[part 1 of 3: package /ComponentTypes]
AUTOSAR XML (schema 00050)
package /ComponentTypes
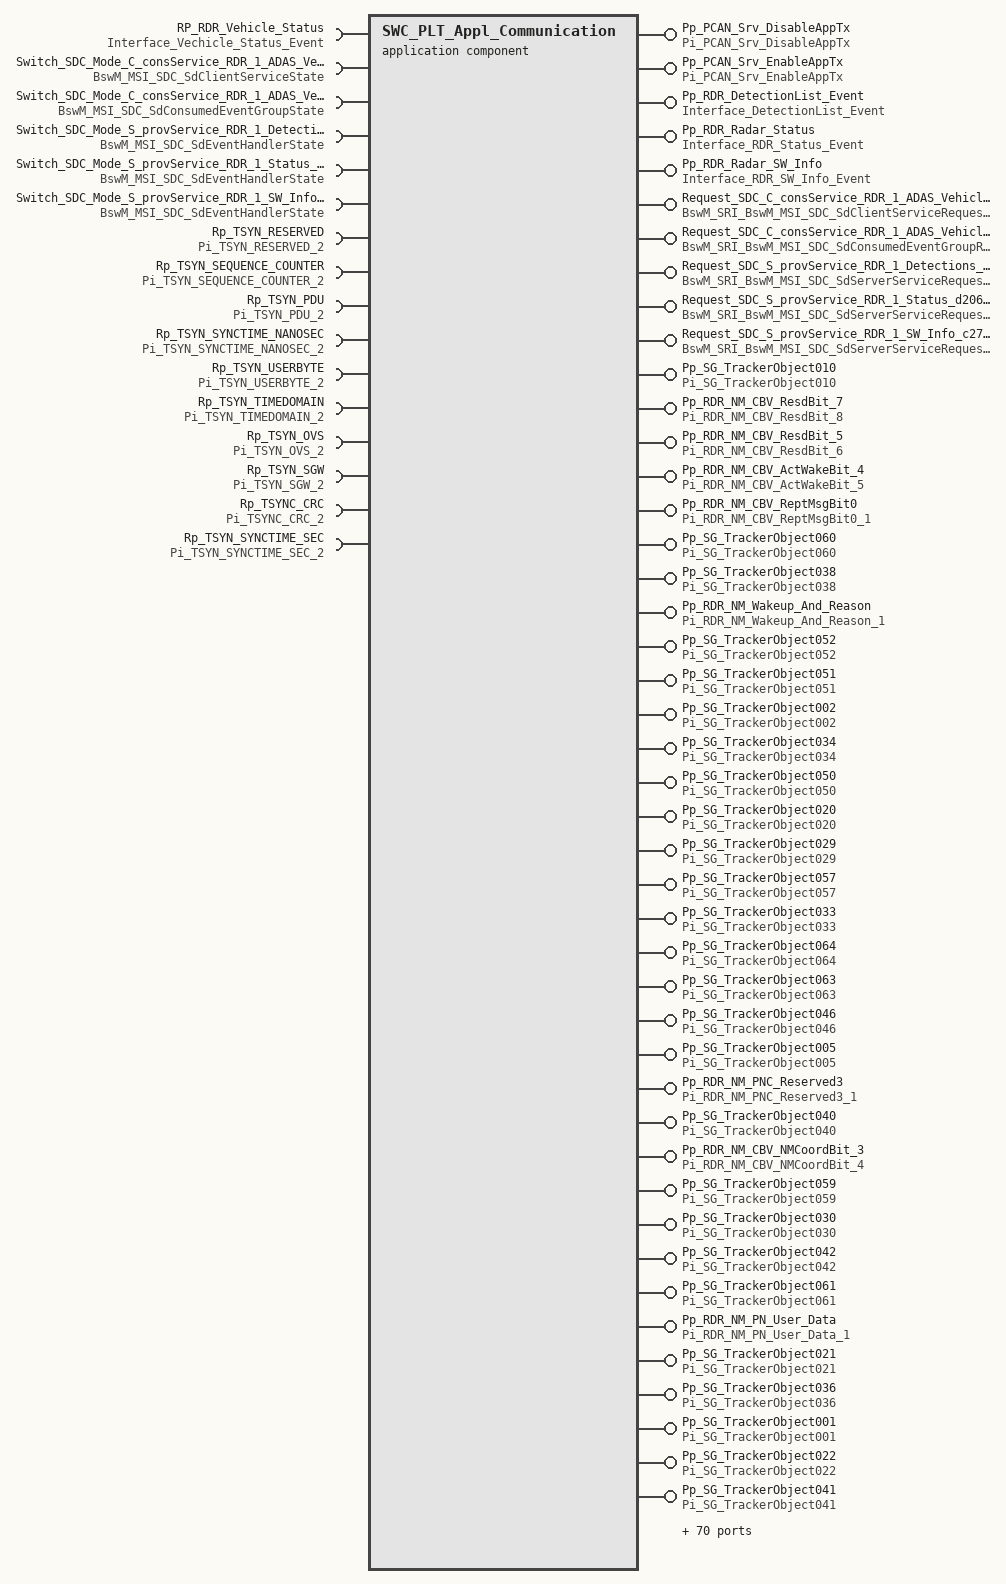
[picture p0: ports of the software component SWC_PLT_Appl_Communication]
  application sw component type SWC_PLT_Appl_Communication
    5 x provide port:
      Pp_PCAN_Srv_DisableAppTx: server-com-spec{operation=Operation, queue-length=1}, provided-interface=Pi_PCAN_Srv_DisableAppTx
      Pp_PCAN_Srv_EnableAppTx: server-com-spec{operation=Operation, queue-length=1}, provided-interface=Pi_PCAN_Srv_EnableAppTx
      Pp_RDR_DetectionList_Event: nonqueued-sender-com-spec{data-element=DetectionList_Event, init-value=fields=[{short-label=DET_HEADER_STRUCT, fields=[{short-label=HED_SENSOR_COVERAGE, fields=[HED_DET_RANGE_MAX:0, HED_DET_RANGE_MIN:0, HED_DET_SPEED_RANGE_MAX:0, HED_DET_SPEED_RANGE_MIN:0, HED_FOV_HOR_MAX:0, HED_FOV_HOR_MIN:0, HED_FOV_VER_MAX:0, HED_FOV_VER_MIN:0]}, {short-label=HED_RADAR_STATE, fields=[HED_DATA_QUALIFIER:0, HED_LOOK_ID:0, HED_LOOK_INDEX:0, HED_NUM_OF_VALID_DETECTIONS:0, HED_SCAN_INDEX:0]}, {short-label=HED_ALIGNMENT, fields=[HED_ALIGN_HOR_QF:0, HED_ALIGN_HOR_REF:0, HED_ALIGN_VER_QF:0, HED_ALIGN_VER_REF:0]}, {short-label=HED_TIMING_PROFILES, fields=[HED_AF_TIME_INST:0, HED_AF_TIME_PEAK:0, HED_MAIN_CORE_TIME_INST:0, HED_MAIN_CORE_TIME_PEAK:0, HED_RDD_CORE_TIME_INST:0, HED_RDD_CORE_TIME_PEAK:0, HED_SP_CORE_TIME_INST:0, HED_SP_CORE_TIME_PEAK:0]}, {short-label=HED_TIMESTAMP, fields=[HED_SENSOR_TIME_STAMP_NS:0, HED_SENSOR_TIME_STAMP_SEC:0, HED_TIME_SYNC_SRC_MASTER:0, HED_TIME_SYNC_VALIDITY_FLAG:0, HED_TRIGGER_TIME:0]}, {short-label=HED_DETECTION_INFO, fields=[HED_DET_BI_STATIC_COUNT:0, HED_DET_NUM_OF_1PASS:0, HED_DET_NUM_OF_2PASS:0, HED_MAX_NUM_OF_DETECTIONS:0, HED_NUM_OF_RESTBINS_USED:0, HED_OPERATION_MODE:0, HED_PROCESSED_RANGE:0, HED_SLOPE_CORR_EXECUTIONFLAG:0]}, {short-label=HED_INTERFACE_VERSION, fields=[HED_INTRFC_VERSION_ID_MAJOR:0, HED_INTRFC_VERSION_ID_MINOR:0, HED_INTRFC_VERSION_ID_PATCH:0]}]}, {short-label=DET_E2E_HDR, fields=[CRC:0, COUNTER:0, DATA_ID:0, LENGTH:0]}, DETECTIONS_ARRAY:400 x fields=[DET_AZIMUTH:0, DET_AZIMUTH_ERR:0, DET_BI_STATIC_FLAG:0, DET_CONFD_AZIMUTH:0, DET_CONFD_ELEVATION:0, DET_ELEVATION:0, DET_ELEVATION_ERR:0, DET_EXISTENCE_PROB:0, DET_HVC_FLAG:0, DET_OUTSIDE_SECTOR:0, DET_POINT_TARGET_PROB:0, DET_RANGE:0, DET_RANGE_ERR:0, DET_RANGE_VELOCITY:0, DET_RANGE_VELOCITY_ERR:0, DET_RCS:0, DET_SNR:0, DET_SUPER_RES_TARGET:0, DET_VALID_FLAG:0]]}, provided-interface=Interface_DetectionList_Event
      Pp_RDR_Radar_Status: nonqueued-sender-com-spec{data-element=RDR_Status, init-value=fields=[{short-label=STS_ALIGNMENT_HANDLER, fields=[STS_AlignmentAzimuth:0, STS_AlignmentElevation:0, STS_AlignmentError:0, STS_AlignmentModeIn:0, STS_AlignmentModeOut:0, STS_AzimuthStd:0, STS_CalDisplay:0, STS_CalTime:0, STS_CoordinateSystemInput:0, STS_ElevationStd:0, 0, 0, 0, 0, 0, 0, STS_ProgressPercent:0, STS_RadarTypeInput:0]}, {short-label=STS_ALIGNMENT_AUTO, fields=[STS_AAAzimuthStd:0, STS_AACurrentAzimuth:0, STS_AACurrentElevation:0, STS_AAElevationStd:0, STS_AlignmentAutoStatus:0, STS_AutoAlignmentFailRootCause:0, STS_AzimuthErrorNegative:0, STS_AzimuthErrorPositive:0, STS_AzimuthUpdates:0, STS_ElevationErrorNegative:0, STS_ElevationErrorPositive:0, STS_ElevationUpdates:0, STS_HostSpdCompensationFactorQF:0, STS_HostSpeedCompensationFactor:0, STS_RollErrorPositive:0, STS_StartAzimuth:0, STS_StartElevation:0]}, {short-label=STS_ALIGNMENT_STATIC, fields=[STS_AlignmentStaticStatus:0, STS_ImpactByInterference:0, STS_Measured_Range:0, STS_MeasuredRangeRate:0, STS_MeasuredRangeRateStd:0, STS_MeasuredRangeStd:0, STS_MeasuredRCS:0, STS_MeasuredRCSStd:0]}, {short-label=STS_ALIGNMENT_SERVICE, fields=[STS_AlignmentServiceStatus:0, STS_AverageNumberOfDetections:0, STS_AverageSpeed:0, STS_DistanceAbsolute:0, STS_DistanceEffective:0, STS_DurationAbsolute:0, STS_DurationEffective:0, STS_VehicleCondition:0]}, {short-label=STS_ALIGN_SHORT_TRACK, fields=STS_AlignmentShortTrackStatus:0}, {short-label=STS_CAPAB_RDR_PERF, fields=[CAP_BlockageActive:0, CAP_BlockageProbability:0, CAP_BlockageSensitivity:0, CAP_BlockageStatus:0, CAP_BlockageValue:0, CAP_FreeSightCheckActive:0, CAP_FreeSightCheckStatus:0, CAP_SLBlockageFilterValue:0, CAP_SLBlockageFlag:0]}, {short-label=STS_CAPAB_DAMPING, fields=[CAP_DampingActive:0, CAP_DampingCurrent:0, CAP_DampingStandardDeviation:0, CAP_DampingStatus:0]}, {short-label=STS_CAPAB_RANGE_DET, fields=[CAP_AngleAzimuthRangeEnd:0, CAP_AngleAzimuthRangeStart:0, CAP_MaxDetectionRangeCar:[0, 0, 0], CAP_MaxDetRangeMotorbike:[0, 0, 0], CAP_MaxDetRangePedestrian:[0, 0, 0], CAP_RangeEstimationActive:0, CAP_RangeEstimationStatus:0]}, {short-label=STS_CAPAB_SLL_MONITOR, fields=[CAP_SideLobeLevelBeamformer:0, CAP_SLLMonitoringActive:0, CAP_SLLMonitoringStatus:0]}, {short-label=STS_TIMESYNC_STATUS, fields=[STS_NO_TSYN_ERROR:0, STS_POINT_OF_TRIGGER:0, STS_TIME_SYNC_OFFSET:0]}, {short-label=STS_SENSOR_PERF, fields=STS_BRR_STATUS:0}, {short-label=STS_TEMPERATURE, fields=[STS_MCU_TEMP:0, STS_MMIC_TEMP_RX:0, STS_MMIC_TEMP_TX0:0, STS_MMIC_TEMP_TX1_2:0, STS_MMIC_TEMP_TX3_4:0]}, {short-label=STS_FAULTS, fields=STS_CORE_ACTIVE_FAULTS:0}, {short-label=STS_RADAR_PROFILE, fields=[STS_AF_CORE_THROUGHPUT:0, 0, STS_RDD_CORE_THROUGHPUT:0, STS_SCAN_TYPE:0, STS_XCVR_OPERATIONAL:0]}, {short-label=STS_VEHICLE, fields=[STS_STEERING_ANGLE:0, STS_STEERING_ANGLE_SIGN:0, STS_VEH_SPEED_DIRECTION:0, STS_VEHICLE_SPEED_CALC:0, STS_VEHICLE_SUPPLY_VOLTAGE:0, STS_YAW_RATE_BIAS:0]}, {short-label=STS_E2E_HDR, fields=[CRC:0, COUNTER:0, DATA_ID:0, LENGTH:0]}]}, provided-interface=Interface_RDR_Status_Event
      Pp_RDR_Radar_SW_Info: nonqueued-sender-com-spec{data-element=RDR_SW_Info, init-value=fields=[{short-label=INFO_CALIBRATION_VERSION, fields=[STS_SMC_CAL_VER_MAJOR:0, STS_SMC_CAL_VER_MINOR:0, STS_SMC_PLATFROM_VERSION:0, STS_SMC_SECTION_COMPTBLITY:0, STS_USC_CAL_VER_MAJOR:0, STS_USC_CAL_VER_MINOR:0, STS_USC_SECTION_COMPTBLITY:0]}, {short-label=INFO_MOUNTING_POS, fields=[STS_SENSOR_HEIGHT:0, STS_SENSOR_MOUNT_LOCATION:0, STS_SENSOR_MOUNT_ORNT_PITCH:0, STS_SENSOR_MOUNT_ORNT_ROLL:0, STS_SENSOR_MOUNT_ORNT_YAW:0, STS_SENSOR_MOUNT_POS_X:0, STS_SENSOR_MOUNT_POS_Y:0, STS_SENSOR_MOUNT_POS_Z:0, STS_SENSOR_POSITION:0]}, {short-label=INFO_SW_VERSION, fields=[STS_PBL_VERSION_FIELD1:0, STS_PBL_VERSION_FIELD2:0, STS_PBL_VERSION_FIELD3:0, STS_PBL_VERSION_FIELD4:0, STS_SW_VERSION_FIELD1:0, STS_SW_VERSION_FIELD2:0, STS_SW_VERSION_FIELD3:0, STS_SW_VERSION_FIELD4:0]}, {short-label=INFO_HW_CAN_VERSION, fields=[STS_DET_DBC_BASE_VER_MAJOR:0, STS_DET_DBC_BASE_VER_MINOR:0, STS_HARDWARE_VERSION:0, STS_PCAN_PROTOCOL_VER_MAJOR:0, STS_PCAN_PROTOCOL_VER_MINOR:0, STS_PLATFORM_VARIANT:0, STS_SERIAL_NUM_JULIAN_DAY:0, STS_SERIAL_NUM_JULIAN_YEAR:0, STS_SERIAL_NUMBER_SEQUENCE:0]}, {short-label=INFO_E2E_HDR, fields=[CRC:0, COUNTER:0, DATA_ID:0, LENGTH:0]}]}, provided-interface=Interface_RDR_SW_Info_Event
    require port RP_RDR_Vehicle_Status: nonqueued-receiver-com-spec{data-element=Vehicle_Status, filter=data-filter-type=ALWAYS, init-value=fields=[{short-label=System_Status_Vehicle, fields=[SSTS_STEERING_ANGLE:0, SSTS_STEERING_ANGLE_SIGN:0, SSTS_VEH_ODOMETER:0, SSTS_VEH_POWER_MODE_STATUS:0, SSTS_VEH_SPD_COMP_FACTOR:0, SSTS_VEH_SYSTEM_VOLTAGE:0, SSTS_VEHICLE_SPEED_CALC:0, SSTS_VEHICLE_SPEED_CALC_QF:0, SSTS_VEHICLE_STATE:0, SSTS_YAW_RATE_BIAS:0, SSTS_YAW_RATE_CALC:0, SSTS_YAW_RATE_CALC_QF:0]}, {short-label=System_Status_Vehicle_State, fields=[SSTS_DRIVE_DIR:0, SSTS_DRIVE_REVERSE:0, SSTS_GEAR_POSITION:0, SSTS_IGN_STATUS:0, SSTS_LROS_DRIVE_DIR:0, SSTS_LROS_DRIVE_REVERSE:0]}, {short-label=System_Status_ADAS_Version, fields=[SSTS_CAN_PCAN_MINOR_ADAS:0, SSTS_CAN_PCAN_MAJOR_ADAS:0, SSTS_SW_VERSION_ADAS:0]}, {short-label=System_Status_Absolute_Time, fields=[SSTS_VEH_AbsoluteTime_Day:0, SSTS_VEH_AbsoluteTime_Hour:0, SSTS_VEH_AbsoluteTime_Minute:0, SSTS_VEH_AbsoluteTime_Month:0, SSTS_VEH_AbsoluteTime_Second:0, SSTS_VEH_AbsoluteTime_Year:0]}, {short-label=SSTS_E2E_HDR, fields=[CRC:0, COUNTER:0, DATA_ID:0, LENGTH:0]}]}, required-interface=Interface_Vechicle_Status_Event
    5 x provide port, all with nonqueued-sender-com-spec=data-element=requestedMode:
      Request_SDC_C_consService_RDR_1_ADAS_Vehicle_Status_2b1e055b: provided-interface=BswM_SRI_BswM_MSI_SDC_SdClientServiceRequest_BswM_MDGP_SDC_SdClientServiceRequest
      Request_SDC_C_consService_RDR_1_ADAS_Vehicle_Status_2b1e055b_CEG_consServiceGrp_RDR_1_ADAS_Vehicle_Status_4b79da85: provided-interface=BswM_SRI_BswM_MSI_SDC_SdConsumedEventGroupRequest_BswM_MDGP_SDC_SdConsumedEventGroupRequest
      Request_SDC_S_provService_RDR_1_Detections_89f78c9f: provided-interface=BswM_SRI_BswM_MSI_SDC_SdServerServiceRequest_BswM_MDGP_SDC_SdServerServiceRequest
      Request_SDC_S_provService_RDR_1_Status_d2069d01: provided-interface=BswM_SRI_BswM_MSI_SDC_SdServerServiceRequest_BswM_MDGP_SDC_SdServerServiceRequest
      Request_SDC_S_provService_RDR_1_SW_Info_c2745ec9: provided-interface=BswM_SRI_BswM_MSI_SDC_SdServerServiceRequest_BswM_MDGP_SDC_SdServerServiceRequest
    15 x require port:
      Switch_SDC_Mode_C_consService_RDR_1_ADAS_Vehicle_Status_2b1e055b: mode-switch-receiver-com-spec=BswM_MDGP_SDC_SdClientServiceState, required-interface=BswM_MSI_SDC_SdClientServiceState
      Switch_SDC_Mode_C_consService_RDR_1_ADAS_Vehicle_Status_2b1e055b_CEG_consServiceGrp_RDR_1_ADAS_Vehicle_Status_4b79da85: mode-switch-receiver-com-spec=BswM_MDGP_SDC_SdConsumedEventGroupState, required-interface=BswM_MSI_SDC_SdConsumedEventGroupState
      Switch_SDC_Mode_S_provService_RDR_1_Detections_89f78c9f_EH_EventGroup_RDR_1_ca62382d: mode-switch-receiver-com-spec=BswM_MDGP_SDC_SdEventHandlerState, required-interface=BswM_MSI_SDC_SdEventHandlerState
      Switch_SDC_Mode_S_provService_RDR_1_Status_d2069d01_EH_EventGroup_RDR_1_f7c73cae: mode-switch-receiver-com-spec=BswM_MDGP_SDC_SdEventHandlerState, required-interface=BswM_MSI_SDC_SdEventHandlerState
      Switch_SDC_Mode_S_provService_RDR_1_SW_Info_c2745ec9_EH_EventGroup_RDR_1_653e2581: mode-switch-receiver-com-spec=BswM_MDGP_SDC_SdEventHandlerState, required-interface=BswM_MSI_SDC_SdEventHandlerState
      Rp_TSYN_RESERVED: nonqueued-receiver-com-spec{data-element=Vdp_TSYN_RESERVED, init-value=0}, required-interface=Pi_TSYN_RESERVED_2
      Rp_TSYN_SEQUENCE_COUNTER: nonqueued-receiver-com-spec{data-element=Vdp_TSYN_SEQUENCE_COUNTER, init-value=0}, required-interface=Pi_TSYN_SEQUENCE_COUNTER_2
      Rp_TSYN_PDU: nonqueued-receiver-com-spec{data-element=Vdp_TSYN_PDU, init-value=40}, required-interface=Pi_TSYN_PDU_2
      Rp_TSYN_SYNCTIME_NANOSEC: nonqueued-receiver-com-spec{data-element=Vdp_TSYN_SYNCTIME_NANOSEC, init-value=0}, required-interface=Pi_TSYN_SYNCTIME_NANOSEC_2
      Rp_TSYN_USERBYTE: nonqueued-receiver-com-spec{data-element=Vdp_TSYN_USERBYTE, init-value=0}, required-interface=Pi_TSYN_USERBYTE_2
      Rp_TSYN_TIMEDOMAIN: nonqueued-receiver-com-spec{data-element=Vdp_TSYN_TIMEDOMAIN, init-value=0}, required-interface=Pi_TSYN_TIMEDOMAIN_2
      Rp_TSYN_OVS: nonqueued-receiver-com-spec{data-element=Vdp_TSYN_OVS, init-value=0}, required-interface=Pi_TSYN_OVS_2
      Rp_TSYN_SGW: nonqueued-receiver-com-spec{data-element=Vdp_TSYN_SGW, init-value=0}, required-interface=Pi_TSYN_SGW_2
      Rp_TSYNC_CRC: nonqueued-receiver-com-spec{data-element=Vdp_TSYNC_CRC, init-value=0}, required-interface=Pi_TSYNC_CRC_2
      Rp_TSYN_SYNCTIME_SEC: nonqueued-receiver-com-spec{data-element=Vdp_TSYN_SYNCTIME_SEC, init-value=0}, required-interface=Pi_TSYN_SYNCTIME_SEC_2
    182 x provide port:
      Pp_SG_TrackerObject010: nonqueued-sender-com-spec{data-element=Vdp_SG_TrackerObject010, init-value=fields=[OBJ_ACCEL_ERR_CRR_COEF_010:120, OBJ_ACCELERATION_LAT_010:400, OBJ_ACCELERATION_LAT_ERR_010:0, OBJ_ACCELERATION_LONG_010:400, OBJ_ACCELERATION_LONG_ERR_010:0, OBJ_ALIVE_TIME_010:0, OBJ_CLS_TYPE1_010:0, OBJ_CLS_TYPE1_PROB_010:0, OBJ_CLS_TYPE2_010:0, OBJ_CLS_TYPE2_PROB_010:0, OBJ_CLS_TYPE3_010:0, OBJ_CLS_TYPE3_PROB_010:0, OBJ_CLS_TYPE4_010:0, OBJ_CLS_TYPE4_PROB_010:0, OBJ_CLS_TYPE5_010:0, OBJ_CLS_TYPE5_PROB_010:0, OBJ_CLS_TYPE6_010:0, OBJ_CLS_TYPE6_PROB_010:0, OBJ_DIMENSION_LENGTH_010:0, OBJ_DIMENSION_LENGTH_ERR_010:0, OBJ_DIMENSION_WIDTH_010:0, OBJ_DIMENSION_WIDTH_ERR_010:0, OBJ_EXISTENCE_PROB_010:0, OBJ_GROUP_ID_010:0, OBJ_ID_010:0, OBJ_MEASUREMENT_STATUS_010:0, OBJ_MH_CRC16_010:0, OBJ_MH_CYCLE_COUNTER_010:0, OBJ_MOVEMENT_STATUS_010:0, OBJ_POS_ERR_CRR_COEF_010:120, OBJ_POS_LAT_010:32700, OBJ_POS_LAT_ERR_010:0, OBJ_POS_LONG_010:32700, OBJ_POS_LONG_ERR_010:0, OBJ_RCS_010:64, OBJ_REF_PT_LAT_OFFSET_010:0, OBJ_REF_PT_LONG_OFFSET_010:0, OBJ_TIMESTAMP_OFFSET_010:127, OBJ_TRACK_MOTION_MODEL_010:0, OBJ_VEH_TRACK_FLAG_010:0, OBJ_VELOCITY_ERR_CRR_COEF_010:120, OBJ_VELOCITY_LAT_010:16300, OBJ_VELOCITY_LAT_ERR_010:0, OBJ_VELOCITY_LONG_010:16300, OBJ_VELOCITY_LONG_ERR_010:0, OBJ_YAW_ANGLE_010:2000, OBJ_YAW_ANGLE_ERR_010:0, OBJ_YAW_RATE_010:448, OBJ_YAW_RATE_ERR_010:0]}, provided-interface=Pi_SG_TrackerObject010
      Pp_RDR_NM_CBV_ResdBit_7: nonqueued-sender-com-spec{data-element=Vdp_RDR_NM_CBV_ResdBit_7, init-value=0}, provided-interface=Pi_RDR_NM_CBV_ResdBit_8
      Pp_RDR_NM_CBV_ResdBit_5: nonqueued-sender-com-spec{data-element=Vdp_RDR_NM_CBV_ResdBit_5, init-value=0}, provided-interface=Pi_RDR_NM_CBV_ResdBit_6
      Pp_RDR_NM_CBV_ActWakeBit_4: nonqueued-sender-com-spec{data-element=Vdp_RDR_NM_CBV_ActWakeBit_4, init-value=0}, provided-interface=Pi_RDR_NM_CBV_ActWakeBit_5
      Pp_RDR_NM_CBV_ReptMsgBit0: nonqueued-sender-com-spec{data-element=Vdp_RDR_NM_CBV_ReptMsgBit0, init-value=0}, provided-interface=Pi_RDR_NM_CBV_ReptMsgBit0_1
      Pp_SG_TrackerObject060: nonqueued-sender-com-spec{data-element=Vdp_SG_TrackerObject060, init-value=fields=[OBJ_ACCEL_ERR_CRR_COEF_060:120, OBJ_ACCELERATION_LAT_060:400, OBJ_ACCELERATION_LAT_ERR_060:0, OBJ_ACCELERATION_LONG_060:400, OBJ_ACCELERATION_LONG_ERR_060:0, OBJ_ALIVE_TIME_060:0, OBJ_CLS_TYPE1_060:0, OBJ_CLS_TYPE1_PROB_060:0, OBJ_CLS_TYPE2_060:0, OBJ_CLS_TYPE2_PROB_060:0, OBJ_CLS_TYPE3_060:0, OBJ_CLS_TYPE3_PROB_060:0, OBJ_CLS_TYPE4_060:0, OBJ_CLS_TYPE4_PROB_060:0, OBJ_CLS_TYPE5_060:0, OBJ_CLS_TYPE5_PROB_060:0, OBJ_CLS_TYPE6_060:0, OBJ_CLS_TYPE6_PROB_060:0, OBJ_DIMENSION_LENGTH_060:0, OBJ_DIMENSION_LENGTH_ERR_060:0, OBJ_DIMENSION_WIDTH_060:0, OBJ_DIMENSION_WIDTH_ERR_060:0, OBJ_EXISTENCE_PROB_060:0, OBJ_GROUP_ID_060:0, OBJ_ID_060:0, OBJ_MEASUREMENT_STATUS_060:0, OBJ_MH_CRC16_060:0, OBJ_MH_CYCLE_COUNTER_060:0, OBJ_MOVEMENT_STATUS_060:0, OBJ_POS_ERR_CRR_COEF_060:120, OBJ_POS_LAT_060:32700, OBJ_POS_LAT_ERR_060:0, OBJ_POS_LONG_060:32700, OBJ_POS_LONG_ERR_060:0, OBJ_RCS_060:64, OBJ_REF_PT_LAT_OFFSET_060:0, OBJ_REF_PT_LONG_OFFSET_060:0, OBJ_TIMESTAMP_OFFSET_060:127, OBJ_TRACK_MOTION_MODEL_060:0, OBJ_VEH_TRACK_FLAG_060:0, OBJ_VELOCITY_ERR_CRR_COEF_060:120, OBJ_VELOCITY_LAT_060:16300, OBJ_VELOCITY_LAT_ERR_060:0, OBJ_VELOCITY_LONG_060:16300, OBJ_VELOCITY_LONG_ERR_060:0, OBJ_YAW_ANGLE_060:2000, OBJ_YAW_ANGLE_ERR_060:0, OBJ_YAW_RATE_060:448, OBJ_YAW_RATE_ERR_060:0]}, provided-interface=Pi_SG_TrackerObject060
      Pp_SG_TrackerObject038: nonqueued-sender-com-spec{data-element=Vdp_SG_TrackerObject038, init-value=fields=[OBJ_ACCEL_ERR_CRR_COEF_038:120, OBJ_ACCELERATION_LAT_038:400, OBJ_ACCELERATION_LAT_ERR_038:0, OBJ_ACCELERATION_LONG_038:400, OBJ_ACCELERATION_LONG_ERR_038:0, OBJ_ALIVE_TIME_038:0, OBJ_CLS_TYPE1_038:0, OBJ_CLS_TYPE1_PROB_038:0, OBJ_CLS_TYPE2_038:0, OBJ_CLS_TYPE2_PROB_038:0, OBJ_CLS_TYPE3_038:0, OBJ_CLS_TYPE3_PROB_038:0, OBJ_CLS_TYPE4_038:0, OBJ_CLS_TYPE4_PROB_038:0, OBJ_CLS_TYPE5_038:0, OBJ_CLS_TYPE5_PROB_038:0, OBJ_CLS_TYPE6_038:0, OBJ_CLS_TYPE6_PROB_038:0, OBJ_DIMENSION_LENGTH_038:0, OBJ_DIMENSION_LENGTH_ERR_038:0, OBJ_DIMENSION_WIDTH_038:0, OBJ_DIMENSION_WIDTH_ERR_038:0, OBJ_EXISTENCE_PROB_038:0, OBJ_GROUP_ID_038:0, OBJ_ID_038:0, OBJ_MEASUREMENT_STATUS_038:0, OBJ_MH_CRC16_038:0, OBJ_MH_CYCLE_COUNTER_038:0, OBJ_MOVEMENT_STATUS_038:0, OBJ_POS_ERR_CRR_COEF_038:120, OBJ_POS_LAT_038:32700, OBJ_POS_LAT_ERR_038:0, OBJ_POS_LONG_038:32700, OBJ_POS_LONG_ERR_038:0, OBJ_RCS_038:64, OBJ_REF_PT_LAT_OFFSET_038:0, OBJ_REF_PT_LONG_OFFSET_038:0, OBJ_TIMESTAMP_OFFSET_038:127, OBJ_TRACK_MOTION_MODEL_038:0, OBJ_VEH_TRACK_FLAG_038:0, OBJ_VELOCITY_ERR_CRR_COEF_038:120, OBJ_VELOCITY_LAT_038:16300, OBJ_VELOCITY_LAT_ERR_038:0, OBJ_VELOCITY_LONG_038:16300, OBJ_VELOCITY_LONG_ERR_038:0, OBJ_YAW_ANGLE_038:2000, OBJ_YAW_ANGLE_ERR_038:0, OBJ_YAW_RATE_038:448, OBJ_YAW_RATE_ERR_038:0]}, provided-interface=Pi_SG_TrackerObject038
      Pp_RDR_NM_Wakeup_And_Reason: nonqueued-sender-com-spec{data-element=Vdp_RDR_NM_Wakeup_And_Reason, init-value=0}, provided-interface=Pi_RDR_NM_Wakeup_And_Reason_1
      Pp_SG_TrackerObject052: nonqueued-sender-com-spec{data-element=Vdp_SG_TrackerObject052, init-value=fields=[OBJ_ACCEL_ERR_CRR_COEF_052:120, OBJ_ACCELERATION_LAT_052:400, OBJ_ACCELERATION_LAT_ERR_052:0, OBJ_ACCELERATION_LONG_052:400, OBJ_ACCELERATION_LONG_ERR_052:0, OBJ_ALIVE_TIME_052:0, OBJ_CLS_TYPE1_052:0, OBJ_CLS_TYPE1_PROB_052:0, OBJ_CLS_TYPE2_052:0, OBJ_CLS_TYPE2_PROB_052:0, OBJ_CLS_TYPE3_052:0, OBJ_CLS_TYPE3_PROB_052:0, OBJ_CLS_TYPE4_052:0, OBJ_CLS_TYPE4_PROB_052:0, OBJ_CLS_TYPE5_052:0, OBJ_CLS_TYPE5_PROB_052:0, OBJ_CLS_TYPE6_052:0, OBJ_CLS_TYPE6_PROB_052:0, OBJ_DIMENSION_LENGTH_052:0, OBJ_DIMENSION_LENGTH_ERR_052:0, OBJ_DIMENSION_WIDTH_052:0, OBJ_DIMENSION_WIDTH_ERR_052:0, OBJ_EXISTENCE_PROB_052:0, OBJ_GROUP_ID_052:0, OBJ_ID_052:0, OBJ_MEASUREMENT_STATUS_052:0, OBJ_MH_CRC16_052:0, OBJ_MH_CYCLE_COUNTER_052:0, OBJ_MOVEMENT_STATUS_052:0, OBJ_POS_ERR_CRR_COEF_052:120, OBJ_POS_LAT_052:32700, OBJ_POS_LAT_ERR_052:0, OBJ_POS_LONG_052:32700, OBJ_POS_LONG_ERR_052:0, OBJ_RCS_052:64, OBJ_REF_PT_LAT_OFFSET_052:0, OBJ_REF_PT_LONG_OFFSET_052:0, OBJ_TIMESTAMP_OFFSET_052:127, OBJ_TRACK_MOTION_MODEL_052:0, OBJ_VEH_TRACK_FLAG_052:0, OBJ_VELOCITY_ERR_CRR_COEF_052:120, OBJ_VELOCITY_LAT_052:16300, OBJ_VELOCITY_LAT_ERR_052:0, OBJ_VELOCITY_LONG_052:16300, OBJ_VELOCITY_LONG_ERR_052:0, OBJ_YAW_ANGLE_052:2000, OBJ_YAW_ANGLE_ERR_052:0, OBJ_YAW_RATE_052:448, OBJ_YAW_RATE_ERR_052:0]}, provided-interface=Pi_SG_TrackerObject052
      Pp_SG_TrackerObject051: nonqueued-sender-com-spec{data-element=Vdp_SG_TrackerObject051, init-value=fields=[OBJ_ACCEL_ERR_CRR_COEF_051:120, OBJ_ACCELERATION_LAT_051:400, OBJ_ACCELERATION_LAT_ERR_051:0, OBJ_ACCELERATION_LONG_051:400, OBJ_ACCELERATION_LONG_ERR_051:0, OBJ_ALIVE_TIME_051:0, OBJ_CLS_TYPE1_051:0, OBJ_CLS_TYPE1_PROB_051:0, OBJ_CLS_TYPE2_051:0, OBJ_CLS_TYPE2_PROB_051:0, OBJ_CLS_TYPE3_051:0, OBJ_CLS_TYPE3_PROB_051:0, OBJ_CLS_TYPE4_051:0, OBJ_CLS_TYPE4_PROB_051:0, OBJ_CLS_TYPE5_051:0, OBJ_CLS_TYPE5_PROB_051:0, OBJ_CLS_TYPE6_051:0, OBJ_CLS_TYPE6_PROB_051:0, OBJ_DIMENSION_LENGTH_051:0, OBJ_DIMENSION_LENGTH_ERR_051:0, OBJ_DIMENSION_WIDTH_051:0, OBJ_DIMENSION_WIDTH_ERR_051:0, OBJ_EXISTENCE_PROB_051:0, OBJ_GROUP_ID_051:0, OBJ_ID_051:0, OBJ_MEASUREMENT_STATUS_051:0, OBJ_MH_CRC16_051:0, OBJ_MH_CYCLE_COUNTER_051:0, OBJ_MOVEMENT_STATUS_051:0, OBJ_POS_ERR_CRR_COEF_051:120, OBJ_POS_LAT_051:32700, OBJ_POS_LAT_ERR_051:0, OBJ_POS_LONG_051:32700, OBJ_POS_LONG_ERR_051:0, OBJ_RCS_051:64, OBJ_REF_PT_LAT_OFFSET_051:0, OBJ_REF_PT_LONG_OFFSET_051:0, OBJ_TIMESTAMP_OFFSET_051:127, OBJ_TRACK_MOTION_MODEL_051:0, OBJ_VEH_TRACK_FLAG_051:0, OBJ_VELOCITY_ERR_CRR_COEF_051:120, OBJ_VELOCITY_LAT_051:16300, OBJ_VELOCITY_LAT_ERR_051:0, OBJ_VELOCITY_LONG_051:16300, OBJ_VELOCITY_LONG_ERR_051:0, OBJ_YAW_ANGLE_051:2000, OBJ_YAW_ANGLE_ERR_051:0, OBJ_YAW_RATE_051:448, OBJ_YAW_RATE_ERR_051:0]}, provided-interface=Pi_SG_TrackerObject051
      Pp_SG_TrackerObject002: nonqueued-sender-com-spec{data-element=Vdp_SG_TrackerObject002, init-value=fields=[OBJ_ACCEL_ERR_CRR_COEF_002:120, OBJ_ACCELERATION_LAT_002:400, OBJ_ACCELERATION_LAT_ERR_002:0, OBJ_ACCELERATION_LONG_002:400, OBJ_ACCELERATION_LONG_ERR_002:0, OBJ_ALIVE_TIME_002:0, OBJ_CLS_TYPE1_002:0, OBJ_CLS_TYPE1_PROB_002:0, OBJ_CLS_TYPE2_002:0, OBJ_CLS_TYPE2_PROB_002:0, OBJ_CLS_TYPE3_002:0, OBJ_CLS_TYPE3_PROB_002:0, OBJ_CLS_TYPE4_002:0, OBJ_CLS_TYPE4_PROB_002:0, OBJ_CLS_TYPE5_002:0, OBJ_CLS_TYPE5_PROB_002:0, OBJ_CLS_TYPE6_002:0, OBJ_CLS_TYPE6_PROB_002:0, OBJ_DIMENSION_LENGTH_002:0, OBJ_DIMENSION_LENGTH_ERR_002:0, OBJ_DIMENSION_WIDTH_002:0, OBJ_DIMENSION_WIDTH_ERR_002:0, OBJ_EXISTENCE_PROB_002:0, OBJ_GROUP_ID_002:0, OBJ_ID_002:0, OBJ_MEASUREMENT_STATUS_002:0, OBJ_MH_CRC16_002:0, OBJ_MH_CYCLE_COUNTER_002:0, OBJ_MOVEMENT_STATUS_002:0, OBJ_POS_ERR_CRR_COEF_002:120, OBJ_POS_LAT_002:32700, OBJ_POS_LAT_ERR_002:0, OBJ_POS_LONG_002:32700, OBJ_POS_LONG_ERR_002:0, OBJ_RCS_002:64, OBJ_REF_PT_LAT_OFFSET_002:0, OBJ_REF_PT_LONG_OFFSET_002:0, OBJ_TIMESTAMP_OFFSET_002:127, OBJ_TRACK_MOTION_MODEL_002:0, OBJ_VEH_TRACK_FLAG_002:0, OBJ_VELOCITY_ERR_CRR_COEF_002:120, OBJ_VELOCITY_LAT_002:16300, OBJ_VELOCITY_LAT_ERR_002:0, OBJ_VELOCITY_LONG_002:16300, OBJ_VELOCITY_LONG_ERR_002:0, OBJ_YAW_ANGLE_002:2000, OBJ_YAW_ANGLE_ERR_002:0, OBJ_YAW_RATE_002:448, OBJ_YAW_RATE_ERR_002:0]}, provided-interface=Pi_SG_TrackerObject002
      Pp_SG_TrackerObject034: nonqueued-sender-com-spec{data-element=Vdp_SG_TrackerObject034, init-value=fields=[OBJ_ACCEL_ERR_CRR_COEF_034:120, OBJ_ACCELERATION_LAT_034:400, OBJ_ACCELERATION_LAT_ERR_034:0, OBJ_ACCELERATION_LONG_034:400, OBJ_ACCELERATION_LONG_ERR_034:0, OBJ_ALIVE_TIME_034:0, OBJ_CLS_TYPE1_034:0, OBJ_CLS_TYPE1_PROB_034:0, OBJ_CLS_TYPE2_034:0, OBJ_CLS_TYPE2_PROB_034:0, OBJ_CLS_TYPE3_034:0, OBJ_CLS_TYPE3_PROB_034:0, OBJ_CLS_TYPE4_034:0, OBJ_CLS_TYPE4_PROB_034:0, OBJ_CLS_TYPE5_034:0, OBJ_CLS_TYPE5_PROB_034:0, OBJ_CLS_TYPE6_034:0, OBJ_CLS_TYPE6_PROB_034:0, OBJ_DIMENSION_LENGTH_034:0, OBJ_DIMENSION_LENGTH_ERR_034:0, OBJ_DIMENSION_WIDTH_034:0, OBJ_DIMENSION_WIDTH_ERR_034:0, OBJ_EXISTENCE_PROB_034:0, OBJ_GROUP_ID_034:0, OBJ_ID_034:0, OBJ_MEASUREMENT_STATUS_034:0, OBJ_MH_CRC16_034:0, OBJ_MH_CYCLE_COUNTER_034:0, OBJ_MOVEMENT_STATUS_034:0, OBJ_POS_ERR_CRR_COEF_034:120, OBJ_POS_LAT_034:32700, OBJ_POS_LAT_ERR_034:0, OBJ_POS_LONG_034:32700, OBJ_POS_LONG_ERR_034:0, OBJ_RCS_034:64, OBJ_REF_PT_LAT_OFFSET_034:0, OBJ_REF_PT_LONG_OFFSET_034:0, OBJ_TIMESTAMP_OFFSET_034:127, OBJ_TRACK_MOTION_MODEL_034:0, OBJ_VEH_TRACK_FLAG_034:0, OBJ_VELOCITY_ERR_CRR_COEF_034:120, OBJ_VELOCITY_LAT_034:16300, OBJ_VELOCITY_LAT_ERR_034:0, OBJ_VELOCITY_LONG_034:16300, OBJ_VELOCITY_LONG_ERR_034:0, OBJ_YAW_ANGLE_034:2000, OBJ_YAW_ANGLE_ERR_034:0, OBJ_YAW_RATE_034:448, OBJ_YAW_RATE_ERR_034:0]}, provided-interface=Pi_SG_TrackerObject034
      Pp_SG_TrackerObject050: nonqueued-sender-com-spec{data-element=Vdp_SG_TrackerObject050, init-value=fields=[OBJ_ACCEL_ERR_CRR_COEF_050:120, OBJ_ACCELERATION_LAT_050:400, OBJ_ACCELERATION_LAT_ERR_050:0, OBJ_ACCELERATION_LONG_050:400, OBJ_ACCELERATION_LONG_ERR_050:0, OBJ_ALIVE_TIME_050:0, OBJ_CLS_TYPE1_050:0, OBJ_CLS_TYPE1_PROB_050:0, OBJ_CLS_TYPE2_050:0, OBJ_CLS_TYPE2_PROB_050:0, OBJ_CLS_TYPE3_050:0, OBJ_CLS_TYPE3_PROB_050:0, OBJ_CLS_TYPE4_050:0, OBJ_CLS_TYPE4_PROB_050:0, OBJ_CLS_TYPE5_050:0, OBJ_CLS_TYPE5_PROB_050:0, OBJ_CLS_TYPE6_050:0, OBJ_CLS_TYPE6_PROB_050:0, OBJ_DIMENSION_LENGTH_050:0, OBJ_DIMENSION_LENGTH_ERR_050:0, OBJ_DIMENSION_WIDTH_050:0, OBJ_DIMENSION_WIDTH_ERR_050:0, OBJ_EXISTENCE_PROB_050:0, OBJ_GROUP_ID_050:0, OBJ_ID_050:0, OBJ_MEASUREMENT_STATUS_050:0, OBJ_MH_CRC16_050:0, OBJ_MH_CYCLE_COUNTER_050:0, OBJ_MOVEMENT_STATUS_050:0, OBJ_POS_ERR_CRR_COEF_050:120, OBJ_POS_LAT_050:32700, OBJ_POS_LAT_ERR_050:0, OBJ_POS_LONG_050:32700, OBJ_POS_LONG_ERR_050:0, OBJ_RCS_050:64, OBJ_REF_PT_LAT_OFFSET_050:0, OBJ_REF_PT_LONG_OFFSET_050:0, OBJ_TIMESTAMP_OFFSET_050:127, OBJ_TRACK_MOTION_MODEL_050:0, OBJ_VEH_TRACK_FLAG_050:0, OBJ_VELOCITY_ERR_CRR_COEF_050:120, OBJ_VELOCITY_LAT_050:16300, OBJ_VELOCITY_LAT_ERR_050:0, OBJ_VELOCITY_LONG_050:16300, OBJ_VELOCITY_LONG_ERR_050:0, OBJ_YAW_ANGLE_050:2000, OBJ_YAW_ANGLE_ERR_050:0, OBJ_YAW_RATE_050:448, OBJ_YAW_RATE_ERR_050:0]}, provided-interface=Pi_SG_TrackerObject050
      Pp_SG_TrackerObject020: nonqueued-sender-com-spec{data-element=Vdp_SG_TrackerObject020, init-value=fields=[OBJ_ACCEL_ERR_CRR_COEF_020:120, OBJ_ACCELERATION_LAT_020:400, OBJ_ACCELERATION_LAT_ERR_020:0, OBJ_ACCELERATION_LONG_020:400, OBJ_ACCELERATION_LONG_ERR_020:0, OBJ_ALIVE_TIME_020:0, OBJ_CLS_TYPE1_020:0, OBJ_CLS_TYPE1_PROB_020:0, OBJ_CLS_TYPE2_020:0, OBJ_CLS_TYPE2_PROB_020:0, OBJ_CLS_TYPE3_020:0, OBJ_CLS_TYPE3_PROB_020:0, OBJ_CLS_TYPE4_020:0, OBJ_CLS_TYPE4_PROB_020:0, OBJ_CLS_TYPE5_020:0, OBJ_CLS_TYPE5_PROB_020:0, OBJ_CLS_TYPE6_020:0, OBJ_CLS_TYPE6_PROB_020:0, OBJ_DIMENSION_LENGTH_020:0, OBJ_DIMENSION_LENGTH_ERR_020:0, OBJ_DIMENSION_WIDTH_020:0, OBJ_DIMENSION_WIDTH_ERR_020:0, OBJ_EXISTENCE_PROB_020:0, OBJ_GROUP_ID_020:0, OBJ_ID_020:0, OBJ_MEASUREMENT_STATUS_020:0, OBJ_MH_CRC16_020:0, OBJ_MH_CYCLE_COUNTER_020:0, OBJ_MOVEMENT_STATUS_020:0, OBJ_POS_ERR_CRR_COEF_020:120, OBJ_POS_LAT_020:32700, OBJ_POS_LAT_ERR_020:0, OBJ_POS_LONG_020:32700, OBJ_POS_LONG_ERR_020:0, OBJ_RCS_020:64, OBJ_REF_PT_LAT_OFFSET_020:0, OBJ_REF_PT_LONG_OFFSET_020:0, OBJ_TIMESTAMP_OFFSET_020:127, OBJ_TRACK_MOTION_MODEL_020:0, OBJ_VEH_TRACK_FLAG_020:0, OBJ_VELOCITY_ERR_CRR_COEF_020:120, OBJ_VELOCITY_LAT_020:16300, OBJ_VELOCITY_LAT_ERR_020:0, OBJ_VELOCITY_LONG_020:16300, OBJ_VELOCITY_LONG_ERR_020:0, OBJ_YAW_ANGLE_020:2000, OBJ_YAW_ANGLE_ERR_020:0, OBJ_YAW_RATE_020:448, OBJ_YAW_RATE_ERR_020:0]}, provided-interface=Pi_SG_TrackerObject020
      Pp_SG_TrackerObject029: nonqueued-sender-com-spec{data-element=Vdp_SG_TrackerObject029, init-value=fields=[OBJ_ACCEL_ERR_CRR_COEF_029:120, OBJ_ACCELERATION_LAT_029:400, OBJ_ACCELERATION_LAT_ERR_029:0, OBJ_ACCELERATION_LONG_029:400, OBJ_ACCELERATION_LONG_ERR_029:0, OBJ_ALIVE_TIME_029:0, OBJ_CLS_TYPE1_029:0, OBJ_CLS_TYPE1_PROB_029:0, OBJ_CLS_TYPE2_029:0, OBJ_CLS_TYPE2_PROB_029:0, OBJ_CLS_TYPE3_029:0, OBJ_CLS_TYPE3_PROB_029:0, OBJ_CLS_TYPE4_029:0, OBJ_CLS_TYPE4_PROB_029:0, OBJ_CLS_TYPE5_029:0, OBJ_CLS_TYPE5_PROB_029:0, OBJ_CLS_TYPE6_029:0, OBJ_CLS_TYPE6_PROB_029:0, OBJ_DIMENSION_LENGTH_029:0, OBJ_DIMENSION_LENGTH_ERR_029:0, OBJ_DIMENSION_WIDTH_029:0, OBJ_DIMENSION_WIDTH_ERR_029:0, OBJ_EXISTENCE_PROB_029:0, OBJ_GROUP_ID_029:0, OBJ_ID_029:0, OBJ_MEASUREMENT_STATUS_029:0, OBJ_MH_CRC16_029:0, OBJ_MH_CYCLE_COUNTER_029:0, OBJ_MOVEMENT_STATUS_029:0, OBJ_POS_ERR_CRR_COEF_029:120, OBJ_POS_LAT_029:32700, OBJ_POS_LAT_ERR_029:0, OBJ_POS_LONG_029:32700, OBJ_POS_LONG_ERR_029:0, OBJ_RCS_029:64, OBJ_REF_PT_LAT_OFFSET_029:0, OBJ_REF_PT_LONG_OFFSET_029:0, OBJ_TIMESTAMP_OFFSET_029:127, OBJ_TRACK_MOTION_MODEL_029:0, OBJ_VEH_TRACK_FLAG_029:0, OBJ_VELOCITY_ERR_CRR_COEF_029:120, OBJ_VELOCITY_LAT_029:16300, OBJ_VELOCITY_LAT_ERR_029:0, OBJ_VELOCITY_LONG_029:16300, OBJ_VELOCITY_LONG_ERR_029:0, OBJ_YAW_ANGLE_029:2000, OBJ_YAW_ANGLE_ERR_029:0, OBJ_YAW_RATE_029:448, OBJ_YAW_RATE_ERR_029:0]}, provided-interface=Pi_SG_TrackerObject029
      Pp_SG_TrackerObject057: nonqueued-sender-com-spec{data-element=Vdp_SG_TrackerObject057, init-value=fields=[OBJ_ACCEL_ERR_CRR_COEF_057:120, OBJ_ACCELERATION_LAT_057:400, OBJ_ACCELERATION_LAT_ERR_057:0, OBJ_ACCELERATION_LONG_057:400, OBJ_ACCELERATION_LONG_ERR_057:0, OBJ_ALIVE_TIME_057:0, OBJ_CLS_TYPE1_057:0, OBJ_CLS_TYPE1_PROB_057:0, OBJ_CLS_TYPE2_057:0, OBJ_CLS_TYPE2_PROB_057:0, OBJ_CLS_TYPE3_057:0, OBJ_CLS_TYPE3_PROB_057:0, OBJ_CLS_TYPE4_057:0, OBJ_CLS_TYPE4_PROB_057:0, OBJ_CLS_TYPE5_057:0, OBJ_CLS_TYPE5_PROB_057:0, OBJ_CLS_TYPE6_057:0, OBJ_CLS_TYPE6_PROB_057:0, OBJ_DIMENSION_LENGTH_057:0, OBJ_DIMENSION_LENGTH_ERR_057:0, OBJ_DIMENSION_WIDTH_057:0, OBJ_DIMENSION_WIDTH_ERR_057:0, OBJ_EXISTENCE_PROB_057:0, OBJ_GROUP_ID_057:0, OBJ_ID_057:0, OBJ_MEASUREMENT_STATUS_057:0, OBJ_MH_CRC16_057:0, OBJ_MH_CYCLE_COUNTER_057:0, OBJ_MOVEMENT_STATUS_057:0, OBJ_POS_ERR_CRR_COEF_057:120, OBJ_POS_LAT_057:32700, OBJ_POS_LAT_ERR_057:0, OBJ_POS_LONG_057:32700, OBJ_POS_LONG_ERR_057:0, OBJ_RCS_057:64, OBJ_REF_PT_LAT_OFFSET_057:0, OBJ_REF_PT_LONG_OFFSET_057:0, OBJ_TIMESTAMP_OFFSET_057:127, OBJ_TRACK_MOTION_MODEL_057:0, OBJ_VEH_TRACK_FLAG_057:0, OBJ_VELOCITY_ERR_CRR_COEF_057:120, OBJ_VELOCITY_LAT_057:16300, OBJ_VELOCITY_LAT_ERR_057:0, OBJ_VELOCITY_LONG_057:16300, OBJ_VELOCITY_LONG_ERR_057:0, OBJ_YAW_ANGLE_057:2000, OBJ_YAW_ANGLE_ERR_057:0, OBJ_YAW_RATE_057:448, OBJ_YAW_RATE_ERR_057:0]}, provided-interface=Pi_SG_TrackerObject057
      Pp_SG_TrackerObject033: nonqueued-sender-com-spec{data-element=Vdp_SG_TrackerObject033, init-value=fields=[OBJ_ACCEL_ERR_CRR_COEF_033:120, OBJ_ACCELERATION_LAT_033:400, OBJ_ACCELERATION_LAT_ERR_033:0, OBJ_ACCELERATION_LONG_033:400, OBJ_ACCELERATION_LONG_ERR_033:0, OBJ_ALIVE_TIME_033:0, OBJ_CLS_TYPE1_033:0, OBJ_CLS_TYPE1_PROB_033:0, OBJ_CLS_TYPE2_033:0, OBJ_CLS_TYPE2_PROB_033:0, OBJ_CLS_TYPE3_033:0, OBJ_CLS_TYPE3_PROB_033:0, OBJ_CLS_TYPE4_033:0, OBJ_CLS_TYPE4_PROB_033:0, OBJ_CLS_TYPE5_033:0, OBJ_CLS_TYPE5_PROB_033:0, OBJ_CLS_TYPE6_033:0, OBJ_CLS_TYPE6_PROB_033:0, OBJ_DIMENSION_LENGTH_033:0, OBJ_DIMENSION_LENGTH_ERR_033:0, OBJ_DIMENSION_WIDTH_033:0, OBJ_DIMENSION_WIDTH_ERR_033:0, OBJ_EXISTENCE_PROB_033:0, OBJ_GROUP_ID_033:0, OBJ_ID_033:0, OBJ_MEASUREMENT_STATUS_033:0, OBJ_MH_CRC16_033:0, OBJ_MH_CYCLE_COUNTER_033:0, OBJ_MOVEMENT_STATUS_033:0, OBJ_POS_ERR_CRR_COEF_033:120, OBJ_POS_LAT_033:32700, OBJ_POS_LAT_ERR_033:0, OBJ_POS_LONG_033:32700, OBJ_POS_LONG_ERR_033:0, OBJ_RCS_033:64, OBJ_REF_PT_LAT_OFFSET_033:0, OBJ_REF_PT_LONG_OFFSET_033:0, OBJ_TIMESTAMP_OFFSET_033:127, OBJ_TRACK_MOTION_MODEL_033:0, OBJ_VEH_TRACK_FLAG_033:0, OBJ_VELOCITY_ERR_CRR_COEF_033:120, OBJ_VELOCITY_LAT_033:16300, OBJ_VELOCITY_LAT_ERR_033:0, OBJ_VELOCITY_LONG_033:16300, OBJ_VELOCITY_LONG_ERR_033:0, OBJ_YAW_ANGLE_033:2000, OBJ_YAW_ANGLE_ERR_033:0, OBJ_YAW_RATE_033:448, OBJ_YAW_RATE_ERR_033:0]}, provided-interface=Pi_SG_TrackerObject033
      Pp_SG_TrackerObject064: nonqueued-sender-com-spec{data-element=Vdp_SG_TrackerObject064, init-value=fields=[OBJ_ACCEL_ERR_CRR_COEF_064:120, OBJ_ACCELERATION_LAT_064:400, OBJ_ACCELERATION_LAT_ERR_064:0, OBJ_ACCELERATION_LONG_064:400, OBJ_ACCELERATION_LONG_ERR_064:0, OBJ_ALIVE_TIME_064:0, OBJ_CLS_TYPE1_064:0, OBJ_CLS_TYPE1_PROB_064:0, OBJ_CLS_TYPE2_064:0, OBJ_CLS_TYPE2_PROB_064:0, OBJ_CLS_TYPE3_064:0, OBJ_CLS_TYPE3_PROB_064:0, OBJ_CLS_TYPE4_064:0, OBJ_CLS_TYPE4_PROB_064:0, OBJ_CLS_TYPE5_064:0, OBJ_CLS_TYPE5_PROB_064:0, OBJ_CLS_TYPE6_064:0, OBJ_CLS_TYPE6_PROB_064:0, OBJ_DIMENSION_LENGTH_064:0, OBJ_DIMENSION_LENGTH_ERR_064:0, OBJ_DIMENSION_WIDTH_064:0, OBJ_DIMENSION_WIDTH_ERR_064:0, OBJ_EXISTENCE_PROB_064:0, OBJ_GROUP_ID_064:0, OBJ_ID_064:0, OBJ_MEASUREMENT_STATUS_064:0, OBJ_MH_CRC16_064:0, OBJ_MH_CYCLE_COUNTER_064:0, OBJ_MOVEMENT_STATUS_064:0, OBJ_POS_ERR_CRR_COEF_064:120, OBJ_POS_LAT_064:32700, OBJ_POS_LAT_ERR_064:0, OBJ_POS_LONG_064:32700, OBJ_POS_LONG_ERR_064:0, OBJ_RCS_064:64, OBJ_REF_PT_LAT_OFFSET_064:0, OBJ_REF_PT_LONG_OFFSET_064:0, OBJ_TIMESTAMP_OFFSET_064:127, OBJ_TRACK_MOTION_MODEL_064:0, OBJ_VEH_TRACK_FLAG_064:0, OBJ_VELOCITY_ERR_CRR_COEF_064:120, OBJ_VELOCITY_LAT_064:16300, OBJ_VELOCITY_LAT_ERR_064:0, OBJ_VELOCITY_LONG_064:16300, OBJ_VELOCITY_LONG_ERR_064:0, OBJ_YAW_ANGLE_064:2000, OBJ_YAW_ANGLE_ERR_064:0, OBJ_YAW_RATE_064:448, OBJ_YAW_RATE_ERR_064:0]}, provided-interface=Pi_SG_TrackerObject064
      Pp_SG_TrackerObject063: nonqueued-sender-com-spec{data-element=Vdp_SG_TrackerObject063, init-value=fields=[OBJ_ACCEL_ERR_CRR_COEF_063:120, OBJ_ACCELERATION_LAT_063:400, OBJ_ACCELERATION_LAT_ERR_063:0, OBJ_ACCELERATION_LONG_063:400, OBJ_ACCELERATION_LONG_ERR_063:0, OBJ_ALIVE_TIME_063:0, OBJ_CLS_TYPE1_063:0, OBJ_CLS_TYPE1_PROB_063:0, OBJ_CLS_TYPE2_063:0, OBJ_CLS_TYPE2_PROB_063:0, OBJ_CLS_TYPE3_063:0, OBJ_CLS_TYPE3_PROB_063:0, OBJ_CLS_TYPE4_063:0, OBJ_CLS_TYPE4_PROB_063:0, OBJ_CLS_TYPE5_063:0, OBJ_CLS_TYPE5_PROB_063:0, OBJ_CLS_TYPE6_063:0, OBJ_CLS_TYPE6_PROB_063:0, OBJ_DIMENSION_LENGTH_063:0, OBJ_DIMENSION_LENGTH_ERR_063:0, OBJ_DIMENSION_WIDTH_063:0, OBJ_DIMENSION_WIDTH_ERR_063:0, OBJ_EXISTENCE_PROB_063:0, OBJ_GROUP_ID_063:0, OBJ_ID_063:0, OBJ_MEASUREMENT_STATUS_063:0, OBJ_MH_CRC16_063:0, OBJ_MH_CYCLE_COUNTER_063:0, OBJ_MOVEMENT_STATUS_063:0, OBJ_POS_ERR_CRR_COEF_063:120, OBJ_POS_LAT_063:32700, OBJ_POS_LAT_ERR_063:0, OBJ_POS_LONG_063:32700, OBJ_POS_LONG_ERR_063:0, OBJ_RCS_063:64, OBJ_REF_PT_LAT_OFFSET_063:0, OBJ_REF_PT_LONG_OFFSET_063:0, OBJ_TIMESTAMP_OFFSET_063:127, OBJ_TRACK_MOTION_MODEL_063:0, OBJ_VEH_TRACK_FLAG_063:0, OBJ_VELOCITY_ERR_CRR_COEF_063:120, OBJ_VELOCITY_LAT_063:16300, OBJ_VELOCITY_LAT_ERR_063:0, OBJ_VELOCITY_LONG_063:16300, OBJ_VELOCITY_LONG_ERR_063:0, OBJ_YAW_ANGLE_063:2000, OBJ_YAW_ANGLE_ERR_063:0, OBJ_YAW_RATE_063:448, OBJ_YAW_RATE_ERR_063:0]}, provided-interface=Pi_SG_TrackerObject063
      Pp_SG_TrackerObject046: nonqueued-sender-com-spec{data-element=Vdp_SG_TrackerObject046, init-value=fields=[OBJ_ACCEL_ERR_CRR_COEF_046:120, OBJ_ACCELERATION_LAT_046:400, OBJ_ACCELERATION_LAT_ERR_046:0, OBJ_ACCELERATION_LONG_046:400, OBJ_ACCELERATION_LONG_ERR_046:0, OBJ_ALIVE_TIME_046:0, OBJ_CLS_TYPE1_046:0, OBJ_CLS_TYPE1_PROB_046:0, OBJ_CLS_TYPE2_046:0, OBJ_CLS_TYPE2_PROB_046:0, OBJ_CLS_TYPE3_046:0, OBJ_CLS_TYPE3_PROB_046:0, OBJ_CLS_TYPE4_046:0, OBJ_CLS_TYPE4_PROB_046:0, OBJ_CLS_TYPE5_046:0, OBJ_CLS_TYPE5_PROB_046:0, OBJ_CLS_TYPE6_046:0, OBJ_CLS_TYPE6_PROB_046:0, OBJ_DIMENSION_LENGTH_046:0, OBJ_DIMENSION_LENGTH_ERR_046:0, OBJ_DIMENSION_WIDTH_046:0, OBJ_DIMENSION_WIDTH_ERR_046:0, OBJ_EXISTENCE_PROB_046:0, OBJ_GROUP_ID_046:0, OBJ_ID_046:0, OBJ_MEASUREMENT_STATUS_046:0, OBJ_MH_CRC16_046:0, OBJ_MH_CYCLE_COUNTER_046:0, OBJ_MOVEMENT_STATUS_046:0, OBJ_POS_ERR_CRR_COEF_046:120, OBJ_POS_LAT_046:32700, OBJ_POS_LAT_ERR_046:0, OBJ_POS_LONG_046:32700, OBJ_POS_LONG_ERR_046:0, OBJ_RCS_046:64, OBJ_REF_PT_LAT_OFFSET_046:0, OBJ_REF_PT_LONG_OFFSET_046:0, OBJ_TIMESTAMP_OFFSET_046:127, OBJ_TRACK_MOTION_MODEL_046:0, OBJ_VEH_TRACK_FLAG_046:0, OBJ_VELOCITY_ERR_CRR_COEF_046:120, OBJ_VELOCITY_LAT_046:16300, OBJ_VELOCITY_LAT_ERR_046:0, OBJ_VELOCITY_LONG_046:16300, OBJ_VELOCITY_LONG_ERR_046:0, OBJ_YAW_ANGLE_046:2000, OBJ_YAW_ANGLE_ERR_046:0, OBJ_YAW_RATE_046:448, OBJ_YAW_RATE_ERR_046:0]}, provided-interface=Pi_SG_TrackerObject046
      Pp_SG_TrackerObject005: nonqueued-sender-com-spec{data-element=Vdp_SG_TrackerObject005, init-value=fields=[OBJ_ACCEL_ERR_CRR_COEF_005:120, OBJ_ACCELERATION_LAT_005:400, OBJ_ACCELERATION_LAT_ERR_005:0, OBJ_ACCELERATION_LONG_005:400, OBJ_ACCELERATION_LONG_ERR_005:0, OBJ_ALIVE_TIME_005:0, OBJ_CLS_TYPE1_005:0, OBJ_CLS_TYPE1_PROB_005:0, OBJ_CLS_TYPE2_005:0, OBJ_CLS_TYPE2_PROB_005:0, OBJ_CLS_TYPE3_005:0, OBJ_CLS_TYPE3_PROB_005:0, OBJ_CLS_TYPE4_005:0, OBJ_CLS_TYPE4_PROB_005:0, OBJ_CLS_TYPE5_005:0, OBJ_CLS_TYPE5_PROB_005:0, OBJ_CLS_TYPE6_005:0, OBJ_CLS_TYPE6_PROB_005:0, OBJ_DIMENSION_LENGTH_005:0, OBJ_DIMENSION_LENGTH_ERR_005:0, OBJ_DIMENSION_WIDTH_005:0, OBJ_DIMENSION_WIDTH_ERR_005:0, OBJ_EXISTENCE_PROB_005:0, OBJ_GROUP_ID_005:0, OBJ_ID_005:0, OBJ_MEASUREMENT_STATUS_005:0, OBJ_MH_CRC16_005:0, OBJ_MH_CYCLE_COUNTER_005:0, OBJ_MOVEMENT_STATUS_005:0, OBJ_POS_ERR_CRR_COEF_005:120, OBJ_POS_LAT_005:32700, OBJ_POS_LAT_ERR_005:0, OBJ_POS_LONG_005:32700, OBJ_POS_LONG_ERR_005:0, OBJ_RCS_005:64, OBJ_REF_PT_LAT_OFFSET_005:0, OBJ_REF_PT_LONG_OFFSET_005:0, OBJ_TIMESTAMP_OFFSET_005:127, OBJ_TRACK_MOTION_MODEL_005:0, OBJ_VEH_TRACK_FLAG_005:0, OBJ_VELOCITY_ERR_CRR_COEF_005:120, OBJ_VELOCITY_LAT_005:16300, OBJ_VELOCITY_LAT_ERR_005:0, OBJ_VELOCITY_LONG_005:16300, OBJ_VELOCITY_LONG_ERR_005:0, OBJ_YAW_ANGLE_005:2000, OBJ_YAW_ANGLE_ERR_005:0, OBJ_YAW_RATE_005:448, OBJ_YAW_RATE_ERR_005:0]}, provided-interface=Pi_SG_TrackerObject005
      Pp_RDR_NM_PNC_Reserved3: nonqueued-sender-com-spec{data-element=Vdp_RDR_NM_PNC_Reserved3, init-value=0}, provided-interface=Pi_RDR_NM_PNC_Reserved3_1
      Pp_SG_TrackerObject040: nonqueued-sender-com-spec{data-element=Vdp_SG_TrackerObject040, init-value=fields=[OBJ_ACCEL_ERR_CRR_COEF_040:120, OBJ_ACCELERATION_LAT_040:400, OBJ_ACCELERATION_LAT_ERR_040:0, OBJ_ACCELERATION_LONG_040:400, OBJ_ACCELERATION_LONG_ERR_040:0, OBJ_ALIVE_TIME_040:0, OBJ_CLS_TYPE1_040:0, OBJ_CLS_TYPE1_PROB_040:0, OBJ_CLS_TYPE2_040:0, OBJ_CLS_TYPE2_PROB_040:0, OBJ_CLS_TYPE3_040:0, OBJ_CLS_TYPE3_PROB_040:0, OBJ_CLS_TYPE4_040:0, OBJ_CLS_TYPE4_PROB_040:0, OBJ_CLS_TYPE5_040:0, OBJ_CLS_TYPE5_PROB_040:0, OBJ_CLS_TYPE6_040:0, OBJ_CLS_TYPE6_PROB_040:0, OBJ_DIMENSION_LENGTH_040:0, OBJ_DIMENSION_LENGTH_ERR_040:0, OBJ_DIMENSION_WIDTH_040:0, OBJ_DIMENSION_WIDTH_ERR_040:0, OBJ_EXISTENCE_PROB_040:0, OBJ_GROUP_ID_040:0, OBJ_ID_040:0, OBJ_MEASUREMENT_STATUS_040:0, OBJ_MH_CRC16_040:0, OBJ_MH_CYCLE_COUNTER_040:0, OBJ_MOVEMENT_STATUS_040:0, OBJ_POS_ERR_CRR_COEF_040:120, OBJ_POS_LAT_040:32700, OBJ_POS_LAT_ERR_040:0, OBJ_POS_LONG_040:32700, OBJ_POS_LONG_ERR_040:0, OBJ_RCS_040:64, OBJ_REF_PT_LAT_OFFSET_040:0, OBJ_REF_PT_LONG_OFFSET_040:0, OBJ_TIMESTAMP_OFFSET_040:127, OBJ_TRACK_MOTION_MODEL_040:0, OBJ_VEH_TRACK_FLAG_040:0, OBJ_VELOCITY_ERR_CRR_COEF_040:120, OBJ_VELOCITY_LAT_040:16300, OBJ_VELOCITY_LAT_ERR_040:0, OBJ_VELOCITY_LONG_040:16300, OBJ_VELOCITY_LONG_ERR_040:0, OBJ_YAW_ANGLE_040:2000, OBJ_YAW_ANGLE_ERR_040:0, OBJ_YAW_RATE_040:448, OBJ_YAW_RATE_ERR_040:0]}, provided-interface=Pi_SG_TrackerObject040
      Pp_RDR_NM_CBV_NMCoordBit_3: nonqueued-sender-com-spec{data-element=Vdp_RDR_NM_CBV_NMCoordBit_3, init-value=0}, provided-interface=Pi_RDR_NM_CBV_NMCoordBit_4
      Pp_SG_TrackerObject059: nonqueued-sender-com-spec{data-element=Vdp_SG_TrackerObject059, init-value=fields=[OBJ_ACCEL_ERR_CRR_COEF_059:120, OBJ_ACCELERATION_LAT_059:400, OBJ_ACCELERATION_LAT_ERR_059:0, OBJ_ACCELERATION_LONG_059:400, OBJ_ACCELERATION_LONG_ERR_059:0, OBJ_ALIVE_TIME_059:0, OBJ_CLS_TYPE1_059:0, OBJ_CLS_TYPE1_PROB_059:0, OBJ_CLS_TYPE2_059:0, OBJ_CLS_TYPE2_PROB_059:0, OBJ_CLS_TYPE3_059:0, OBJ_CLS_TYPE3_PROB_059:0, OBJ_CLS_TYPE4_059:0, OBJ_CLS_TYPE4_PROB_059:0, OBJ_CLS_TYPE5_059:0, OBJ_CLS_TYPE5_PROB_059:0, OBJ_CLS_TYPE6_059:0, OBJ_CLS_TYPE6_PROB_059:0, OBJ_DIMENSION_LENGTH_059:0, OBJ_DIMENSION_LENGTH_ERR_059:0, OBJ_DIMENSION_WIDTH_059:0, OBJ_DIMENSION_WIDTH_ERR_059:0, OBJ_EXISTENCE_PROB_059:0, OBJ_GROUP_ID_059:0, OBJ_ID_059:0, OBJ_MEASUREMENT_STATUS_059:0, OBJ_MH_CRC16_059:0, OBJ_MH_CYCLE_COUNTER_059:0, OBJ_MOVEMENT_STATUS_059:0, OBJ_POS_ERR_CRR_COEF_059:120, OBJ_POS_LAT_059:32700, OBJ_POS_LAT_ERR_059:0, OBJ_POS_LONG_059:32700, OBJ_POS_LONG_ERR_059:0, OBJ_RCS_059:64, OBJ_REF_PT_LAT_OFFSET_059:0, OBJ_REF_PT_LONG_OFFSET_059:0, OBJ_TIMESTAMP_OFFSET_059:127, OBJ_TRACK_MOTION_MODEL_059:0, OBJ_VEH_TRACK_FLAG_059:0, OBJ_VELOCITY_ERR_CRR_COEF_059:120, OBJ_VELOCITY_LAT_059:16300, OBJ_VELOCITY_LAT_ERR_059:0, OBJ_VELOCITY_LONG_059:16300, OBJ_VELOCITY_LONG_ERR_059:0, OBJ_YAW_ANGLE_059:2000, OBJ_YAW_ANGLE_ERR_059:0, OBJ_YAW_RATE_059:448, OBJ_YAW_RATE_ERR_059:0]}, provided-interface=Pi_SG_TrackerObject059
      Pp_SG_TrackerObject030: nonqueued-sender-com-spec{data-element=Vdp_SG_TrackerObject030, init-value=fields=[OBJ_ACCEL_ERR_CRR_COEF_030:120, OBJ_ACCELERATION_LAT_030:400, OBJ_ACCELERATION_LAT_ERR_030:0, OBJ_ACCELERATION_LONG_030:400, OBJ_ACCELERATION_LONG_ERR_030:0, OBJ_ALIVE_TIME_030:0, OBJ_CLS_TYPE1_030:0, OBJ_CLS_TYPE1_PROB_030:0, OBJ_CLS_TYPE2_030:0, OBJ_CLS_TYPE2_PROB_030:0, OBJ_CLS_TYPE3_030:0, OBJ_CLS_TYPE3_PROB_030:0, OBJ_CLS_TYPE4_030:0, OBJ_CLS_TYPE4_PROB_030:0, OBJ_CLS_TYPE5_030:0, OBJ_CLS_TYPE5_PROB_030:0, OBJ_CLS_TYPE6_030:0, OBJ_CLS_TYPE6_PROB_030:0, OBJ_DIMENSION_LENGTH_030:0, OBJ_DIMENSION_LENGTH_ERR_030:0, OBJ_DIMENSION_WIDTH_030:0, OBJ_DIMENSION_WIDTH_ERR_030:0, OBJ_EXISTENCE_PROB_030:0, OBJ_GROUP_ID_030:0, OBJ_ID_030:0, OBJ_MEASUREMENT_STATUS_030:0, OBJ_MH_CRC16_030:0, OBJ_MH_CYCLE_COUNTER_030:0, OBJ_MOVEMENT_STATUS_030:0, OBJ_POS_ERR_CRR_COEF_030:120, OBJ_POS_LAT_030:32700, OBJ_POS_LAT_ERR_030:0, OBJ_POS_LONG_030:32700, OBJ_POS_LONG_ERR_030:0, OBJ_RCS_030:64, OBJ_REF_PT_LAT_OFFSET_030:0, OBJ_REF_PT_LONG_OFFSET_030:0, OBJ_TIMESTAMP_OFFSET_030:127, OBJ_TRACK_MOTION_MODEL_030:0, OBJ_VEH_TRACK_FLAG_030:0, OBJ_VELOCITY_ERR_CRR_COEF_030:120, OBJ_VELOCITY_LAT_030:16300, OBJ_VELOCITY_LAT_ERR_030:0, OBJ_VELOCITY_LONG_030:16300, OBJ_VELOCITY_LONG_ERR_030:0, OBJ_YAW_ANGLE_030:2000, OBJ_YAW_ANGLE_ERR_030:0, OBJ_YAW_RATE_030:448, OBJ_YAW_RATE_ERR_030:0]}, provided-interface=Pi_SG_TrackerObject030
      Pp_SG_TrackerObject042: nonqueued-sender-com-spec{data-element=Vdp_SG_TrackerObject042, init-value=fields=[OBJ_ACCEL_ERR_CRR_COEF_042:120, OBJ_ACCELERATION_LAT_042:400, OBJ_ACCELERATION_LAT_ERR_042:0, OBJ_ACCELERATION_LONG_042:400, OBJ_ACCELERATION_LONG_ERR_042:0, OBJ_ALIVE_TIME_042:0, OBJ_CLS_TYPE1_042:0, OBJ_CLS_TYPE1_PROB_042:0, OBJ_CLS_TYPE2_042:0, OBJ_CLS_TYPE2_PROB_042:0, OBJ_CLS_TYPE3_042:0, OBJ_CLS_TYPE3_PROB_042:0, OBJ_CLS_TYPE4_042:0, OBJ_CLS_TYPE4_PROB_042:0, OBJ_CLS_TYPE5_042:0, OBJ_CLS_TYPE5_PROB_042:0, OBJ_CLS_TYPE6_042:0, OBJ_CLS_TYPE6_PROB_042:0, OBJ_DIMENSION_LENGTH_042:0, OBJ_DIMENSION_LENGTH_ERR_042:0, OBJ_DIMENSION_WIDTH_042:0, OBJ_DIMENSION_WIDTH_ERR_042:0, OBJ_EXISTENCE_PROB_042:0, OBJ_GROUP_ID_042:0, OBJ_ID_042:0, OBJ_MEASUREMENT_STATUS_042:0, OBJ_MH_CRC16_042:0, OBJ_MH_CYCLE_COUNTER_042:0, OBJ_MOVEMENT_STATUS_042:0, OBJ_POS_ERR_CRR_COEF_042:120, OBJ_POS_LAT_042:32700, OBJ_POS_LAT_ERR_042:0, OBJ_POS_LONG_042:32700, OBJ_POS_LONG_ERR_042:0, OBJ_RCS_042:64, OBJ_REF_PT_LAT_OFFSET_042:0, OBJ_REF_PT_LONG_OFFSET_042:0, OBJ_TIMESTAMP_OFFSET_042:127, OBJ_TRACK_MOTION_MODEL_042:0, OBJ_VEH_TRACK_FLAG_042:0, OBJ_VELOCITY_ERR_CRR_COEF_042:120, OBJ_VELOCITY_LAT_042:16300, OBJ_VELOCITY_LAT_ERR_042:0, OBJ_VELOCITY_LONG_042:16300, OBJ_VELOCITY_LONG_ERR_042:0, OBJ_YAW_ANGLE_042:2000, OBJ_YAW_ANGLE_ERR_042:0, OBJ_YAW_RATE_042:448, OBJ_YAW_RATE_ERR_042:0]}, provided-interface=Pi_SG_TrackerObject042
      Pp_SG_TrackerObject061: nonqueued-sender-com-spec{data-element=Vdp_SG_TrackerObject061, init-value=fields=[OBJ_ACCEL_ERR_CRR_COEF_061:120, OBJ_ACCELERATION_LAT_061:400, OBJ_ACCELERATION_LAT_ERR_061:0, OBJ_ACCELERATION_LONG_061:400, OBJ_ACCELERATION_LONG_ERR_061:0, OBJ_ALIVE_TIME_061:0, OBJ_CLS_TYPE1_061:0, OBJ_CLS_TYPE1_PROB_061:0, OBJ_CLS_TYPE2_061:0, OBJ_CLS_TYPE2_PROB_061:0, OBJ_CLS_TYPE3_061:0, OBJ_CLS_TYPE3_PROB_061:0, OBJ_CLS_TYPE4_061:0, OBJ_CLS_TYPE4_PROB_061:0, OBJ_CLS_TYPE5_061:0, OBJ_CLS_TYPE5_PROB_061:0, OBJ_CLS_TYPE6_061:0, OBJ_CLS_TYPE6_PROB_061:0, OBJ_DIMENSION_LENGTH_061:0, OBJ_DIMENSION_LENGTH_ERR_061:0, OBJ_DIMENSION_WIDTH_061:0, OBJ_DIMENSION_WIDTH_ERR_061:0, OBJ_EXISTENCE_PROB_061:0, OBJ_GROUP_ID_061:0, OBJ_ID_061:0, OBJ_MEASUREMENT_STATUS_061:0, OBJ_MH_CRC16_061:0, OBJ_MH_CYCLE_COUNTER_061:0, OBJ_MOVEMENT_STATUS_061:0, OBJ_POS_ERR_CRR_COEF_061:120, OBJ_POS_LAT_061:32700, OBJ_POS_LAT_ERR_061:0, OBJ_POS_LONG_061:32700, OBJ_POS_LONG_ERR_061:0, OBJ_RCS_061:64, OBJ_REF_PT_LAT_OFFSET_061:0, OBJ_REF_PT_LONG_OFFSET_061:0, OBJ_TIMESTAMP_OFFSET_061:127, OBJ_TRACK_MOTION_MODEL_061:0, OBJ_VEH_TRACK_FLAG_061:0, OBJ_VELOCITY_ERR_CRR_COEF_061:120, OBJ_VELOCITY_LAT_061:16300, OBJ_VELOCITY_LAT_ERR_061:0, OBJ_VELOCITY_LONG_061:16300, OBJ_VELOCITY_LONG_ERR_061:0, OBJ_YAW_ANGLE_061:2000, OBJ_YAW_ANGLE_ERR_061:0, OBJ_YAW_RATE_061:448, OBJ_YAW_RATE_ERR_061:0]}, provided-interface=Pi_SG_TrackerObject061
      Pp_RDR_NM_PN_User_Data: nonqueued-sender-com-spec{data-element=Vdp_RDR_NM_PN_User_Data, init-value=0}, provided-interface=Pi_RDR_NM_PN_User_Data_1
      Pp_SG_TrackerObject021: nonqueued-sender-com-spec{data-element=Vdp_SG_TrackerObject021, init-value=fields=[OBJ_ACCEL_ERR_CRR_COEF_021:120, OBJ_ACCELERATION_LAT_021:400, OBJ_ACCELERATION_LAT_ERR_021:0, OBJ_ACCELERATION_LONG_021:400, OBJ_ACCELERATION_LONG_ERR_021:0, OBJ_ALIVE_TIME_021:0, OBJ_CLS_TYPE1_021:0, OBJ_CLS_TYPE1_PROB_021:0, OBJ_CLS_TYPE2_021:0, OBJ_CLS_TYPE2_PROB_021:0, OBJ_CLS_TYPE3_021:0, OBJ_CLS_TYPE3_PROB_021:0, OBJ_CLS_TYPE4_021:0, OBJ_CLS_TYPE4_PROB_021:0, OBJ_CLS_TYPE5_021:0, OBJ_CLS_TYPE5_PROB_021:0, OBJ_CLS_TYPE6_021:0, OBJ_CLS_TYPE6_PROB_021:0, OBJ_DIMENSION_LENGTH_021:0, OBJ_DIMENSION_LENGTH_ERR_021:0, OBJ_DIMENSION_WIDTH_021:0, OBJ_DIMENSION_WIDTH_ERR_021:0, OBJ_EXISTENCE_PROB_021:0, OBJ_GROUP_ID_021:0, OBJ_ID_021:0, OBJ_MEASUREMENT_STATUS_021:0, OBJ_MH_CRC16_021:0, OBJ_MH_CYCLE_COUNTER_021:0, OBJ_MOVEMENT_STATUS_021:0, OBJ_POS_ERR_CRR_COEF_021:120, OBJ_POS_LAT_021:32700, OBJ_POS_LAT_ERR_021:0, OBJ_POS_LONG_021:32700, OBJ_POS_LONG_ERR_021:0, OBJ_RCS_021:64, OBJ_REF_PT_LAT_OFFSET_021:0, OBJ_REF_PT_LONG_OFFSET_021:0, OBJ_TIMESTAMP_OFFSET_021:127, OBJ_TRACK_MOTION_MODEL_021:0, OBJ_VEH_TRACK_FLAG_021:0, OBJ_VELOCITY_ERR_CRR_COEF_021:120, OBJ_VELOCITY_LAT_021:16300, OBJ_VELOCITY_LAT_ERR_021:0, OBJ_VELOCITY_LONG_021:16300, OBJ_VELOCITY_LONG_ERR_021:0, OBJ_YAW_ANGLE_021:2000, OBJ_YAW_ANGLE_ERR_021:0, OBJ_YAW_RATE_021:448, OBJ_YAW_RATE_ERR_021:0]}, provided-interface=Pi_SG_TrackerObject021
      Pp_SG_TrackerObject036: nonqueued-sender-com-spec{data-element=Vdp_SG_TrackerObject036, init-value=fields=[OBJ_ACCEL_ERR_CRR_COEF_036:120, OBJ_ACCELERATION_LAT_036:400, OBJ_ACCELERATION_LAT_ERR_036:0, OBJ_ACCELERATION_LONG_036:400, OBJ_ACCELERATION_LONG_ERR_036:0, OBJ_ALIVE_TIME_036:0, OBJ_CLS_TYPE1_036:0, OBJ_CLS_TYPE1_PROB_036:0, OBJ_CLS_TYPE2_036:0, OBJ_CLS_TYPE2_PROB_036:0, OBJ_CLS_TYPE3_036:0, OBJ_CLS_TYPE3_PROB_036:0, OBJ_CLS_TYPE4_036:0, OBJ_CLS_TYPE4_PROB_036:0, OBJ_CLS_TYPE5_036:0, OBJ_CLS_TYPE5_PROB_036:0, OBJ_CLS_TYPE6_036:0, OBJ_CLS_TYPE6_PROB_036:0, OBJ_DIMENSION_LENGTH_036:0, OBJ_DIMENSION_LENGTH_ERR_036:0, OBJ_DIMENSION_WIDTH_036:0, OBJ_DIMENSION_WIDTH_ERR_036:0, OBJ_EXISTENCE_PROB_036:0, OBJ_GROUP_ID_036:0, OBJ_ID_036:0, OBJ_MEASUREMENT_STATUS_036:0, OBJ_MH_CRC16_036:0, OBJ_MH_CYCLE_COUNTER_036:0, OBJ_MOVEMENT_STATUS_036:0, OBJ_POS_ERR_CRR_COEF_036:120, OBJ_POS_LAT_036:32700, OBJ_POS_LAT_ERR_036:0, OBJ_POS_LONG_036:32700, OBJ_POS_LONG_ERR_036:0, OBJ_RCS_036:64, OBJ_REF_PT_LAT_OFFSET_036:0, OBJ_REF_PT_LONG_OFFSET_036:0, OBJ_TIMESTAMP_OFFSET_036:127, OBJ_TRACK_MOTION_MODEL_036:0, OBJ_VEH_TRACK_FLAG_036:0, OBJ_VELOCITY_ERR_CRR_COEF_036:120, OBJ_VELOCITY_LAT_036:16300, OBJ_VELOCITY_LAT_ERR_036:0, OBJ_VELOCITY_LONG_036:16300, OBJ_VELOCITY_LONG_ERR_036:0, OBJ_YAW_ANGLE_036:2000, OBJ_YAW_ANGLE_ERR_036:0, OBJ_YAW_RATE_036:448, OBJ_YAW_RATE_ERR_036:0]}, provided-interface=Pi_SG_TrackerObject036
      Pp_SG_TrackerObject001: nonqueued-sender-com-spec{data-element=Vdp_SG_TrackerObject001, init-value=fields=[OBJ_ACCEL_ERR_CRR_COEF_001:120, OBJ_ACCELERATION_LAT_001:400, OBJ_ACCELERATION_LAT_ERR_001:0, OBJ_ACCELERATION_LONG_001:400, OBJ_ACCELERATION_LONG_ERR_001:0, OBJ_ALIVE_TIME_001:0, OBJ_CLS_TYPE1_001:0, OBJ_CLS_TYPE1_PROB_001:0, OBJ_CLS_TYPE2_001:0, OBJ_CLS_TYPE2_PROB_001:0, OBJ_CLS_TYPE3_001:0, OBJ_CLS_TYPE3_PROB_001:0, OBJ_CLS_TYPE4_001:0, OBJ_CLS_TYPE4_PROB_001:0, OBJ_CLS_TYPE5_001:0, OBJ_CLS_TYPE5_PROB_001:0, OBJ_CLS_TYPE6_001:0, OBJ_CLS_TYPE6_PROB_001:0, OBJ_DIMENSION_LENGTH_001:0, OBJ_DIMENSION_LENGTH_ERR_001:0, OBJ_DIMENSION_WIDTH_001:0, OBJ_DIMENSION_WIDTH_ERR_001:0, OBJ_EXISTENCE_PROB_001:0, OBJ_GROUP_ID_001:0, OBJ_ID_001:0, OBJ_MEASUREMENT_STATUS_001:0, OBJ_MH_CRC16_001:0, OBJ_MH_CYCLE_COUNTER_001:0, OBJ_MOVEMENT_STATUS_001:0, OBJ_POS_ERR_CRR_COEF_001:120, OBJ_POS_LAT_001:32700, OBJ_POS_LAT_ERR_001:0, OBJ_POS_LONG_001:32700, OBJ_POS_LONG_ERR_001:0, OBJ_RCS_001:64, OBJ_REF_PT_LAT_OFFSET_001:0, OBJ_REF_PT_LONG_OFFSET_001:0, OBJ_TIMESTAMP_OFFSET_001:127, OBJ_TRACK_MOTION_MODEL_001:0, OBJ_VEH_TRACK_FLAG_001:0, OBJ_VELOCITY_ERR_CRR_COEF_001:120, OBJ_VELOCITY_LAT_001:16300, OBJ_VELOCITY_LAT_ERR_001:0, OBJ_VELOCITY_LONG_001:16300, OBJ_VELOCITY_LONG_ERR_001:0, OBJ_YAW_ANGLE_001:2000, OBJ_YAW_ANGLE_ERR_001:0, OBJ_YAW_RATE_001:448, OBJ_YAW_RATE_ERR_001:0]}, provided-interface=Pi_SG_TrackerObject001
      Pp_SG_TrackerObject022: nonqueued-sender-com-spec{data-element=Vdp_SG_TrackerObject022, init-value=fields=[OBJ_ACCEL_ERR_CRR_COEF_022:120, OBJ_ACCELERATION_LAT_022:400, OBJ_ACCELERATION_LAT_ERR_022:0, OBJ_ACCELERATION_LONG_022:400, OBJ_ACCELERATION_LONG_ERR_022:0, OBJ_ALIVE_TIME_022:0, OBJ_CLS_TYPE1_022:0, OBJ_CLS_TYPE1_PROB_022:0, OBJ_CLS_TYPE2_022:0, OBJ_CLS_TYPE2_PROB_022:0, OBJ_CLS_TYPE3_022:0, OBJ_CLS_TYPE3_PROB_022:0, OBJ_CLS_TYPE4_022:0, OBJ_CLS_TYPE4_PROB_022:0, OBJ_CLS_TYPE5_022:0, OBJ_CLS_TYPE5_PROB_022:0, OBJ_CLS_TYPE6_022:0, OBJ_CLS_TYPE6_PROB_022:0, OBJ_DIMENSION_LENGTH_022:0, OBJ_DIMENSION_LENGTH_ERR_022:0, OBJ_DIMENSION_WIDTH_022:0, OBJ_DIMENSION_WIDTH_ERR_022:0, OBJ_EXISTENCE_PROB_022:0, OBJ_GROUP_ID_022:0, OBJ_ID_022:0, OBJ_MEASUREMENT_STATUS_022:0, OBJ_MH_CRC16_022:0, OBJ_MH_CYCLE_COUNTER_022:0, OBJ_MOVEMENT_STATUS_022:0, OBJ_POS_ERR_CRR_COEF_022:120, OBJ_POS_LAT_022:32700, OBJ_POS_LAT_ERR_022:0, OBJ_POS_LONG_022:32700, OBJ_POS_LONG_ERR_022:0, OBJ_RCS_022:64, OBJ_REF_PT_LAT_OFFSET_022:0, OBJ_REF_PT_LONG_OFFSET_022:0, OBJ_TIMESTAMP_OFFSET_022:127, OBJ_TRACK_MOTION_MODEL_022:0, OBJ_VEH_TRACK_FLAG_022:0, OBJ_VELOCITY_ERR_CRR_COEF_022:120, OBJ_VELOCITY_LAT_022:16300, OBJ_VELOCITY_LAT_ERR_022:0, OBJ_VELOCITY_LONG_022:16300, OBJ_VELOCITY_LONG_ERR_022:0, OBJ_YAW_ANGLE_022:2000, OBJ_YAW_ANGLE_ERR_022:0, OBJ_YAW_RATE_022:448, OBJ_YAW_RATE_ERR_022:0]}, provided-interface=Pi_SG_TrackerObject022
      Pp_SG_TrackerObject041: nonqueued-sender-com-spec{data-element=Vdp_SG_TrackerObject041, init-value=fields=[OBJ_ACCEL_ERR_CRR_COEF_041:120, OBJ_ACCELERATION_LAT_041:400, OBJ_ACCELERATION_LAT_ERR_041:0, OBJ_ACCELERATION_LONG_041:400, OBJ_ACCELERATION_LONG_ERR_041:0, OBJ_ALIVE_TIME_041:0, OBJ_CLS_TYPE1_041:0, OBJ_CLS_TYPE1_PROB_041:0, OBJ_CLS_TYPE2_041:0, OBJ_CLS_TYPE2_PROB_041:0, OBJ_CLS_TYPE3_041:0, OBJ_CLS_TYPE3_PROB_041:0, OBJ_CLS_TYPE4_041:0, OBJ_CLS_TYPE4_PROB_041:0, OBJ_CLS_TYPE5_041:0, OBJ_CLS_TYPE5_PROB_041:0, OBJ_CLS_TYPE6_041:0, OBJ_CLS_TYPE6_PROB_041:0, OBJ_DIMENSION_LENGTH_041:0, OBJ_DIMENSION_LENGTH_ERR_041:0, OBJ_DIMENSION_WIDTH_041:0, OBJ_DIMENSION_WIDTH_ERR_041:0, OBJ_EXISTENCE_PROB_041:0, OBJ_GROUP_ID_041:0, OBJ_ID_041:0, OBJ_MEASUREMENT_STATUS_041:0, OBJ_MH_CRC16_041:0, OBJ_MH_CYCLE_COUNTER_041:0, OBJ_MOVEMENT_STATUS_041:0, OBJ_POS_ERR_CRR_COEF_041:120, OBJ_POS_LAT_041:32700, OBJ_POS_LAT_ERR_041:0, OBJ_POS_LONG_041:32700, OBJ_POS_LONG_ERR_041:0, OBJ_RCS_041:64, OBJ_REF_PT_LAT_OFFSET_041:0, OBJ_REF_PT_LONG_OFFSET_041:0, OBJ_TIMESTAMP_OFFSET_041:127, OBJ_TRACK_MOTION_MODEL_041:0, OBJ_VEH_TRACK_FLAG_041:0, OBJ_VELOCITY_ERR_CRR_COEF_041:120, OBJ_VELOCITY_LAT_041:16300, OBJ_VELOCITY_LAT_ERR_041:0, OBJ_VELOCITY_LONG_041:16300, OBJ_VELOCITY_LONG_ERR_041:0, OBJ_YAW_ANGLE_041:2000, OBJ_YAW_ANGLE_ERR_041:0, OBJ_YAW_RATE_041:448, OBJ_YAW_RATE_ERR_041:0]}, provided-interface=Pi_SG_TrackerObject041
      Pp_RDR_NM_CBV_ResdBit_2: nonqueued-sender-com-spec{data-element=Vdp_RDR_NM_CBV_ResdBit_2, init-value=0}, provided-interface=Pi_RDR_NM_CBV_ResdBit_4
      Pp_SG_TrackerObject025: nonqueued-sender-com-spec{data-element=Vdp_SG_TrackerObject025, init-value=fields=[OBJ_ACCEL_ERR_CRR_COEF_025:120, OBJ_ACCELERATION_LAT_025:400, OBJ_ACCELERATION_LAT_ERR_025:0, OBJ_ACCELERATION_LONG_025:400, OBJ_ACCELERATION_LONG_ERR_025:0, OBJ_ALIVE_TIME_025:0, OBJ_CLS_TYPE1_025:0, OBJ_CLS_TYPE1_PROB_025:0, OBJ_CLS_TYPE2_025:0, OBJ_CLS_TYPE2_PROB_025:0, OBJ_CLS_TYPE3_025:0, OBJ_CLS_TYPE3_PROB_025:0, OBJ_CLS_TYPE4_025:0, OBJ_CLS_TYPE4_PROB_025:0, OBJ_CLS_TYPE5_025:0, OBJ_CLS_TYPE5_PROB_025:0, OBJ_CLS_TYPE6_025:0, OBJ_CLS_TYPE6_PROB_025:0, OBJ_DIMENSION_LENGTH_025:0, OBJ_DIMENSION_LENGTH_ERR_025:0, OBJ_DIMENSION_WIDTH_025:0, OBJ_DIMENSION_WIDTH_ERR_025:0, OBJ_EXISTENCE_PROB_025:0, OBJ_GROUP_ID_025:0, OBJ_ID_025:0, OBJ_MEASUREMENT_STATUS_025:0, OBJ_MH_CRC16_025:0, OBJ_MH_CYCLE_COUNTER_025:0, OBJ_MOVEMENT_STATUS_025:0, OBJ_POS_ERR_CRR_COEF_025:120, OBJ_POS_LAT_025:32700, OBJ_POS_LAT_ERR_025:0, OBJ_POS_LONG_025:32700, OBJ_POS_LONG_ERR_025:0, OBJ_RCS_025:64, OBJ_REF_PT_LAT_OFFSET_025:0, OBJ_REF_PT_LONG_OFFSET_025:0, OBJ_TIMESTAMP_OFFSET_025:127, OBJ_TRACK_MOTION_MODEL_025:0, OBJ_VEH_TRACK_FLAG_025:0, OBJ_VELOCITY_ERR_CRR_COEF_025:120, OBJ_VELOCITY_LAT_025:16300, OBJ_VELOCITY_LAT_ERR_025:0, OBJ_VELOCITY_LONG_025:16300, OBJ_VELOCITY_LONG_ERR_025:0, OBJ_YAW_ANGLE_025:2000, OBJ_YAW_ANGLE_ERR_025:0, OBJ_YAW_RATE_025:448, OBJ_YAW_RATE_ERR_025:0]}, provided-interface=Pi_SG_TrackerObject025
      Pp_SG_TrackerObject045: nonqueued-sender-com-spec{data-element=Vdp_SG_TrackerObject045, init-value=fields=[OBJ_ACCEL_ERR_CRR_COEF_045:120, OBJ_ACCELERATION_LAT_045:400, OBJ_ACCELERATION_LAT_ERR_045:0, OBJ_ACCELERATION_LONG_045:400, OBJ_ACCELERATION_LONG_ERR_045:0, OBJ_ALIVE_TIME_045:0, OBJ_CLS_TYPE1_045:0, OBJ_CLS_TYPE1_PROB_045:0, OBJ_CLS_TYPE2_045:0, OBJ_CLS_TYPE2_PROB_045:0, OBJ_CLS_TYPE3_045:0, OBJ_CLS_TYPE3_PROB_045:0, OBJ_CLS_TYPE4_045:0, OBJ_CLS_TYPE4_PROB_045:0, OBJ_CLS_TYPE5_045:0, OBJ_CLS_TYPE5_PROB_045:0, OBJ_CLS_TYPE6_045:0, OBJ_CLS_TYPE6_PROB_045:0, OBJ_DIMENSION_LENGTH_045:0, OBJ_DIMENSION_LENGTH_ERR_045:0, OBJ_DIMENSION_WIDTH_045:0, OBJ_DIMENSION_WIDTH_ERR_045:0, OBJ_EXISTENCE_PROB_045:0, OBJ_GROUP_ID_045:0, OBJ_ID_045:0, OBJ_MEASUREMENT_STATUS_045:0, OBJ_MH_CRC16_045:0, OBJ_MH_CYCLE_COUNTER_045:0, OBJ_MOVEMENT_STATUS_045:0, OBJ_POS_ERR_CRR_COEF_045:120, OBJ_POS_LAT_045:32700, OBJ_POS_LAT_ERR_045:0, OBJ_POS_LONG_045:32700, OBJ_POS_LONG_ERR_045:0, OBJ_RCS_045:64, OBJ_REF_PT_LAT_OFFSET_045:0, OBJ_REF_PT_LONG_OFFSET_045:0, OBJ_TIMESTAMP_OFFSET_045:127, OBJ_TRACK_MOTION_MODEL_045:0, OBJ_VEH_TRACK_FLAG_045:0, OBJ_VELOCITY_ERR_CRR_COEF_045:120, OBJ_VELOCITY_LAT_045:16300, OBJ_VELOCITY_LAT_ERR_045:0, OBJ_VELOCITY_LONG_045:16300, OBJ_VELOCITY_LONG_ERR_045:0, OBJ_YAW_ANGLE_045:2000, OBJ_YAW_ANGLE_ERR_045:0, OBJ_YAW_RATE_045:448, OBJ_YAW_RATE_ERR_045:0]}, provided-interface=Pi_SG_TrackerObject045
      Pp_SG_TrackerObject013: nonqueued-sender-com-spec{data-element=Vdp_SG_TrackerObject013, init-value=fields=[OBJ_ACCEL_ERR_CRR_COEF_013:120, OBJ_ACCELERATION_LAT_013:400, OBJ_ACCELERATION_LAT_ERR_013:0, OBJ_ACCELERATION_LONG_013:400, OBJ_ACCELERATION_LONG_ERR_013:0, OBJ_ALIVE_TIME_013:0, OBJ_CLS_TYPE1_013:0, OBJ_CLS_TYPE1_PROB_013:0, OBJ_CLS_TYPE2_013:0, OBJ_CLS_TYPE2_PROB_013:0, OBJ_CLS_TYPE3_013:0, OBJ_CLS_TYPE3_PROB_013:0, OBJ_CLS_TYPE4_013:0, OBJ_CLS_TYPE4_PROB_013:0, OBJ_CLS_TYPE5_013:0, OBJ_CLS_TYPE5_PROB_013:0, OBJ_CLS_TYPE6_013:0, OBJ_CLS_TYPE6_PROB_013:0, OBJ_DIMENSION_LENGTH_013:0, OBJ_DIMENSION_LENGTH_ERR_013:0, OBJ_DIMENSION_WIDTH_013:0, OBJ_DIMENSION_WIDTH_ERR_013:0, OBJ_EXISTENCE_PROB_013:0, OBJ_GROUP_ID_013:0, OBJ_ID_013:0, OBJ_MEASUREMENT_STATUS_013:0, OBJ_MH_CRC16_013:0, OBJ_MH_CYCLE_COUNTER_013:0, OBJ_MOVEMENT_STATUS_013:0, OBJ_POS_ERR_CRR_COEF_013:120, OBJ_POS_LAT_013:32700, OBJ_POS_LAT_ERR_013:0, OBJ_POS_LONG_013:32700, OBJ_POS_LONG_ERR_013:0, OBJ_RCS_013:64, OBJ_REF_PT_LAT_OFFSET_013:0, OBJ_REF_PT_LONG_OFFSET_013:0, OBJ_TIMESTAMP_OFFSET_013:127, OBJ_TRACK_MOTION_MODEL_013:0, OBJ_VEH_TRACK_FLAG_013:0, OBJ_VELOCITY_ERR_CRR_COEF_013:120, OBJ_VELOCITY_LAT_013:16300, OBJ_VELOCITY_LAT_ERR_013:0, OBJ_VELOCITY_LONG_013:16300, OBJ_VELOCITY_LONG_ERR_013:0, OBJ_YAW_ANGLE_013:2000, OBJ_YAW_ANGLE_ERR_013:0, OBJ_YAW_RATE_013:448, OBJ_YAW_RATE_ERR_013:0]}, provided-interface=Pi_SG_TrackerObject013
      Pp_RDR_NM_CBV_PNIBit_6: nonqueued-sender-com-spec{data-element=Vdp_RDR_NM_CBV_PNIBit_6, init-value=0}, provided-interface=Pi_RDR_NM_CBV_PNIBit_7
      Pp_SG_TrackerObject008: nonqueued-sender-com-spec{data-element=Vdp_SG_TrackerObject008, init-value=fields=[OBJ_ACCEL_ERR_CRR_COEF_008:120, OBJ_ACCELERATION_LAT_008:400, OBJ_ACCELERATION_LAT_ERR_008:0, OBJ_ACCELERATION_LONG_008:400, OBJ_ACCELERATION_LONG_ERR_008:0, OBJ_ALIVE_TIME_008:0, OBJ_CLS_TYPE1_008:0, OBJ_CLS_TYPE1_PROB_008:0, OBJ_CLS_TYPE2_008:0, OBJ_CLS_TYPE2_PROB_008:0, OBJ_CLS_TYPE3_008:0, OBJ_CLS_TYPE3_PROB_008:0, OBJ_CLS_TYPE4_008:0, OBJ_CLS_TYPE4_PROB_008:0, OBJ_CLS_TYPE5_008:0, OBJ_CLS_TYPE5_PROB_008:0, OBJ_CLS_TYPE6_008:0, OBJ_CLS_TYPE6_PROB_008:0, OBJ_DIMENSION_LENGTH_008:0, OBJ_DIMENSION_LENGTH_ERR_008:0, OBJ_DIMENSION_WIDTH_008:0, OBJ_DIMENSION_WIDTH_ERR_008:0, OBJ_EXISTENCE_PROB_008:0, OBJ_GROUP_ID_008:0, OBJ_ID_008:0, OBJ_MEASUREMENT_STATUS_008:0, OBJ_MH_CRC16_008:0, OBJ_MH_CYCLE_COUNTER_008:0, OBJ_MOVEMENT_STATUS_008:0, OBJ_POS_ERR_CRR_COEF_008:120, OBJ_POS_LAT_008:32700, OBJ_POS_LAT_ERR_008:0, OBJ_POS_LONG_008:32700, OBJ_POS_LONG_ERR_008:0, OBJ_RCS_008:64, OBJ_REF_PT_LAT_OFFSET_008:0, OBJ_REF_PT_LONG_OFFSET_008:0, OBJ_TIMESTAMP_OFFSET_008:127, OBJ_TRACK_MOTION_MODEL_008:0, OBJ_VEH_TRACK_FLAG_008:0, OBJ_VELOCITY_ERR_CRR_COEF_008:120, OBJ_VELOCITY_LAT_008:16300, OBJ_VELOCITY_LAT_ERR_008:0, OBJ_VELOCITY_LONG_008:16300, OBJ_VELOCITY_LONG_ERR_008:0, OBJ_YAW_ANGLE_008:2000, OBJ_YAW_ANGLE_ERR_008:0, OBJ_YAW_RATE_008:448, OBJ_YAW_RATE_ERR_008:0]}, provided-interface=Pi_SG_TrackerObject008
      Pp_SG_TrackerObject031: nonqueued-sender-com-spec{data-element=Vdp_SG_TrackerObject031, init-value=fields=[OBJ_ACCEL_ERR_CRR_COEF_031:120, OBJ_ACCELERATION_LAT_031:400, OBJ_ACCELERATION_LAT_ERR_031:0, OBJ_ACCELERATION_LONG_031:400, OBJ_ACCELERATION_LONG_ERR_031:0, OBJ_ALIVE_TIME_031:0, OBJ_CLS_TYPE1_031:0, OBJ_CLS_TYPE1_PROB_031:0, OBJ_CLS_TYPE2_031:0, OBJ_CLS_TYPE2_PROB_031:0, OBJ_CLS_TYPE3_031:0, OBJ_CLS_TYPE3_PROB_031:0, OBJ_CLS_TYPE4_031:0, OBJ_CLS_TYPE4_PROB_031:0, OBJ_CLS_TYPE5_031:0, OBJ_CLS_TYPE5_PROB_031:0, OBJ_CLS_TYPE6_031:0, OBJ_CLS_TYPE6_PROB_031:0, OBJ_DIMENSION_LENGTH_031:0, OBJ_DIMENSION_LENGTH_ERR_031:0, OBJ_DIMENSION_WIDTH_031:0, OBJ_DIMENSION_WIDTH_ERR_031:0, OBJ_EXISTENCE_PROB_031:0, OBJ_GROUP_ID_031:0, OBJ_ID_031:0, OBJ_MEASUREMENT_STATUS_031:0, OBJ_MH_CRC16_031:0, OBJ_MH_CYCLE_COUNTER_031:0, OBJ_MOVEMENT_STATUS_031:0, OBJ_POS_ERR_CRR_COEF_031:120, OBJ_POS_LAT_031:32700, OBJ_POS_LAT_ERR_031:0, OBJ_POS_LONG_031:32700, OBJ_POS_LONG_ERR_031:0, OBJ_RCS_031:64, OBJ_REF_PT_LAT_OFFSET_031:0, OBJ_REF_PT_LONG_OFFSET_031:0, OBJ_TIMESTAMP_OFFSET_031:127, OBJ_TRACK_MOTION_MODEL_031:0, OBJ_VEH_TRACK_FLAG_031:0, OBJ_VELOCITY_ERR_CRR_COEF_031:120, OBJ_VELOCITY_LAT_031:16300, OBJ_VELOCITY_LAT_ERR_031:0, OBJ_VELOCITY_LONG_031:16300, OBJ_VELOCITY_LONG_ERR_031:0, OBJ_YAW_ANGLE_031:2000, OBJ_YAW_ANGLE_ERR_031:0, OBJ_YAW_RATE_031:448, OBJ_YAW_RATE_ERR_031:0]}, provided-interface=Pi_SG_TrackerObject031
      Pp_SG_TrackerObject062: nonqueued-sender-com-spec{data-element=Vdp_SG_TrackerObject062, init-value=fields=[OBJ_ACCEL_ERR_CRR_COEF_062:120, OBJ_ACCELERATION_LAT_062:400, OBJ_ACCELERATION_LAT_ERR_062:0, OBJ_ACCELERATION_LONG_062:400, OBJ_ACCELERATION_LONG_ERR_062:0, OBJ_ALIVE_TIME_062:0, OBJ_CLS_TYPE1_062:0, OBJ_CLS_TYPE1_PROB_062:0, OBJ_CLS_TYPE2_062:0, OBJ_CLS_TYPE2_PROB_062:0, OBJ_CLS_TYPE3_062:0, OBJ_CLS_TYPE3_PROB_062:0, OBJ_CLS_TYPE4_062:0, OBJ_CLS_TYPE4_PROB_062:0, OBJ_CLS_TYPE5_062:0, OBJ_CLS_TYPE5_PROB_062:0, OBJ_CLS_TYPE6_062:0, OBJ_CLS_TYPE6_PROB_062:0, OBJ_DIMENSION_LENGTH_062:0, OBJ_DIMENSION_LENGTH_ERR_062:0, OBJ_DIMENSION_WIDTH_062:0, OBJ_DIMENSION_WIDTH_ERR_062:0, OBJ_EXISTENCE_PROB_062:0, OBJ_GROUP_ID_062:0, OBJ_ID_062:0, OBJ_MEASUREMENT_STATUS_062:0, OBJ_MH_CRC16_062:0, OBJ_MH_CYCLE_COUNTER_062:0, OBJ_MOVEMENT_STATUS_062:0, OBJ_POS_ERR_CRR_COEF_062:120, OBJ_POS_LAT_062:32700, OBJ_POS_LAT_ERR_062:0, OBJ_POS_LONG_062:32700, OBJ_POS_LONG_ERR_062:0, OBJ_RCS_062:64, OBJ_REF_PT_LAT_OFFSET_062:0, OBJ_REF_PT_LONG_OFFSET_062:0, OBJ_TIMESTAMP_OFFSET_062:127, OBJ_TRACK_MOTION_MODEL_062:0, OBJ_VEH_TRACK_FLAG_062:0, OBJ_VELOCITY_ERR_CRR_COEF_062:120, OBJ_VELOCITY_LAT_062:16300, OBJ_VELOCITY_LAT_ERR_062:0, OBJ_VELOCITY_LONG_062:16300, OBJ_VELOCITY_LONG_ERR_062:0, OBJ_YAW_ANGLE_062:2000, OBJ_YAW_ANGLE_ERR_062:0, OBJ_YAW_RATE_062:448, OBJ_YAW_RATE_ERR_062:0]}, provided-interface=Pi_SG_TrackerObject062
      Pp_SG_TrackerObject028: nonqueued-sender-com-spec{data-element=Vdp_SG_TrackerObject028, init-value=fields=[OBJ_ACCEL_ERR_CRR_COEF_028:120, OBJ_ACCELERATION_LAT_028:400, OBJ_ACCELERATION_LAT_ERR_028:0, OBJ_ACCELERATION_LONG_028:400, OBJ_ACCELERATION_LONG_ERR_028:0, OBJ_ALIVE_TIME_028:0, OBJ_CLS_TYPE1_028:0, OBJ_CLS_TYPE1_PROB_028:0, OBJ_CLS_TYPE2_028:0, OBJ_CLS_TYPE2_PROB_028:0, OBJ_CLS_TYPE3_028:0, OBJ_CLS_TYPE3_PROB_028:0, OBJ_CLS_TYPE4_028:0, OBJ_CLS_TYPE4_PROB_028:0, OBJ_CLS_TYPE5_028:0, OBJ_CLS_TYPE5_PROB_028:0, OBJ_CLS_TYPE6_028:0, OBJ_CLS_TYPE6_PROB_028:0, OBJ_DIMENSION_LENGTH_028:0, OBJ_DIMENSION_LENGTH_ERR_028:0, OBJ_DIMENSION_WIDTH_028:0, OBJ_DIMENSION_WIDTH_ERR_028:0, OBJ_EXISTENCE_PROB_028:0, OBJ_GROUP_ID_028:0, OBJ_ID_028:0, OBJ_MEASUREMENT_STATUS_028:0, OBJ_MH_CRC16_028:0, OBJ_MH_CYCLE_COUNTER_028:0, OBJ_MOVEMENT_STATUS_028:0, OBJ_POS_ERR_CRR_COEF_028:120, OBJ_POS_LAT_028:32700, OBJ_POS_LAT_ERR_028:0, OBJ_POS_LONG_028:32700, OBJ_POS_LONG_ERR_028:0, OBJ_RCS_028:64, OBJ_REF_PT_LAT_OFFSET_028:0, OBJ_REF_PT_LONG_OFFSET_028:0, OBJ_TIMESTAMP_OFFSET_028:127, OBJ_TRACK_MOTION_MODEL_028:0, OBJ_VEH_TRACK_FLAG_028:0, OBJ_VELOCITY_ERR_CRR_COEF_028:120, OBJ_VELOCITY_LAT_028:16300, OBJ_VELOCITY_LAT_ERR_028:0, OBJ_VELOCITY_LONG_028:16300, OBJ_VELOCITY_LONG_ERR_028:0, OBJ_YAW_ANGLE_028:2000, OBJ_YAW_ANGLE_ERR_028:0, OBJ_YAW_RATE_028:448, OBJ_YAW_RATE_ERR_028:0]}, provided-interface=Pi_SG_TrackerObject028
      Pp_SG_TrackerObject049: nonqueued-sender-com-spec{data-element=Vdp_SG_TrackerObject049, init-value=fields=[OBJ_ACCEL_ERR_CRR_COEF_049:120, OBJ_ACCELERATION_LAT_049:400, OBJ_ACCELERATION_LAT_ERR_049:0, OBJ_ACCELERATION_LONG_049:400, OBJ_ACCELERATION_LONG_ERR_049:0, OBJ_ALIVE_TIME_049:0, OBJ_CLS_TYPE1_049:0, OBJ_CLS_TYPE1_PROB_049:0, OBJ_CLS_TYPE2_049:0, OBJ_CLS_TYPE2_PROB_049:0, OBJ_CLS_TYPE3_049:0, OBJ_CLS_TYPE3_PROB_049:0, OBJ_CLS_TYPE4_049:0, OBJ_CLS_TYPE4_PROB_049:0, OBJ_CLS_TYPE5_049:0, OBJ_CLS_TYPE5_PROB_049:0, OBJ_CLS_TYPE6_049:0, OBJ_CLS_TYPE6_PROB_049:0, OBJ_DIMENSION_LENGTH_049:0, OBJ_DIMENSION_LENGTH_ERR_049:0, OBJ_DIMENSION_WIDTH_049:0, OBJ_DIMENSION_WIDTH_ERR_049:0, OBJ_EXISTENCE_PROB_049:0, OBJ_GROUP_ID_049:0, OBJ_ID_049:0, OBJ_MEASUREMENT_STATUS_049:0, OBJ_MH_CRC16_049:0, OBJ_MH_CYCLE_COUNTER_049:0, OBJ_MOVEMENT_STATUS_049:0, OBJ_POS_ERR_CRR_COEF_049:120, OBJ_POS_LAT_049:32700, OBJ_POS_LAT_ERR_049:0, OBJ_POS_LONG_049:32700, OBJ_POS_LONG_ERR_049:0, OBJ_RCS_049:64, OBJ_REF_PT_LAT_OFFSET_049:0, OBJ_REF_PT_LONG_OFFSET_049:0, OBJ_TIMESTAMP_OFFSET_049:127, OBJ_TRACK_MOTION_MODEL_049:0, OBJ_VEH_TRACK_FLAG_049:0, OBJ_VELOCITY_ERR_CRR_COEF_049:120, OBJ_VELOCITY_LAT_049:16300, OBJ_VELOCITY_LAT_ERR_049:0, OBJ_VELOCITY_LONG_049:16300, OBJ_VELOCITY_LONG_ERR_049:0, OBJ_YAW_ANGLE_049:2000, OBJ_YAW_ANGLE_ERR_049:0, OBJ_YAW_RATE_049:448, OBJ_YAW_RATE_ERR_049:0]}, provided-interface=Pi_SG_TrackerObject049
      Pp_SG_TrackerObject019: nonqueued-sender-com-spec{data-element=Vdp_SG_TrackerObject019, init-value=fields=[OBJ_ACCEL_ERR_CRR_COEF_019:120, OBJ_ACCELERATION_LAT_019:400, OBJ_ACCELERATION_LAT_ERR_019:0, OBJ_ACCELERATION_LONG_019:400, OBJ_ACCELERATION_LONG_ERR_019:0, OBJ_ALIVE_TIME_019:0, OBJ_CLS_TYPE1_019:0, OBJ_CLS_TYPE1_PROB_019:0, OBJ_CLS_TYPE2_019:0, OBJ_CLS_TYPE2_PROB_019:0, OBJ_CLS_TYPE3_019:0, OBJ_CLS_TYPE3_PROB_019:0, OBJ_CLS_TYPE4_019:0, OBJ_CLS_TYPE4_PROB_019:0, OBJ_CLS_TYPE5_019:0, OBJ_CLS_TYPE5_PROB_019:0, OBJ_CLS_TYPE6_019:0, OBJ_CLS_TYPE6_PROB_019:0, OBJ_DIMENSION_LENGTH_019:0, OBJ_DIMENSION_LENGTH_ERR_019:0, OBJ_DIMENSION_WIDTH_019:0, OBJ_DIMENSION_WIDTH_ERR_019:0, OBJ_EXISTENCE_PROB_019:0, OBJ_GROUP_ID_019:0, OBJ_ID_019:0, OBJ_MEASUREMENT_STATUS_019:0, OBJ_MH_CRC16_019:0, OBJ_MH_CYCLE_COUNTER_019:0, OBJ_MOVEMENT_STATUS_019:0, OBJ_POS_ERR_CRR_COEF_019:120, OBJ_POS_LAT_019:32700, OBJ_POS_LAT_ERR_019:0, OBJ_POS_LONG_019:32700, OBJ_POS_LONG_ERR_019:0, OBJ_RCS_019:64, OBJ_REF_PT_LAT_OFFSET_019:0, OBJ_REF_PT_LONG_OFFSET_019:0, OBJ_TIMESTAMP_OFFSET_019:127, OBJ_TRACK_MOTION_MODEL_019:0, OBJ_VEH_TRACK_FLAG_019:0, OBJ_VELOCITY_ERR_CRR_COEF_019:120, OBJ_VELOCITY_LAT_019:16300, OBJ_VELOCITY_LAT_ERR_019:0, OBJ_VELOCITY_LONG_019:16300, OBJ_VELOCITY_LONG_ERR_019:0, OBJ_YAW_ANGLE_019:2000, OBJ_YAW_ANGLE_ERR_019:0, OBJ_YAW_RATE_019:448, OBJ_YAW_RATE_ERR_019:0]}, provided-interface=Pi_SG_TrackerObject019
      Pp_SG_TrackerObject056: nonqueued-sender-com-spec{data-element=Vdp_SG_TrackerObject056, init-value=fields=[OBJ_ACCEL_ERR_CRR_COEF_056:120, OBJ_ACCELERATION_LAT_056:400, OBJ_ACCELERATION_LAT_ERR_056:0, OBJ_ACCELERATION_LONG_056:400, OBJ_ACCELERATION_LONG_ERR_056:0, OBJ_ALIVE_TIME_056:0, OBJ_CLS_TYPE1_056:0, OBJ_CLS_TYPE1_PROB_056:0, OBJ_CLS_TYPE2_056:0, OBJ_CLS_TYPE2_PROB_056:0, OBJ_CLS_TYPE3_056:0, OBJ_CLS_TYPE3_PROB_056:0, OBJ_CLS_TYPE4_056:0, OBJ_CLS_TYPE4_PROB_056:0, OBJ_CLS_TYPE5_056:0, OBJ_CLS_TYPE5_PROB_056:0, OBJ_CLS_TYPE6_056:0, OBJ_CLS_TYPE6_PROB_056:0, OBJ_DIMENSION_LENGTH_056:0, OBJ_DIMENSION_LENGTH_ERR_056:0, OBJ_DIMENSION_WIDTH_056:0, OBJ_DIMENSION_WIDTH_ERR_056:0, OBJ_EXISTENCE_PROB_056:0, OBJ_GROUP_ID_056:0, OBJ_ID_056:0, OBJ_MEASUREMENT_STATUS_056:0, OBJ_MH_CRC16_056:0, OBJ_MH_CYCLE_COUNTER_056:0, OBJ_MOVEMENT_STATUS_056:0, OBJ_POS_ERR_CRR_COEF_056:120, OBJ_POS_LAT_056:32700, OBJ_POS_LAT_ERR_056:0, OBJ_POS_LONG_056:32700, OBJ_POS_LONG_ERR_056:0, OBJ_RCS_056:64, OBJ_REF_PT_LAT_OFFSET_056:0, OBJ_REF_PT_LONG_OFFSET_056:0, OBJ_TIMESTAMP_OFFSET_056:127, OBJ_TRACK_MOTION_MODEL_056:0, OBJ_VEH_TRACK_FLAG_056:0, OBJ_VELOCITY_ERR_CRR_COEF_056:120, OBJ_VELOCITY_LAT_056:16300, OBJ_VELOCITY_LAT_ERR_056:0, OBJ_VELOCITY_LONG_056:16300, OBJ_VELOCITY_LONG_ERR_056:0, OBJ_YAW_ANGLE_056:2000, OBJ_YAW_ANGLE_ERR_056:0, OBJ_YAW_RATE_056:448, OBJ_YAW_RATE_ERR_056:0]}, provided-interface=Pi_SG_TrackerObject056
      Pp_RDR_NM_CAN_NM_State: nonqueued-sender-com-spec{data-element=Vdp_RDR_NM_CAN_NM_State, init-value=0}, provided-interface=Pi_RDR_NM_CAN_NM_State_1
      Pp_SG_TrackerObject035: nonqueued-sender-com-spec{data-element=Vdp_SG_TrackerObject035, init-value=fields=[OBJ_ACCEL_ERR_CRR_COEF_035:120, OBJ_ACCELERATION_LAT_035:400, OBJ_ACCELERATION_LAT_ERR_035:0, OBJ_ACCELERATION_LONG_035:400, OBJ_ACCELERATION_LONG_ERR_035:0, OBJ_ALIVE_TIME_035:0, OBJ_CLS_TYPE1_035:0, OBJ_CLS_TYPE1_PROB_035:0, OBJ_CLS_TYPE2_035:0, OBJ_CLS_TYPE2_PROB_035:0, OBJ_CLS_TYPE3_035:0, OBJ_CLS_TYPE3_PROB_035:0, OBJ_CLS_TYPE4_035:0, OBJ_CLS_TYPE4_PROB_035:0, OBJ_CLS_TYPE5_035:0, OBJ_CLS_TYPE5_PROB_035:0, OBJ_CLS_TYPE6_035:0, OBJ_CLS_TYPE6_PROB_035:0, OBJ_DIMENSION_LENGTH_035:0, OBJ_DIMENSION_LENGTH_ERR_035:0, OBJ_DIMENSION_WIDTH_035:0, OBJ_DIMENSION_WIDTH_ERR_035:0, OBJ_EXISTENCE_PROB_035:0, OBJ_GROUP_ID_035:0, OBJ_ID_035:0, OBJ_MEASUREMENT_STATUS_035:0, OBJ_MH_CRC16_035:0, OBJ_MH_CYCLE_COUNTER_035:0, OBJ_MOVEMENT_STATUS_035:0, OBJ_POS_ERR_CRR_COEF_035:120, OBJ_POS_LAT_035:32700, OBJ_POS_LAT_ERR_035:0, OBJ_POS_LONG_035:32700, OBJ_POS_LONG_ERR_035:0, OBJ_RCS_035:64, OBJ_REF_PT_LAT_OFFSET_035:0, OBJ_REF_PT_LONG_OFFSET_035:0, OBJ_TIMESTAMP_OFFSET_035:127, OBJ_TRACK_MOTION_MODEL_035:0, OBJ_VEH_TRACK_FLAG_035:0, OBJ_VELOCITY_ERR_CRR_COEF_035:120, OBJ_VELOCITY_LAT_035:16300, OBJ_VELOCITY_LAT_ERR_035:0, OBJ_VELOCITY_LONG_035:16300, OBJ_VELOCITY_LONG_ERR_035:0, OBJ_YAW_ANGLE_035:2000, OBJ_YAW_ANGLE_ERR_035:0, OBJ_YAW_RATE_035:448, OBJ_YAW_RATE_ERR_035:0]}, provided-interface=Pi_SG_TrackerObject035
      Pp_SG_TrackerObject053: nonqueued-sender-com-spec{data-element=Vdp_SG_TrackerObject053, init-value=fields=[OBJ_ACCEL_ERR_CRR_COEF_053:120, OBJ_ACCELERATION_LAT_053:400, OBJ_ACCELERATION_LAT_ERR_053:0, OBJ_ACCELERATION_LONG_053:400, OBJ_ACCELERATION_LONG_ERR_053:0, OBJ_ALIVE_TIME_053:0, OBJ_CLS_TYPE1_053:0, OBJ_CLS_TYPE1_PROB_053:0, OBJ_CLS_TYPE2_053:0, OBJ_CLS_TYPE2_PROB_053:0, OBJ_CLS_TYPE3_053:0, OBJ_CLS_TYPE3_PROB_053:0, OBJ_CLS_TYPE4_053:0, OBJ_CLS_TYPE4_PROB_053:0, OBJ_CLS_TYPE5_053:0, OBJ_CLS_TYPE5_PROB_053:0, OBJ_CLS_TYPE6_053:0, OBJ_CLS_TYPE6_PROB_053:0, OBJ_DIMENSION_LENGTH_053:0, OBJ_DIMENSION_LENGTH_ERR_053:0, OBJ_DIMENSION_WIDTH_053:0, OBJ_DIMENSION_WIDTH_ERR_053:0, OBJ_EXISTENCE_PROB_053:0, OBJ_GROUP_ID_053:0, OBJ_ID_053:0, OBJ_MEASUREMENT_STATUS_053:0, OBJ_MH_CRC16_053:0, OBJ_MH_CYCLE_COUNTER_053:0, OBJ_MOVEMENT_STATUS_053:0, OBJ_POS_ERR_CRR_COEF_053:120, OBJ_POS_LAT_053:32700, OBJ_POS_LAT_ERR_053:0, OBJ_POS_LONG_053:32700, OBJ_POS_LONG_ERR_053:0, OBJ_RCS_053:64, OBJ_REF_PT_LAT_OFFSET_053:0, OBJ_REF_PT_LONG_OFFSET_053:0, OBJ_TIMESTAMP_OFFSET_053:127, OBJ_TRACK_MOTION_MODEL_053:0, OBJ_VEH_TRACK_FLAG_053:0, OBJ_VELOCITY_ERR_CRR_COEF_053:120, OBJ_VELOCITY_LAT_053:16300, OBJ_VELOCITY_LAT_ERR_053:0, OBJ_VELOCITY_LONG_053:16300, OBJ_VELOCITY_LONG_ERR_053:0, OBJ_YAW_ANGLE_053:2000, OBJ_YAW_ANGLE_ERR_053:0, OBJ_YAW_RATE_053:448, OBJ_YAW_RATE_ERR_053:0]}, provided-interface=Pi_SG_TrackerObject053
      Pp_SG_TrackerObject012: nonqueued-sender-com-spec{data-element=Vdp_SG_TrackerObject012, init-value=fields=[OBJ_ACCEL_ERR_CRR_COEF_012:120, OBJ_ACCELERATION_LAT_012:400, OBJ_ACCELERATION_LAT_ERR_012:0, OBJ_ACCELERATION_LONG_012:400, OBJ_ACCELERATION_LONG_ERR_012:0, OBJ_ALIVE_TIME_012:0, OBJ_CLS_TYPE1_012:0, OBJ_CLS_TYPE1_PROB_012:0, OBJ_CLS_TYPE2_012:0, OBJ_CLS_TYPE2_PROB_012:0, OBJ_CLS_TYPE3_012:0, OBJ_CLS_TYPE3_PROB_012:0, OBJ_CLS_TYPE4_012:0, OBJ_CLS_TYPE4_PROB_012:0, OBJ_CLS_TYPE5_012:0, OBJ_CLS_TYPE5_PROB_012:0, OBJ_CLS_TYPE6_012:0, OBJ_CLS_TYPE6_PROB_012:0, OBJ_DIMENSION_LENGTH_012:0, OBJ_DIMENSION_LENGTH_ERR_012:0, OBJ_DIMENSION_WIDTH_012:0, OBJ_DIMENSION_WIDTH_ERR_012:0, OBJ_EXISTENCE_PROB_012:0, OBJ_GROUP_ID_012:0, OBJ_ID_012:0, OBJ_MEASUREMENT_STATUS_012:0, OBJ_MH_CRC16_012:0, OBJ_MH_CYCLE_COUNTER_012:0, OBJ_MOVEMENT_STATUS_012:0, OBJ_POS_ERR_CRR_COEF_012:120, OBJ_POS_LAT_012:32700, OBJ_POS_LAT_ERR_012:0, OBJ_POS_LONG_012:32700, OBJ_POS_LONG_ERR_012:0, OBJ_RCS_012:64, OBJ_REF_PT_LAT_OFFSET_012:0, OBJ_REF_PT_LONG_OFFSET_012:0, OBJ_TIMESTAMP_OFFSET_012:127, OBJ_TRACK_MOTION_MODEL_012:0, OBJ_VEH_TRACK_FLAG_012:0, OBJ_VELOCITY_ERR_CRR_COEF_012:120, OBJ_VELOCITY_LAT_012:16300, OBJ_VELOCITY_LAT_ERR_012:0, OBJ_VELOCITY_LONG_012:16300, OBJ_VELOCITY_LONG_ERR_012:0, OBJ_YAW_ANGLE_012:2000, OBJ_YAW_ANGLE_ERR_012:0, OBJ_YAW_RATE_012:448, OBJ_YAW_RATE_ERR_012:0]}, provided-interface=Pi_SG_TrackerObject012
      Pp_RDR_NM_CBV_ResdBit_1: nonqueued-sender-com-spec{data-element=Vdp_RDR_NM_CBV_ResdBit_1, init-value=0}, provided-interface=Pi_RDR_NM_CBV_ResdBit_3
      Pp_SG_TrackerObject011: nonqueued-sender-com-spec{data-element=Vdp_SG_TrackerObject011, init-value=fields=[OBJ_ACCEL_ERR_CRR_COEF_011:120, OBJ_ACCELERATION_LAT_011:400, OBJ_ACCELERATION_LAT_ERR_011:0, OBJ_ACCELERATION_LONG_011:400, OBJ_ACCELERATION_LONG_ERR_011:0, OBJ_ALIVE_TIME_011:0, OBJ_CLS_TYPE1_011:0, OBJ_CLS_TYPE1_PROB_011:0, OBJ_CLS_TYPE2_011:0, OBJ_CLS_TYPE2_PROB_011:0, OBJ_CLS_TYPE3_011:0, OBJ_CLS_TYPE3_PROB_011:0, OBJ_CLS_TYPE4_011:0, OBJ_CLS_TYPE4_PROB_011:0, OBJ_CLS_TYPE5_011:0, OBJ_CLS_TYPE5_PROB_011:0, OBJ_CLS_TYPE6_011:0, OBJ_CLS_TYPE6_PROB_011:0, OBJ_DIMENSION_LENGTH_011:0, OBJ_DIMENSION_LENGTH_ERR_011:0, OBJ_DIMENSION_WIDTH_011:0, OBJ_DIMENSION_WIDTH_ERR_011:0, OBJ_EXISTENCE_PROB_011:0, OBJ_GROUP_ID_011:0, OBJ_ID_011:0, OBJ_MEASUREMENT_STATUS_011:0, OBJ_MH_CRC16_011:0, OBJ_MH_CYCLE_COUNTER_011:0, OBJ_MOVEMENT_STATUS_011:0, OBJ_POS_ERR_CRR_COEF_011:120, OBJ_POS_LAT_011:32700, OBJ_POS_LAT_ERR_011:0, OBJ_POS_LONG_011:32700, OBJ_POS_LONG_ERR_011:0, OBJ_RCS_011:64, OBJ_REF_PT_LAT_OFFSET_011:0, OBJ_REF_PT_LONG_OFFSET_011:0, OBJ_TIMESTAMP_OFFSET_011:127, OBJ_TRACK_MOTION_MODEL_011:0, OBJ_VEH_TRACK_FLAG_011:0, OBJ_VELOCITY_ERR_CRR_COEF_011:120, OBJ_VELOCITY_LAT_011:16300, OBJ_VELOCITY_LAT_ERR_011:0, OBJ_VELOCITY_LONG_011:16300, OBJ_VELOCITY_LONG_ERR_011:0, OBJ_YAW_ANGLE_011:2000, OBJ_YAW_ANGLE_ERR_011:0, OBJ_YAW_RATE_011:448, OBJ_YAW_RATE_ERR_011:0]}, provided-interface=Pi_SG_TrackerObject011
      Pp_SG_TrackerObject054: nonqueued-sender-com-spec{data-element=Vdp_SG_TrackerObject054, init-value=fields=[OBJ_ACCEL_ERR_CRR_COEF_054:120, OBJ_ACCELERATION_LAT_054:400, OBJ_ACCELERATION_LAT_ERR_054:0, OBJ_ACCELERATION_LONG_054:400, OBJ_ACCELERATION_LONG_ERR_054:0, OBJ_ALIVE_TIME_054:0, OBJ_CLS_TYPE1_054:0, OBJ_CLS_TYPE1_PROB_054:0, OBJ_CLS_TYPE2_054:0, OBJ_CLS_TYPE2_PROB_054:0, OBJ_CLS_TYPE3_054:0, OBJ_CLS_TYPE3_PROB_054:0, OBJ_CLS_TYPE4_054:0, OBJ_CLS_TYPE4_PROB_054:0, OBJ_CLS_TYPE5_054:0, OBJ_CLS_TYPE5_PROB_054:0, OBJ_CLS_TYPE6_054:0, OBJ_CLS_TYPE6_PROB_054:0, OBJ_DIMENSION_LENGTH_054:0, OBJ_DIMENSION_LENGTH_ERR_054:0, OBJ_DIMENSION_WIDTH_054:0, OBJ_DIMENSION_WIDTH_ERR_054:0, OBJ_EXISTENCE_PROB_054:0, OBJ_GROUP_ID_054:0, OBJ_ID_054:0, OBJ_MEASUREMENT_STATUS_054:0, OBJ_MH_CRC16_054:0, OBJ_MH_CYCLE_COUNTER_054:0, OBJ_MOVEMENT_STATUS_054:0, OBJ_POS_ERR_CRR_COEF_054:120, OBJ_POS_LAT_054:32700, OBJ_POS_LAT_ERR_054:0, OBJ_POS_LONG_054:32700, OBJ_POS_LONG_ERR_054:0, OBJ_RCS_054:64, OBJ_REF_PT_LAT_OFFSET_054:0, OBJ_REF_PT_LONG_OFFSET_054:0, OBJ_TIMESTAMP_OFFSET_054:127, OBJ_TRACK_MOTION_MODEL_054:0, OBJ_VEH_TRACK_FLAG_054:0, OBJ_VELOCITY_ERR_CRR_COEF_054:120, OBJ_VELOCITY_LAT_054:16300, OBJ_VELOCITY_LAT_ERR_054:0, OBJ_VELOCITY_LONG_054:16300, OBJ_VELOCITY_LONG_ERR_054:0, OBJ_YAW_ANGLE_054:2000, OBJ_YAW_ANGLE_ERR_054:0, OBJ_YAW_RATE_054:448, OBJ_YAW_RATE_ERR_054:0]}, provided-interface=Pi_SG_TrackerObject054
      Pp_SG_TrackerObject037: nonqueued-sender-com-spec{data-element=Vdp_SG_TrackerObject037, init-value=fields=[OBJ_ACCEL_ERR_CRR_COEF_037:120, OBJ_ACCELERATION_LAT_037:400, OBJ_ACCELERATION_LAT_ERR_037:0, OBJ_ACCELERATION_LONG_037:400, OBJ_ACCELERATION_LONG_ERR_037:0, OBJ_ALIVE_TIME_037:0, OBJ_CLS_TYPE1_037:0, OBJ_CLS_TYPE1_PROB_037:0, OBJ_CLS_TYPE2_037:0, OBJ_CLS_TYPE2_PROB_037:0, OBJ_CLS_TYPE3_037:0, OBJ_CLS_TYPE3_PROB_037:0, OBJ_CLS_TYPE4_037:0, OBJ_CLS_TYPE4_PROB_037:0, OBJ_CLS_TYPE5_037:0, OBJ_CLS_TYPE5_PROB_037:0, OBJ_CLS_TYPE6_037:0, OBJ_CLS_TYPE6_PROB_037:0, OBJ_DIMENSION_LENGTH_037:0, OBJ_DIMENSION_LENGTH_ERR_037:0, OBJ_DIMENSION_WIDTH_037:0, OBJ_DIMENSION_WIDTH_ERR_037:0, OBJ_EXISTENCE_PROB_037:0, OBJ_GROUP_ID_037:0, OBJ_ID_037:0, OBJ_MEASUREMENT_STATUS_037:0, OBJ_MH_CRC16_037:0, OBJ_MH_CYCLE_COUNTER_037:0, OBJ_MOVEMENT_STATUS_037:0, OBJ_POS_ERR_CRR_COEF_037:120, OBJ_POS_LAT_037:32700, OBJ_POS_LAT_ERR_037:0, OBJ_POS_LONG_037:32700, OBJ_POS_LONG_ERR_037:0, OBJ_RCS_037:64, OBJ_REF_PT_LAT_OFFSET_037:0, OBJ_REF_PT_LONG_OFFSET_037:0, OBJ_TIMESTAMP_OFFSET_037:127, OBJ_TRACK_MOTION_MODEL_037:0, OBJ_VEH_TRACK_FLAG_037:0, OBJ_VELOCITY_ERR_CRR_COEF_037:120, OBJ_VELOCITY_LAT_037:16300, OBJ_VELOCITY_LAT_ERR_037:0, OBJ_VELOCITY_LONG_037:16300, OBJ_VELOCITY_LONG_ERR_037:0, OBJ_YAW_ANGLE_037:2000, OBJ_YAW_ANGLE_ERR_037:0, OBJ_YAW_RATE_037:448, OBJ_YAW_RATE_ERR_037:0]}, provided-interface=Pi_SG_TrackerObject037
      Pp_SG_TrackerObject023: nonqueued-sender-com-spec{data-element=Vdp_SG_TrackerObject023, init-value=fields=[OBJ_ACCEL_ERR_CRR_COEF_023:120, OBJ_ACCELERATION_LAT_023:400, OBJ_ACCELERATION_LAT_ERR_023:0, OBJ_ACCELERATION_LONG_023:400, OBJ_ACCELERATION_LONG_ERR_023:0, OBJ_ALIVE_TIME_023:0, OBJ_CLS_TYPE1_023:0, OBJ_CLS_TYPE1_PROB_023:0, OBJ_CLS_TYPE2_023:0, OBJ_CLS_TYPE2_PROB_023:0, OBJ_CLS_TYPE3_023:0, OBJ_CLS_TYPE3_PROB_023:0, OBJ_CLS_TYPE4_023:0, OBJ_CLS_TYPE4_PROB_023:0, OBJ_CLS_TYPE5_023:0, OBJ_CLS_TYPE5_PROB_023:0, OBJ_CLS_TYPE6_023:0, OBJ_CLS_TYPE6_PROB_023:0, OBJ_DIMENSION_LENGTH_023:0, OBJ_DIMENSION_LENGTH_ERR_023:0, OBJ_DIMENSION_WIDTH_023:0, OBJ_DIMENSION_WIDTH_ERR_023:0, OBJ_EXISTENCE_PROB_023:0, OBJ_GROUP_ID_023:0, OBJ_ID_023:0, OBJ_MEASUREMENT_STATUS_023:0, OBJ_MH_CRC16_023:0, OBJ_MH_CYCLE_COUNTER_023:0, OBJ_MOVEMENT_STATUS_023:0, OBJ_POS_ERR_CRR_COEF_023:120, OBJ_POS_LAT_023:32700, OBJ_POS_LAT_ERR_023:0, OBJ_POS_LONG_023:32700, OBJ_POS_LONG_ERR_023:0, OBJ_RCS_023:64, OBJ_REF_PT_LAT_OFFSET_023:0, OBJ_REF_PT_LONG_OFFSET_023:0, OBJ_TIMESTAMP_OFFSET_023:127, OBJ_TRACK_MOTION_MODEL_023:0, OBJ_VEH_TRACK_FLAG_023:0, OBJ_VELOCITY_ERR_CRR_COEF_023:120, OBJ_VELOCITY_LAT_023:16300, OBJ_VELOCITY_LAT_ERR_023:0, OBJ_VELOCITY_LONG_023:16300, OBJ_VELOCITY_LONG_ERR_023:0, OBJ_YAW_ANGLE_023:2000, OBJ_YAW_ANGLE_ERR_023:0, OBJ_YAW_RATE_023:448, OBJ_YAW_RATE_ERR_023:0]}, provided-interface=Pi_SG_TrackerObject023
      Pp_SG_TrackerObject047: nonqueued-sender-com-spec{data-element=Vdp_SG_TrackerObject047, init-value=fields=[OBJ_ACCEL_ERR_CRR_COEF_047:120, OBJ_ACCELERATION_LAT_047:400, OBJ_ACCELERATION_LAT_ERR_047:0, OBJ_ACCELERATION_LONG_047:400, OBJ_ACCELERATION_LONG_ERR_047:0, OBJ_ALIVE_TIME_047:0, OBJ_CLS_TYPE1_047:0, OBJ_CLS_TYPE1_PROB_047:0, OBJ_CLS_TYPE2_047:0, OBJ_CLS_TYPE2_PROB_047:0, OBJ_CLS_TYPE3_047:0, OBJ_CLS_TYPE3_PROB_047:0, OBJ_CLS_TYPE4_047:0, OBJ_CLS_TYPE4_PROB_047:0, OBJ_CLS_TYPE5_047:0, OBJ_CLS_TYPE5_PROB_047:0, OBJ_CLS_TYPE6_047:0, OBJ_CLS_TYPE6_PROB_047:0, OBJ_DIMENSION_LENGTH_047:0, OBJ_DIMENSION_LENGTH_ERR_047:0, OBJ_DIMENSION_WIDTH_047:0, OBJ_DIMENSION_WIDTH_ERR_047:0, OBJ_EXISTENCE_PROB_047:0, OBJ_GROUP_ID_047:0, OBJ_ID_047:0, OBJ_MEASUREMENT_STATUS_047:0, OBJ_MH_CRC16_047:0, OBJ_MH_CYCLE_COUNTER_047:0, OBJ_MOVEMENT_STATUS_047:0, OBJ_POS_ERR_CRR_COEF_047:120, OBJ_POS_LAT_047:32700, OBJ_POS_LAT_ERR_047:0, OBJ_POS_LONG_047:32700, OBJ_POS_LONG_ERR_047:0, OBJ_RCS_047:64, OBJ_REF_PT_LAT_OFFSET_047:0, OBJ_REF_PT_LONG_OFFSET_047:0, OBJ_TIMESTAMP_OFFSET_047:127, OBJ_TRACK_MOTION_MODEL_047:0, OBJ_VEH_TRACK_FLAG_047:0, OBJ_VELOCITY_ERR_CRR_COEF_047:120, OBJ_VELOCITY_LAT_047:16300, OBJ_VELOCITY_LAT_ERR_047:0, OBJ_VELOCITY_LONG_047:16300, OBJ_VELOCITY_LONG_ERR_047:0, OBJ_YAW_ANGLE_047:2000, OBJ_YAW_ANGLE_ERR_047:0, OBJ_YAW_RATE_047:448, OBJ_YAW_RATE_ERR_047:0]}, provided-interface=Pi_SG_TrackerObject047
      Pp_SG_TrackerObject027: nonqueued-sender-com-spec{data-element=Vdp_SG_TrackerObject027, init-value=fields=[OBJ_ACCEL_ERR_CRR_COEF_027:120, OBJ_ACCELERATION_LAT_027:400, OBJ_ACCELERATION_LAT_ERR_027:0, OBJ_ACCELERATION_LONG_027:400, OBJ_ACCELERATION_LONG_ERR_027:0, OBJ_ALIVE_TIME_027:0, OBJ_CLS_TYPE1_027:0, OBJ_CLS_TYPE1_PROB_027:0, OBJ_CLS_TYPE2_027:0, OBJ_CLS_TYPE2_PROB_027:0, OBJ_CLS_TYPE3_027:0, OBJ_CLS_TYPE3_PROB_027:0, OBJ_CLS_TYPE4_027:0, OBJ_CLS_TYPE4_PROB_027:0, OBJ_CLS_TYPE5_027:0, OBJ_CLS_TYPE5_PROB_027:0, OBJ_CLS_TYPE6_027:0, OBJ_CLS_TYPE6_PROB_027:0, OBJ_DIMENSION_LENGTH_027:0, OBJ_DIMENSION_LENGTH_ERR_027:0, OBJ_DIMENSION_WIDTH_027:0, OBJ_DIMENSION_WIDTH_ERR_027:0, OBJ_EXISTENCE_PROB_027:0, OBJ_GROUP_ID_027:0, OBJ_ID_027:0, OBJ_MEASUREMENT_STATUS_027:0, OBJ_MH_CRC16_027:0, OBJ_MH_CYCLE_COUNTER_027:0, OBJ_MOVEMENT_STATUS_027:0, OBJ_POS_ERR_CRR_COEF_027:120, OBJ_POS_LAT_027:32700, OBJ_POS_LAT_ERR_027:0, OBJ_POS_LONG_027:32700, OBJ_POS_LONG_ERR_027:0, OBJ_RCS_027:64, OBJ_REF_PT_LAT_OFFSET_027:0, OBJ_REF_PT_LONG_OFFSET_027:0, OBJ_TIMESTAMP_OFFSET_027:127, OBJ_TRACK_MOTION_MODEL_027:0, OBJ_VEH_TRACK_FLAG_027:0, OBJ_VELOCITY_ERR_CRR_COEF_027:120, OBJ_VELOCITY_LAT_027:16300, OBJ_VELOCITY_LAT_ERR_027:0, OBJ_VELOCITY_LONG_027:16300, OBJ_VELOCITY_LONG_ERR_027:0, OBJ_YAW_ANGLE_027:2000, OBJ_YAW_ANGLE_ERR_027:0, OBJ_YAW_RATE_027:448, OBJ_YAW_RATE_ERR_027:0]}, provided-interface=Pi_SG_TrackerObject027
      Pp_SG_TrackerObject007: nonqueued-sender-com-spec{data-element=Vdp_SG_TrackerObject007, init-value=fields=[OBJ_ACCEL_ERR_CRR_COEF_007:120, OBJ_ACCELERATION_LAT_007:400, OBJ_ACCELERATION_LAT_ERR_007:0, OBJ_ACCELERATION_LONG_007:400, OBJ_ACCELERATION_LONG_ERR_007:0, OBJ_ALIVE_TIME_007:0, OBJ_CLS_TYPE1_007:0, OBJ_CLS_TYPE1_PROB_007:0, OBJ_CLS_TYPE2_007:0, OBJ_CLS_TYPE2_PROB_007:0, OBJ_CLS_TYPE3_007:0, OBJ_CLS_TYPE3_PROB_007:0, OBJ_CLS_TYPE4_007:0, OBJ_CLS_TYPE4_PROB_007:0, OBJ_CLS_TYPE5_007:0, OBJ_CLS_TYPE5_PROB_007:0, OBJ_CLS_TYPE6_007:0, OBJ_CLS_TYPE6_PROB_007:0, OBJ_DIMENSION_LENGTH_007:0, OBJ_DIMENSION_LENGTH_ERR_007:0, OBJ_DIMENSION_WIDTH_007:0, OBJ_DIMENSION_WIDTH_ERR_007:0, OBJ_EXISTENCE_PROB_007:0, OBJ_GROUP_ID_007:0, OBJ_ID_007:0, OBJ_MEASUREMENT_STATUS_007:0, OBJ_MH_CRC16_007:0, OBJ_MH_CYCLE_COUNTER_007:0, OBJ_MOVEMENT_STATUS_007:0, OBJ_POS_ERR_CRR_COEF_007:120, OBJ_POS_LAT_007:32700, OBJ_POS_LAT_ERR_007:0, OBJ_POS_LONG_007:32700, OBJ_POS_LONG_ERR_007:0, OBJ_RCS_007:64, OBJ_REF_PT_LAT_OFFSET_007:0, OBJ_REF_PT_LONG_OFFSET_007:0, OBJ_TIMESTAMP_OFFSET_007:127, OBJ_TRACK_MOTION_MODEL_007:0, OBJ_VEH_TRACK_FLAG_007:0, OBJ_VELOCITY_ERR_CRR_COEF_007:120, OBJ_VELOCITY_LAT_007:16300, OBJ_VELOCITY_LAT_ERR_007:0, OBJ_VELOCITY_LONG_007:16300, OBJ_VELOCITY_LONG_ERR_007:0, OBJ_YAW_ANGLE_007:2000, OBJ_YAW_ANGLE_ERR_007:0, OBJ_YAW_RATE_007:448, OBJ_YAW_RATE_ERR_007:0]}, provided-interface=Pi_SG_TrackerObject007
      Pp_SG_TrackerObject016: nonqueued-sender-com-spec{data-element=Vdp_SG_TrackerObject016, init-value=fields=[OBJ_ACCEL_ERR_CRR_COEF_016:120, OBJ_ACCELERATION_LAT_016:400, OBJ_ACCELERATION_LAT_ERR_016:0, OBJ_ACCELERATION_LONG_016:400, OBJ_ACCELERATION_LONG_ERR_016:0, OBJ_ALIVE_TIME_016:0, OBJ_CLS_TYPE1_016:0, OBJ_CLS_TYPE1_PROB_016:0, OBJ_CLS_TYPE2_016:0, OBJ_CLS_TYPE2_PROB_016:0, OBJ_CLS_TYPE3_016:0, OBJ_CLS_TYPE3_PROB_016:0, OBJ_CLS_TYPE4_016:0, OBJ_CLS_TYPE4_PROB_016:0, OBJ_CLS_TYPE5_016:0, OBJ_CLS_TYPE5_PROB_016:0, OBJ_CLS_TYPE6_016:0, OBJ_CLS_TYPE6_PROB_016:0, OBJ_DIMENSION_LENGTH_016:0, OBJ_DIMENSION_LENGTH_ERR_016:0, OBJ_DIMENSION_WIDTH_016:0, OBJ_DIMENSION_WIDTH_ERR_016:0, OBJ_EXISTENCE_PROB_016:0, OBJ_GROUP_ID_016:0, OBJ_ID_016:0, OBJ_MEASUREMENT_STATUS_016:0, OBJ_MH_CRC16_016:0, OBJ_MH_CYCLE_COUNTER_016:0, OBJ_MOVEMENT_STATUS_016:0, OBJ_POS_ERR_CRR_COEF_016:120, OBJ_POS_LAT_016:32700, OBJ_POS_LAT_ERR_016:0, OBJ_POS_LONG_016:32700, OBJ_POS_LONG_ERR_016:0, OBJ_RCS_016:64, OBJ_REF_PT_LAT_OFFSET_016:0, OBJ_REF_PT_LONG_OFFSET_016:0, OBJ_TIMESTAMP_OFFSET_016:127, OBJ_TRACK_MOTION_MODEL_016:0, OBJ_VEH_TRACK_FLAG_016:0, OBJ_VELOCITY_ERR_CRR_COEF_016:120, OBJ_VELOCITY_LAT_016:16300, OBJ_VELOCITY_LAT_ERR_016:0, OBJ_VELOCITY_LONG_016:16300, OBJ_VELOCITY_LONG_ERR_016:0, OBJ_YAW_ANGLE_016:2000, OBJ_YAW_ANGLE_ERR_016:0, OBJ_YAW_RATE_016:448, OBJ_YAW_RATE_ERR_016:0]}, provided-interface=Pi_SG_TrackerObject016
      Pp_SG_TrackerObject039: nonqueued-sender-com-spec{data-element=Vdp_SG_TrackerObject039, init-value=fields=[OBJ_ACCEL_ERR_CRR_COEF_039:120, OBJ_ACCELERATION_LAT_039:400, OBJ_ACCELERATION_LAT_ERR_039:0, OBJ_ACCELERATION_LONG_039:400, OBJ_ACCELERATION_LONG_ERR_039:0, OBJ_ALIVE_TIME_039:0, OBJ_CLS_TYPE1_039:0, OBJ_CLS_TYPE1_PROB_039:0, OBJ_CLS_TYPE2_039:0, OBJ_CLS_TYPE2_PROB_039:0, OBJ_CLS_TYPE3_039:0, OBJ_CLS_TYPE3_PROB_039:0, OBJ_CLS_TYPE4_039:0, OBJ_CLS_TYPE4_PROB_039:0, OBJ_CLS_TYPE5_039:0, OBJ_CLS_TYPE5_PROB_039:0, OBJ_CLS_TYPE6_039:0, OBJ_CLS_TYPE6_PROB_039:0, OBJ_DIMENSION_LENGTH_039:0, OBJ_DIMENSION_LENGTH_ERR_039:0, OBJ_DIMENSION_WIDTH_039:0, OBJ_DIMENSION_WIDTH_ERR_039:0, OBJ_EXISTENCE_PROB_039:0, OBJ_GROUP_ID_039:0, OBJ_ID_039:0, OBJ_MEASUREMENT_STATUS_039:0, OBJ_MH_CRC16_039:0, OBJ_MH_CYCLE_COUNTER_039:0, OBJ_MOVEMENT_STATUS_039:0, OBJ_POS_ERR_CRR_COEF_039:120, OBJ_POS_LAT_039:32700, OBJ_POS_LAT_ERR_039:0, OBJ_POS_LONG_039:32700, OBJ_POS_LONG_ERR_039:0, OBJ_RCS_039:64, OBJ_REF_PT_LAT_OFFSET_039:0, OBJ_REF_PT_LONG_OFFSET_039:0, OBJ_TIMESTAMP_OFFSET_039:127, OBJ_TRACK_MOTION_MODEL_039:0, OBJ_VEH_TRACK_FLAG_039:0, OBJ_VELOCITY_ERR_CRR_COEF_039:120, OBJ_VELOCITY_LAT_039:16300, OBJ_VELOCITY_LAT_ERR_039:0, OBJ_VELOCITY_LONG_039:16300, OBJ_VELOCITY_LONG_ERR_039:0, OBJ_YAW_ANGLE_039:2000, OBJ_YAW_ANGLE_ERR_039:0, OBJ_YAW_RATE_039:448, OBJ_YAW_RATE_ERR_039:0]}, provided-interface=Pi_SG_TrackerObject039
      Pp_SG_TrackerObject055: nonqueued-sender-com-spec{data-element=Vdp_SG_TrackerObject055, init-value=fields=[OBJ_ACCEL_ERR_CRR_COEF_055:120, OBJ_ACCELERATION_LAT_055:400, OBJ_ACCELERATION_LAT_ERR_055:0, OBJ_ACCELERATION_LONG_055:400, OBJ_ACCELERATION_LONG_ERR_055:0, OBJ_ALIVE_TIME_055:0, OBJ_CLS_TYPE1_055:0, OBJ_CLS_TYPE1_PROB_055:0, OBJ_CLS_TYPE2_055:0, OBJ_CLS_TYPE2_PROB_055:0, OBJ_CLS_TYPE3_055:0, OBJ_CLS_TYPE3_PROB_055:0, OBJ_CLS_TYPE4_055:0, OBJ_CLS_TYPE4_PROB_055:0, OBJ_CLS_TYPE5_055:0, OBJ_CLS_TYPE5_PROB_055:0, OBJ_CLS_TYPE6_055:0, OBJ_CLS_TYPE6_PROB_055:0, OBJ_DIMENSION_LENGTH_055:0, OBJ_DIMENSION_LENGTH_ERR_055:0, OBJ_DIMENSION_WIDTH_055:0, OBJ_DIMENSION_WIDTH_ERR_055:0, OBJ_EXISTENCE_PROB_055:0, OBJ_GROUP_ID_055:0, OBJ_ID_055:0, OBJ_MEASUREMENT_STATUS_055:0, OBJ_MH_CRC16_055:0, OBJ_MH_CYCLE_COUNTER_055:0, OBJ_MOVEMENT_STATUS_055:0, OBJ_POS_ERR_CRR_COEF_055:120, OBJ_POS_LAT_055:32700, OBJ_POS_LAT_ERR_055:0, OBJ_POS_LONG_055:32700, OBJ_POS_LONG_ERR_055:0, OBJ_RCS_055:64, OBJ_REF_PT_LAT_OFFSET_055:0, OBJ_REF_PT_LONG_OFFSET_055:0, OBJ_TIMESTAMP_OFFSET_055:127, OBJ_TRACK_MOTION_MODEL_055:0, OBJ_VEH_TRACK_FLAG_055:0, OBJ_VELOCITY_ERR_CRR_COEF_055:120, OBJ_VELOCITY_LAT_055:16300, OBJ_VELOCITY_LAT_ERR_055:0, OBJ_VELOCITY_LONG_055:16300, OBJ_VELOCITY_LONG_ERR_055:0, OBJ_YAW_ANGLE_055:2000, OBJ_YAW_ANGLE_ERR_055:0, OBJ_YAW_RATE_055:448, OBJ_YAW_RATE_ERR_055:0]}, provided-interface=Pi_SG_TrackerObject055
      Pp_SG_TrackerHeader: nonqueued-sender-com-spec{data-element=Vdp_SG_TrackerHeader, init-value=fields=[HED_MH_002_CRC16:0, HED_MH_002_CYCLE_COUNTER:0, HED_TRKR_DATA_QUALIFIER:0, HED_TRKR_IDX:0, HED_TRKR_NUM_OF_ACTIV_OBJS:0, HED_TRKR_OBJLST_TIME_STAMP_NS:0, HED_TRKR_OBJLST_TIME_STAMP_SC:0, HED_TRKR_TIME_INST:0, HED_TRKR_TIME_PEAK:0, HED_TRKR_VEH_COORD_TYPE:0, HED_TRKR_VEHICLE_IDX:0]}, provided-interface=Pi_SG_TrackerHeader
      Pp_SG_TrackerStatus: nonqueued-sender-com-spec{data-element=Vdp_SG_TrackerStatus, init-value=fields=[STS_MH_003_CRC16:0, STS_MH_003_CYCLE_COUNTER:0, STS_OBJ_DBC_BASE_VER_MAJOR:0, STS_OBJ_DBC_BASE_VER_MINOR:0, STS_PERCEPTION_MODULE_ID:0, STS_TRKR_MAJOR_VERSION:0, STS_TRKR_MINOR_VERSION:0, STS_TRKR_PATCH_VERSION:0]}, provided-interface=Pi_SG_TrackerStatus
      Pp_SG_TrackerObject024: nonqueued-sender-com-spec{data-element=Vdp_SG_TrackerObject024, init-value=fields=[OBJ_ACCEL_ERR_CRR_COEF_024:120, OBJ_ACCELERATION_LAT_024:400, OBJ_ACCELERATION_LAT_ERR_024:0, OBJ_ACCELERATION_LONG_024:400, OBJ_ACCELERATION_LONG_ERR_024:0, OBJ_ALIVE_TIME_024:0, OBJ_CLS_TYPE1_024:0, OBJ_CLS_TYPE1_PROB_024:0, OBJ_CLS_TYPE2_024:0, OBJ_CLS_TYPE2_PROB_024:0, OBJ_CLS_TYPE3_024:0, OBJ_CLS_TYPE3_PROB_024:0, OBJ_CLS_TYPE4_024:0, OBJ_CLS_TYPE4_PROB_024:0, OBJ_CLS_TYPE5_024:0, OBJ_CLS_TYPE5_PROB_024:0, OBJ_CLS_TYPE6_024:0, OBJ_CLS_TYPE6_PROB_024:0, OBJ_DIMENSION_LENGTH_024:0, OBJ_DIMENSION_LENGTH_ERR_024:0, OBJ_DIMENSION_WIDTH_024:0, OBJ_DIMENSION_WIDTH_ERR_024:0, OBJ_EXISTENCE_PROB_024:0, OBJ_GROUP_ID_024:0, OBJ_ID_024:0, OBJ_MEASUREMENT_STATUS_024:0, OBJ_MH_CRC16_024:0, OBJ_MH_CYCLE_COUNTER_024:0, OBJ_MOVEMENT_STATUS_024:0, OBJ_POS_ERR_CRR_COEF_024:120, OBJ_POS_LAT_024:32700, OBJ_POS_LAT_ERR_024:0, OBJ_POS_LONG_024:32700, OBJ_POS_LONG_ERR_024:0, OBJ_RCS_024:64, OBJ_REF_PT_LAT_OFFSET_024:0, OBJ_REF_PT_LONG_OFFSET_024:0, OBJ_TIMESTAMP_OFFSET_024:127, OBJ_TRACK_MOTION_MODEL_024:0, OBJ_VEH_TRACK_FLAG_024:0, OBJ_VELOCITY_ERR_CRR_COEF_024:120, OBJ_VELOCITY_LAT_024:16300, OBJ_VELOCITY_LAT_ERR_024:0, OBJ_VELOCITY_LONG_024:16300, OBJ_VELOCITY_LONG_ERR_024:0, OBJ_YAW_ANGLE_024:2000, OBJ_YAW_ANGLE_ERR_024:0, OBJ_YAW_RATE_024:448, OBJ_YAW_RATE_ERR_024:0]}, provided-interface=Pi_SG_TrackerObject024
      Pp_SG_TrackerObject014: nonqueued-sender-com-spec{data-element=Vdp_SG_TrackerObject014, init-value=fields=[OBJ_ACCEL_ERR_CRR_COEF_014:120, OBJ_ACCELERATION_LAT_014:400, OBJ_ACCELERATION_LAT_ERR_014:0, OBJ_ACCELERATION_LONG_014:400, OBJ_ACCELERATION_LONG_ERR_014:0, OBJ_ALIVE_TIME_014:0, OBJ_CLS_TYPE1_014:0, OBJ_CLS_TYPE1_PROB_014:0, OBJ_CLS_TYPE2_014:0, OBJ_CLS_TYPE2_PROB_014:0, OBJ_CLS_TYPE3_014:0, OBJ_CLS_TYPE3_PROB_014:0, OBJ_CLS_TYPE4_014:0, OBJ_CLS_TYPE4_PROB_014:0, OBJ_CLS_TYPE5_014:0, OBJ_CLS_TYPE5_PROB_014:0, OBJ_CLS_TYPE6_014:0, OBJ_CLS_TYPE6_PROB_014:0, OBJ_DIMENSION_LENGTH_014:0, OBJ_DIMENSION_LENGTH_ERR_014:0, OBJ_DIMENSION_WIDTH_014:0, OBJ_DIMENSION_WIDTH_ERR_014:0, OBJ_EXISTENCE_PROB_014:0, OBJ_GROUP_ID_014:0, OBJ_ID_014:0, OBJ_MEASUREMENT_STATUS_014:0, OBJ_MH_CRC16_014:0, OBJ_MH_CYCLE_COUNTER_014:0, OBJ_MOVEMENT_STATUS_014:0, OBJ_POS_ERR_CRR_COEF_014:120, OBJ_POS_LAT_014:32700, OBJ_POS_LAT_ERR_014:0, OBJ_POS_LONG_014:32700, OBJ_POS_LONG_ERR_014:0, OBJ_RCS_014:64, OBJ_REF_PT_LAT_OFFSET_014:0, OBJ_REF_PT_LONG_OFFSET_014:0, OBJ_TIMESTAMP_OFFSET_014:127, OBJ_TRACK_MOTION_MODEL_014:0, OBJ_VEH_TRACK_FLAG_014:0, OBJ_VELOCITY_ERR_CRR_COEF_014:120, OBJ_VELOCITY_LAT_014:16300, OBJ_VELOCITY_LAT_ERR_014:0, OBJ_VELOCITY_LONG_014:16300, OBJ_VELOCITY_LONG_ERR_014:0, OBJ_YAW_ANGLE_014:2000, OBJ_YAW_ANGLE_ERR_014:0, OBJ_YAW_RATE_014:448, OBJ_YAW_RATE_ERR_014:0]}, provided-interface=Pi_SG_TrackerObject014
      Pp_RDR_NM_PNC_Reserved2: nonqueued-sender-com-spec{data-element=Vdp_RDR_NM_PNC_Reserved2, init-value=0}, provided-interface=Pi_RDR_NM_PNC_Reserved2_1
      Pp_SG_TrackerObject009: nonqueued-sender-com-spec{data-element=Vdp_SG_TrackerObject009, init-value=fields=[OBJ_ACCEL_ERR_CRR_COEF_009:120, OBJ_ACCELERATION_LAT_009:400, OBJ_ACCELERATION_LAT_ERR_009:0, OBJ_ACCELERATION_LONG_009:400, OBJ_ACCELERATION_LONG_ERR_009:0, OBJ_ALIVE_TIME_009:0, OBJ_CLS_TYPE1_009:0, OBJ_CLS_TYPE1_PROB_009:0, OBJ_CLS_TYPE2_009:0, OBJ_CLS_TYPE2_PROB_009:0, OBJ_CLS_TYPE3_009:0, OBJ_CLS_TYPE3_PROB_009:0, OBJ_CLS_TYPE4_009:0, OBJ_CLS_TYPE4_PROB_009:0, OBJ_CLS_TYPE5_009:0, OBJ_CLS_TYPE5_PROB_009:0, OBJ_CLS_TYPE6_009:0, OBJ_CLS_TYPE6_PROB_009:0, OBJ_DIMENSION_LENGTH_009:0, OBJ_DIMENSION_LENGTH_ERR_009:0, OBJ_DIMENSION_WIDTH_009:0, OBJ_DIMENSION_WIDTH_ERR_009:0, OBJ_EXISTENCE_PROB_009:0, OBJ_GROUP_ID_009:0, OBJ_ID_009:0, OBJ_MEASUREMENT_STATUS_009:0, OBJ_MH_CRC16_009:0, OBJ_MH_CYCLE_COUNTER_009:0, OBJ_MOVEMENT_STATUS_009:0, OBJ_POS_ERR_CRR_COEF_009:120, OBJ_POS_LAT_009:32700, OBJ_POS_LAT_ERR_009:0, OBJ_POS_LONG_009:32700, OBJ_POS_LONG_ERR_009:0, OBJ_RCS_009:64, OBJ_REF_PT_LAT_OFFSET_009:0, OBJ_REF_PT_LONG_OFFSET_009:0, OBJ_TIMESTAMP_OFFSET_009:127, OBJ_TRACK_MOTION_MODEL_009:0, OBJ_VEH_TRACK_FLAG_009:0, OBJ_VELOCITY_ERR_CRR_COEF_009:120, OBJ_VELOCITY_LAT_009:16300, OBJ_VELOCITY_LAT_ERR_009:0, OBJ_VELOCITY_LONG_009:16300, OBJ_VELOCITY_LONG_ERR_009:0, OBJ_YAW_ANGLE_009:2000, OBJ_YAW_ANGLE_ERR_009:0, OBJ_YAW_RATE_009:448, OBJ_YAW_RATE_ERR_009:0]}, provided-interface=Pi_SG_TrackerObject009
      Pp_SG_TrackerObject044: nonqueued-sender-com-spec{data-element=Vdp_SG_TrackerObject044, init-value=fields=[OBJ_ACCEL_ERR_CRR_COEF_044:120, OBJ_ACCELERATION_LAT_044:400, OBJ_ACCELERATION_LAT_ERR_044:0, OBJ_ACCELERATION_LONG_044:400, OBJ_ACCELERATION_LONG_ERR_044:0, OBJ_ALIVE_TIME_044:0, OBJ_CLS_TYPE1_044:0, OBJ_CLS_TYPE1_PROB_044:0, OBJ_CLS_TYPE2_044:0, OBJ_CLS_TYPE2_PROB_044:0, OBJ_CLS_TYPE3_044:0, OBJ_CLS_TYPE3_PROB_044:0, OBJ_CLS_TYPE4_044:0, OBJ_CLS_TYPE4_PROB_044:0, OBJ_CLS_TYPE5_044:0, OBJ_CLS_TYPE5_PROB_044:0, OBJ_CLS_TYPE6_044:0, OBJ_CLS_TYPE6_PROB_044:0, OBJ_DIMENSION_LENGTH_044:0, OBJ_DIMENSION_LENGTH_ERR_044:0, OBJ_DIMENSION_WIDTH_044:0, OBJ_DIMENSION_WIDTH_ERR_044:0, OBJ_EXISTENCE_PROB_044:0, OBJ_GROUP_ID_044:0, OBJ_ID_044:0, OBJ_MEASUREMENT_STATUS_044:0, OBJ_MH_CRC16_044:0, OBJ_MH_CYCLE_COUNTER_044:0, OBJ_MOVEMENT_STATUS_044:0, OBJ_POS_ERR_CRR_COEF_044:120, OBJ_POS_LAT_044:32700, OBJ_POS_LAT_ERR_044:0, OBJ_POS_LONG_044:32700, OBJ_POS_LONG_ERR_044:0, OBJ_RCS_044:64, OBJ_REF_PT_LAT_OFFSET_044:0, OBJ_REF_PT_LONG_OFFSET_044:0, OBJ_TIMESTAMP_OFFSET_044:127, OBJ_TRACK_MOTION_MODEL_044:0, OBJ_VEH_TRACK_FLAG_044:0, OBJ_VELOCITY_ERR_CRR_COEF_044:120, OBJ_VELOCITY_LAT_044:16300, OBJ_VELOCITY_LAT_ERR_044:0, OBJ_VELOCITY_LONG_044:16300, OBJ_VELOCITY_LONG_ERR_044:0, OBJ_YAW_ANGLE_044:2000, OBJ_YAW_ANGLE_ERR_044:0, OBJ_YAW_RATE_044:448, OBJ_YAW_RATE_ERR_044:0]}, provided-interface=Pi_SG_TrackerObject044
      Pp_SG_TrackerObject003: nonqueued-sender-com-spec{data-element=Vdp_SG_TrackerObject003, init-value=fields=[OBJ_ACCEL_ERR_CRR_COEF_003:120, OBJ_ACCELERATION_LAT_003:400, OBJ_ACCELERATION_LAT_ERR_003:0, OBJ_ACCELERATION_LONG_003:400, OBJ_ACCELERATION_LONG_ERR_003:0, OBJ_ALIVE_TIME_003:0, OBJ_CLS_TYPE1_003:0, OBJ_CLS_TYPE1_PROB_003:0, OBJ_CLS_TYPE2_003:0, OBJ_CLS_TYPE2_PROB_003:0, OBJ_CLS_TYPE3_003:0, OBJ_CLS_TYPE3_PROB_003:0, OBJ_CLS_TYPE4_003:0, OBJ_CLS_TYPE4_PROB_003:0, OBJ_CLS_TYPE5_003:0, OBJ_CLS_TYPE5_PROB_003:0, OBJ_CLS_TYPE6_003:0, OBJ_CLS_TYPE6_PROB_003:0, OBJ_DIMENSION_LENGTH_003:0, OBJ_DIMENSION_LENGTH_ERR_003:0, OBJ_DIMENSION_WIDTH_003:0, OBJ_DIMENSION_WIDTH_ERR_003:0, OBJ_EXISTENCE_PROB_003:0, OBJ_GROUP_ID_003:0, OBJ_ID_003:0, OBJ_MEASUREMENT_STATUS_003:0, OBJ_MH_CRC16_003:0, OBJ_MH_CYCLE_COUNTER_003:0, OBJ_MOVEMENT_STATUS_003:0, OBJ_POS_ERR_CRR_COEF_003:120, OBJ_POS_LAT_003:32700, OBJ_POS_LAT_ERR_003:0, OBJ_POS_LONG_003:32700, OBJ_POS_LONG_ERR_003:0, OBJ_RCS_003:64, OBJ_REF_PT_LAT_OFFSET_003:0, OBJ_REF_PT_LONG_OFFSET_003:0, OBJ_TIMESTAMP_OFFSET_003:127, OBJ_TRACK_MOTION_MODEL_003:0, OBJ_VEH_TRACK_FLAG_003:0, OBJ_VELOCITY_ERR_CRR_COEF_003:120, OBJ_VELOCITY_LAT_003:16300, OBJ_VELOCITY_LAT_ERR_003:0, OBJ_VELOCITY_LONG_003:16300, OBJ_VELOCITY_LONG_ERR_003:0, OBJ_YAW_ANGLE_003:2000, OBJ_YAW_ANGLE_ERR_003:0, OBJ_YAW_RATE_003:448, OBJ_YAW_RATE_ERR_003:0]}, provided-interface=Pi_SG_TrackerObject003
      Pp_SG_TrackerObject015: nonqueued-sender-com-spec{data-element=Vdp_SG_TrackerObject015, init-value=fields=[OBJ_ACCEL_ERR_CRR_COEF_015:120, OBJ_ACCELERATION_LAT_015:400, OBJ_ACCELERATION_LAT_ERR_015:0, OBJ_ACCELERATION_LONG_015:400, OBJ_ACCELERATION_LONG_ERR_015:0, OBJ_ALIVE_TIME_015:0, OBJ_CLS_TYPE1_015:0, OBJ_CLS_TYPE1_PROB_015:0, OBJ_CLS_TYPE2_015:0, OBJ_CLS_TYPE2_PROB_015:0, OBJ_CLS_TYPE3_015:0, OBJ_CLS_TYPE3_PROB_015:0, OBJ_CLS_TYPE4_015:0, OBJ_CLS_TYPE4_PROB_015:0, OBJ_CLS_TYPE5_015:0, OBJ_CLS_TYPE5_PROB_015:0, OBJ_CLS_TYPE6_015:0, OBJ_CLS_TYPE6_PROB_015:0, OBJ_DIMENSION_LENGTH_015:0, OBJ_DIMENSION_LENGTH_ERR_015:0, OBJ_DIMENSION_WIDTH_015:0, OBJ_DIMENSION_WIDTH_ERR_015:0, OBJ_EXISTENCE_PROB_015:0, OBJ_GROUP_ID_015:0, OBJ_ID_015:0, OBJ_MEASUREMENT_STATUS_015:0, OBJ_MH_CRC16_015:0, OBJ_MH_CYCLE_COUNTER_015:0, OBJ_MOVEMENT_STATUS_015:0, OBJ_POS_ERR_CRR_COEF_015:120, OBJ_POS_LAT_015:32700, OBJ_POS_LAT_ERR_015:0, OBJ_POS_LONG_015:32700, OBJ_POS_LONG_ERR_015:0, OBJ_RCS_015:64, OBJ_REF_PT_LAT_OFFSET_015:0, OBJ_REF_PT_LONG_OFFSET_015:0, OBJ_TIMESTAMP_OFFSET_015:127, OBJ_TRACK_MOTION_MODEL_015:0, OBJ_VEH_TRACK_FLAG_015:0, OBJ_VELOCITY_ERR_CRR_COEF_015:120, OBJ_VELOCITY_LAT_015:16300, OBJ_VELOCITY_LAT_ERR_015:0, OBJ_VELOCITY_LONG_015:16300, OBJ_VELOCITY_LONG_ERR_015:0, OBJ_YAW_ANGLE_015:2000, OBJ_YAW_ANGLE_ERR_015:0, OBJ_YAW_RATE_015:448, OBJ_YAW_RATE_ERR_015:0]}, provided-interface=Pi_SG_TrackerObject015
      Pp_SG_TrackerObject026: nonqueued-sender-com-spec{data-element=Vdp_SG_TrackerObject026, init-value=fields=[OBJ_ACCEL_ERR_CRR_COEF_026:120, OBJ_ACCELERATION_LAT_026:400, OBJ_ACCELERATION_LAT_ERR_026:0, OBJ_ACCELERATION_LONG_026:400, OBJ_ACCELERATION_LONG_ERR_026:0, OBJ_ALIVE_TIME_026:0, OBJ_CLS_TYPE1_026:0, OBJ_CLS_TYPE1_PROB_026:0, OBJ_CLS_TYPE2_026:0, OBJ_CLS_TYPE2_PROB_026:0, OBJ_CLS_TYPE3_026:0, OBJ_CLS_TYPE3_PROB_026:0, OBJ_CLS_TYPE4_026:0, OBJ_CLS_TYPE4_PROB_026:0, OBJ_CLS_TYPE5_026:0, OBJ_CLS_TYPE5_PROB_026:0, OBJ_CLS_TYPE6_026:0, OBJ_CLS_TYPE6_PROB_026:0, OBJ_DIMENSION_LENGTH_026:0, OBJ_DIMENSION_LENGTH_ERR_026:0, OBJ_DIMENSION_WIDTH_026:0, OBJ_DIMENSION_WIDTH_ERR_026:0, OBJ_EXISTENCE_PROB_026:0, OBJ_GROUP_ID_026:0, OBJ_ID_026:0, OBJ_MEASUREMENT_STATUS_026:0, OBJ_MH_CRC16_026:0, OBJ_MH_CYCLE_COUNTER_026:0, OBJ_MOVEMENT_STATUS_026:0, OBJ_POS_ERR_CRR_COEF_026:120, OBJ_POS_LAT_026:32700, OBJ_POS_LAT_ERR_026:0, OBJ_POS_LONG_026:32700, OBJ_POS_LONG_ERR_026:0, OBJ_RCS_026:64, OBJ_REF_PT_LAT_OFFSET_026:0, OBJ_REF_PT_LONG_OFFSET_026:0, OBJ_TIMESTAMP_OFFSET_026:127, OBJ_TRACK_MOTION_MODEL_026:0, OBJ_VEH_TRACK_FLAG_026:0, OBJ_VELOCITY_ERR_CRR_COEF_026:120, OBJ_VELOCITY_LAT_026:16300, OBJ_VELOCITY_LAT_ERR_026:0, OBJ_VELOCITY_LONG_026:16300, OBJ_VELOCITY_LONG_ERR_026:0, OBJ_YAW_ANGLE_026:2000, OBJ_YAW_ANGLE_ERR_026:0, OBJ_YAW_RATE_026:448, OBJ_YAW_RATE_ERR_026:0]}, provided-interface=Pi_SG_TrackerObject026
      Pp_SG_TrackerObject004: nonqueued-sender-com-spec{data-element=Vdp_SG_TrackerObject004, init-value=fields=[OBJ_ACCEL_ERR_CRR_COEF_004:120, OBJ_ACCELERATION_LAT_004:400, OBJ_ACCELERATION_LAT_ERR_004:0, OBJ_ACCELERATION_LONG_004:400, OBJ_ACCELERATION_LONG_ERR_004:0, OBJ_ALIVE_TIME_004:0, OBJ_CLS_TYPE1_004:0, OBJ_CLS_TYPE1_PROB_004:0, OBJ_CLS_TYPE2_004:0, OBJ_CLS_TYPE2_PROB_004:0, OBJ_CLS_TYPE3_004:0, OBJ_CLS_TYPE3_PROB_004:0, OBJ_CLS_TYPE4_004:0, OBJ_CLS_TYPE4_PROB_004:0, OBJ_CLS_TYPE5_004:0, OBJ_CLS_TYPE5_PROB_004:0, OBJ_CLS_TYPE6_004:0, OBJ_CLS_TYPE6_PROB_004:0, OBJ_DIMENSION_LENGTH_004:0, OBJ_DIMENSION_LENGTH_ERR_004:0, OBJ_DIMENSION_WIDTH_004:0, OBJ_DIMENSION_WIDTH_ERR_004:0, OBJ_EXISTENCE_PROB_004:0, OBJ_GROUP_ID_004:0, OBJ_ID_004:0, OBJ_MEASUREMENT_STATUS_004:0, OBJ_MH_CRC16_004:0, OBJ_MH_CYCLE_COUNTER_004:0, OBJ_MOVEMENT_STATUS_004:0, OBJ_POS_ERR_CRR_COEF_004:120, OBJ_POS_LAT_004:32700, OBJ_POS_LAT_ERR_004:0, OBJ_POS_LONG_004:32700, OBJ_POS_LONG_ERR_004:0, OBJ_RCS_004:64, OBJ_REF_PT_LAT_OFFSET_004:0, OBJ_REF_PT_LONG_OFFSET_004:0, OBJ_TIMESTAMP_OFFSET_004:127, OBJ_TRACK_MOTION_MODEL_004:0, OBJ_VEH_TRACK_FLAG_004:0, OBJ_VELOCITY_ERR_CRR_COEF_004:120, OBJ_VELOCITY_LAT_004:16300, OBJ_VELOCITY_LAT_ERR_004:0, OBJ_VELOCITY_LONG_004:16300, OBJ_VELOCITY_LONG_ERR_004:0, OBJ_YAW_ANGLE_004:2000, OBJ_YAW_ANGLE_ERR_004:0, OBJ_YAW_RATE_004:448, OBJ_YAW_RATE_ERR_004:0]}, provided-interface=Pi_SG_TrackerObject004
      Pp_SG_TrackerObject018: nonqueued-sender-com-spec{data-element=Vdp_SG_TrackerObject018, init-value=fields=[OBJ_ACCEL_ERR_CRR_COEF_018:120, OBJ_ACCELERATION_LAT_018:400, OBJ_ACCELERATION_LAT_ERR_018:0, OBJ_ACCELERATION_LONG_018:400, OBJ_ACCELERATION_LONG_ERR_018:0, OBJ_ALIVE_TIME_018:0, OBJ_CLS_TYPE1_018:0, OBJ_CLS_TYPE1_PROB_018:0, OBJ_CLS_TYPE2_018:0, OBJ_CLS_TYPE2_PROB_018:0, OBJ_CLS_TYPE3_018:0, OBJ_CLS_TYPE3_PROB_018:0, OBJ_CLS_TYPE4_018:0, OBJ_CLS_TYPE4_PROB_018:0, OBJ_CLS_TYPE5_018:0, OBJ_CLS_TYPE5_PROB_018:0, OBJ_CLS_TYPE6_018:0, OBJ_CLS_TYPE6_PROB_018:0, OBJ_DIMENSION_LENGTH_018:0, OBJ_DIMENSION_LENGTH_ERR_018:0, OBJ_DIMENSION_WIDTH_018:0, OBJ_DIMENSION_WIDTH_ERR_018:0, OBJ_EXISTENCE_PROB_018:0, OBJ_GROUP_ID_018:0, OBJ_ID_018:0, OBJ_MEASUREMENT_STATUS_018:0, OBJ_MH_CRC16_018:0, OBJ_MH_CYCLE_COUNTER_018:0, OBJ_MOVEMENT_STATUS_018:0, OBJ_POS_ERR_CRR_COEF_018:120, OBJ_POS_LAT_018:32700, OBJ_POS_LAT_ERR_018:0, OBJ_POS_LONG_018:32700, OBJ_POS_LONG_ERR_018:0, OBJ_RCS_018:64, OBJ_REF_PT_LAT_OFFSET_018:0, OBJ_REF_PT_LONG_OFFSET_018:0, OBJ_TIMESTAMP_OFFSET_018:127, OBJ_TRACK_MOTION_MODEL_018:0, OBJ_VEH_TRACK_FLAG_018:0, OBJ_VELOCITY_ERR_CRR_COEF_018:120, OBJ_VELOCITY_LAT_018:16300, OBJ_VELOCITY_LAT_ERR_018:0, OBJ_VELOCITY_LONG_018:16300, OBJ_VELOCITY_LONG_ERR_018:0, OBJ_YAW_ANGLE_018:2000, OBJ_YAW_ANGLE_ERR_018:0, OBJ_YAW_RATE_018:448, OBJ_YAW_RATE_ERR_018:0]}, provided-interface=Pi_SG_TrackerObject018
      Pp_SG_TrackerObject006: nonqueued-sender-com-spec{data-element=Vdp_SG_TrackerObject006, init-value=fields=[OBJ_ACCEL_ERR_CRR_COEF_006:120, OBJ_ACCELERATION_LAT_006:400, OBJ_ACCELERATION_LAT_ERR_006:0, OBJ_ACCELERATION_LONG_006:400, OBJ_ACCELERATION_LONG_ERR_006:0, OBJ_ALIVE_TIME_006:0, OBJ_CLS_TYPE1_006:0, OBJ_CLS_TYPE1_PROB_006:0, OBJ_CLS_TYPE2_006:0, OBJ_CLS_TYPE2_PROB_006:0, OBJ_CLS_TYPE3_006:0, OBJ_CLS_TYPE3_PROB_006:0, OBJ_CLS_TYPE4_006:0, OBJ_CLS_TYPE4_PROB_006:0, OBJ_CLS_TYPE5_006:0, OBJ_CLS_TYPE5_PROB_006:0, OBJ_CLS_TYPE6_006:0, OBJ_CLS_TYPE6_PROB_006:0, OBJ_DIMENSION_LENGTH_006:0, OBJ_DIMENSION_LENGTH_ERR_006:0, OBJ_DIMENSION_WIDTH_006:0, OBJ_DIMENSION_WIDTH_ERR_006:0, OBJ_EXISTENCE_PROB_006:0, OBJ_GROUP_ID_006:0, OBJ_ID_006:0, OBJ_MEASUREMENT_STATUS_006:0, OBJ_MH_CRC16_006:0, OBJ_MH_CYCLE_COUNTER_006:0, OBJ_MOVEMENT_STATUS_006:0, OBJ_POS_ERR_CRR_COEF_006:120, OBJ_POS_LAT_006:32700, OBJ_POS_LAT_ERR_006:0, OBJ_POS_LONG_006:32700, OBJ_POS_LONG_ERR_006:0, OBJ_RCS_006:64, OBJ_REF_PT_LAT_OFFSET_006:0, OBJ_REF_PT_LONG_OFFSET_006:0, OBJ_TIMESTAMP_OFFSET_006:127, OBJ_TRACK_MOTION_MODEL_006:0, OBJ_VEH_TRACK_FLAG_006:0, OBJ_VELOCITY_ERR_CRR_COEF_006:120, OBJ_VELOCITY_LAT_006:16300, OBJ_VELOCITY_LAT_ERR_006:0, OBJ_VELOCITY_LONG_006:16300, OBJ_VELOCITY_LONG_ERR_006:0, OBJ_YAW_ANGLE_006:2000, OBJ_YAW_ANGLE_ERR_006:0, OBJ_YAW_RATE_006:448, OBJ_YAW_RATE_ERR_006:0]}, provided-interface=Pi_SG_TrackerObject006
      Pp_SG_TrackerObject043: nonqueued-sender-com-spec{data-element=Vdp_SG_TrackerObject043, init-value=fields=[OBJ_ACCEL_ERR_CRR_COEF_043:120, OBJ_ACCELERATION_LAT_043:400, OBJ_ACCELERATION_LAT_ERR_043:0, OBJ_ACCELERATION_LONG_043:400, OBJ_ACCELERATION_LONG_ERR_043:0, OBJ_ALIVE_TIME_043:0, OBJ_CLS_TYPE1_043:0, OBJ_CLS_TYPE1_PROB_043:0, OBJ_CLS_TYPE2_043:0, OBJ_CLS_TYPE2_PROB_043:0, OBJ_CLS_TYPE3_043:0, OBJ_CLS_TYPE3_PROB_043:0, OBJ_CLS_TYPE4_043:0, OBJ_CLS_TYPE4_PROB_043:0, OBJ_CLS_TYPE5_043:0, OBJ_CLS_TYPE5_PROB_043:0, OBJ_CLS_TYPE6_043:0, OBJ_CLS_TYPE6_PROB_043:0, OBJ_DIMENSION_LENGTH_043:0, OBJ_DIMENSION_LENGTH_ERR_043:0, OBJ_DIMENSION_WIDTH_043:0, OBJ_DIMENSION_WIDTH_ERR_043:0, OBJ_EXISTENCE_PROB_043:0, OBJ_GROUP_ID_043:0, OBJ_ID_043:0, OBJ_MEASUREMENT_STATUS_043:0, OBJ_MH_CRC16_043:0, OBJ_MH_CYCLE_COUNTER_043:0, OBJ_MOVEMENT_STATUS_043:0, OBJ_POS_ERR_CRR_COEF_043:120, OBJ_POS_LAT_043:32700, OBJ_POS_LAT_ERR_043:0, OBJ_POS_LONG_043:32700, OBJ_POS_LONG_ERR_043:0, OBJ_RCS_043:64, OBJ_REF_PT_LAT_OFFSET_043:0, OBJ_REF_PT_LONG_OFFSET_043:0, OBJ_TIMESTAMP_OFFSET_043:127, OBJ_TRACK_MOTION_MODEL_043:0, OBJ_VEH_TRACK_FLAG_043:0, OBJ_VELOCITY_ERR_CRR_COEF_043:120, OBJ_VELOCITY_LAT_043:16300, OBJ_VELOCITY_LAT_ERR_043:0, OBJ_VELOCITY_LONG_043:16300, OBJ_VELOCITY_LONG_ERR_043:0, OBJ_YAW_ANGLE_043:2000, OBJ_YAW_ANGLE_ERR_043:0, OBJ_YAW_RATE_043:448, OBJ_YAW_RATE_ERR_043:0]}, provided-interface=Pi_SG_TrackerObject043
      Pp_SG_TrackerObject058: nonqueued-sender-com-spec{data-element=Vdp_SG_TrackerObject058, init-value=fields=[OBJ_ACCEL_ERR_CRR_COEF_058:120, OBJ_ACCELERATION_LAT_058:400, OBJ_ACCELERATION_LAT_ERR_058:0, OBJ_ACCELERATION_LONG_058:400, OBJ_ACCELERATION_LONG_ERR_058:0, OBJ_ALIVE_TIME_058:0, OBJ_CLS_TYPE1_058:0, OBJ_CLS_TYPE1_PROB_058:0, OBJ_CLS_TYPE2_058:0, OBJ_CLS_TYPE2_PROB_058:0, OBJ_CLS_TYPE3_058:0, OBJ_CLS_TYPE3_PROB_058:0, OBJ_CLS_TYPE4_058:0, OBJ_CLS_TYPE4_PROB_058:0, OBJ_CLS_TYPE5_058:0, OBJ_CLS_TYPE5_PROB_058:0, OBJ_CLS_TYPE6_058:0, OBJ_CLS_TYPE6_PROB_058:0, OBJ_DIMENSION_LENGTH_058:0, OBJ_DIMENSION_LENGTH_ERR_058:0, OBJ_DIMENSION_WIDTH_058:0, OBJ_DIMENSION_WIDTH_ERR_058:0, OBJ_EXISTENCE_PROB_058:0, OBJ_GROUP_ID_058:0, OBJ_ID_058:0, OBJ_MEASUREMENT_STATUS_058:0, OBJ_MH_CRC16_058:0, OBJ_MH_CYCLE_COUNTER_058:0, OBJ_MOVEMENT_STATUS_058:0, OBJ_POS_ERR_CRR_COEF_058:120, OBJ_POS_LAT_058:32700, OBJ_POS_LAT_ERR_058:0, OBJ_POS_LONG_058:32700, OBJ_POS_LONG_ERR_058:0, OBJ_RCS_058:64, OBJ_REF_PT_LAT_OFFSET_058:0, OBJ_REF_PT_LONG_OFFSET_058:0, OBJ_TIMESTAMP_OFFSET_058:127, OBJ_TRACK_MOTION_MODEL_058:0, OBJ_VEH_TRACK_FLAG_058:0, OBJ_VELOCITY_ERR_CRR_COEF_058:120, OBJ_VELOCITY_LAT_058:16300, OBJ_VELOCITY_LAT_ERR_058:0, OBJ_VELOCITY_LONG_058:16300, OBJ_VELOCITY_LONG_ERR_058:0, OBJ_YAW_ANGLE_058:2000, OBJ_YAW_ANGLE_ERR_058:0, OBJ_YAW_RATE_058:448, OBJ_YAW_RATE_ERR_058:0]}, provided-interface=Pi_SG_TrackerObject058
      Pp_SG_TrackerObject032: nonqueued-sender-com-spec{data-element=Vdp_SG_TrackerObject032, init-value=fields=[OBJ_ACCEL_ERR_CRR_COEF_032:120, OBJ_ACCELERATION_LAT_032:400, OBJ_ACCELERATION_LAT_ERR_032:0, OBJ_ACCELERATION_LONG_032:400, OBJ_ACCELERATION_LONG_ERR_032:0, OBJ_ALIVE_TIME_032:0, OBJ_CLS_TYPE1_032:0, OBJ_CLS_TYPE1_PROB_032:0, OBJ_CLS_TYPE2_032:0, OBJ_CLS_TYPE2_PROB_032:0, OBJ_CLS_TYPE3_032:0, OBJ_CLS_TYPE3_PROB_032:0, OBJ_CLS_TYPE4_032:0, OBJ_CLS_TYPE4_PROB_032:0, OBJ_CLS_TYPE5_032:0, OBJ_CLS_TYPE5_PROB_032:0, OBJ_CLS_TYPE6_032:0, OBJ_CLS_TYPE6_PROB_032:0, OBJ_DIMENSION_LENGTH_032:0, OBJ_DIMENSION_LENGTH_ERR_032:0, OBJ_DIMENSION_WIDTH_032:0, OBJ_DIMENSION_WIDTH_ERR_032:0, OBJ_EXISTENCE_PROB_032:0, OBJ_GROUP_ID_032:0, OBJ_ID_032:0, OBJ_MEASUREMENT_STATUS_032:0, OBJ_MH_CRC16_032:0, OBJ_MH_CYCLE_COUNTER_032:0, OBJ_MOVEMENT_STATUS_032:0, OBJ_POS_ERR_CRR_COEF_032:120, OBJ_POS_LAT_032:32700, OBJ_POS_LAT_ERR_032:0, OBJ_POS_LONG_032:32700, OBJ_POS_LONG_ERR_032:0, OBJ_RCS_032:64, OBJ_REF_PT_LAT_OFFSET_032:0, OBJ_REF_PT_LONG_OFFSET_032:0, OBJ_TIMESTAMP_OFFSET_032:127, OBJ_TRACK_MOTION_MODEL_032:0, OBJ_VEH_TRACK_FLAG_032:0, OBJ_VELOCITY_ERR_CRR_COEF_032:120, OBJ_VELOCITY_LAT_032:16300, OBJ_VELOCITY_LAT_ERR_032:0, OBJ_VELOCITY_LONG_032:16300, OBJ_VELOCITY_LONG_ERR_032:0, OBJ_YAW_ANGLE_032:2000, OBJ_YAW_ANGLE_ERR_032:0, OBJ_YAW_RATE_032:448, OBJ_YAW_RATE_ERR_032:0]}, provided-interface=Pi_SG_TrackerObject032
      Pp_SG_TrackerObject017: nonqueued-sender-com-spec{data-element=Vdp_SG_TrackerObject017, init-value=fields=[OBJ_ACCEL_ERR_CRR_COEF_017:120, OBJ_ACCELERATION_LAT_017:400, OBJ_ACCELERATION_LAT_ERR_017:0, OBJ_ACCELERATION_LONG_017:400, OBJ_ACCELERATION_LONG_ERR_017:0, OBJ_ALIVE_TIME_017:0, OBJ_CLS_TYPE1_017:0, OBJ_CLS_TYPE1_PROB_017:0, OBJ_CLS_TYPE2_017:0, OBJ_CLS_TYPE2_PROB_017:0, OBJ_CLS_TYPE3_017:0, OBJ_CLS_TYPE3_PROB_017:0, OBJ_CLS_TYPE4_017:0, OBJ_CLS_TYPE4_PROB_017:0, OBJ_CLS_TYPE5_017:0, OBJ_CLS_TYPE5_PROB_017:0, OBJ_CLS_TYPE6_017:0, OBJ_CLS_TYPE6_PROB_017:0, OBJ_DIMENSION_LENGTH_017:0, OBJ_DIMENSION_LENGTH_ERR_017:0, OBJ_DIMENSION_WIDTH_017:0, OBJ_DIMENSION_WIDTH_ERR_017:0, OBJ_EXISTENCE_PROB_017:0, OBJ_GROUP_ID_017:0, OBJ_ID_017:0, OBJ_MEASUREMENT_STATUS_017:0, OBJ_MH_CRC16_017:0, OBJ_MH_CYCLE_COUNTER_017:0, OBJ_MOVEMENT_STATUS_017:0, OBJ_POS_ERR_CRR_COEF_017:120, OBJ_POS_LAT_017:32700, OBJ_POS_LAT_ERR_017:0, OBJ_POS_LONG_017:32700, OBJ_POS_LONG_ERR_017:0, OBJ_RCS_017:64, OBJ_REF_PT_LAT_OFFSET_017:0, OBJ_REF_PT_LONG_OFFSET_017:0, OBJ_TIMESTAMP_OFFSET_017:127, OBJ_TRACK_MOTION_MODEL_017:0, OBJ_VEH_TRACK_FLAG_017:0, OBJ_VELOCITY_ERR_CRR_COEF_017:120, OBJ_VELOCITY_LAT_017:16300, OBJ_VELOCITY_LAT_ERR_017:0, OBJ_VELOCITY_LONG_017:16300, OBJ_VELOCITY_LONG_ERR_017:0, OBJ_YAW_ANGLE_017:2000, OBJ_YAW_ANGLE_ERR_017:0, OBJ_YAW_RATE_017:448, OBJ_YAW_RATE_ERR_017:0]}, provided-interface=Pi_SG_TrackerObject017
      Pp_RDR_NM_PNC_Reserved1: nonqueued-sender-com-spec{data-element=Vdp_RDR_NM_PNC_Reserved1, init-value=0}, provided-interface=Pi_RDR_NM_PNC_Reserved1_1
      Pp_SG_TrackerObject048: nonqueued-sender-com-spec{data-element=Vdp_SG_TrackerObject048, init-value=fields=[OBJ_ACCEL_ERR_CRR_COEF_048:120, OBJ_ACCELERATION_LAT_048:400, OBJ_ACCELERATION_LAT_ERR_048:0, OBJ_ACCELERATION_LONG_048:400, OBJ_ACCELERATION_LONG_ERR_048:0, OBJ_ALIVE_TIME_048:0, OBJ_CLS_TYPE1_048:0, OBJ_CLS_TYPE1_PROB_048:0, OBJ_CLS_TYPE2_048:0, OBJ_CLS_TYPE2_PROB_048:0, OBJ_CLS_TYPE3_048:0, OBJ_CLS_TYPE3_PROB_048:0, OBJ_CLS_TYPE4_048:0, OBJ_CLS_TYPE4_PROB_048:0, OBJ_CLS_TYPE5_048:0, OBJ_CLS_TYPE5_PROB_048:0, OBJ_CLS_TYPE6_048:0, OBJ_CLS_TYPE6_PROB_048:0, OBJ_DIMENSION_LENGTH_048:0, OBJ_DIMENSION_LENGTH_ERR_048:0, OBJ_DIMENSION_WIDTH_048:0, OBJ_DIMENSION_WIDTH_ERR_048:0, OBJ_EXISTENCE_PROB_048:0, OBJ_GROUP_ID_048:0, OBJ_ID_048:0, OBJ_MEASUREMENT_STATUS_048:0, OBJ_MH_CRC16_048:0, OBJ_MH_CYCLE_COUNTER_048:0, OBJ_MOVEMENT_STATUS_048:0, OBJ_POS_ERR_CRR_COEF_048:120, OBJ_POS_LAT_048:32700, OBJ_POS_LAT_ERR_048:0, OBJ_POS_LONG_048:32700, OBJ_POS_LONG_ERR_048:0, OBJ_RCS_048:64, OBJ_REF_PT_LAT_OFFSET_048:0, OBJ_REF_PT_LONG_OFFSET_048:0, OBJ_TIMESTAMP_OFFSET_048:127, OBJ_TRACK_MOTION_MODEL_048:0, OBJ_VEH_TRACK_FLAG_048:0, OBJ_VELOCITY_ERR_CRR_COEF_048:120, OBJ_VELOCITY_LAT_048:16300, OBJ_VELOCITY_LAT_ERR_048:0, OBJ_VELOCITY_LONG_048:16300, OBJ_VELOCITY_LONG_ERR_048:0, OBJ_YAW_ANGLE_048:2000, OBJ_YAW_ANGLE_ERR_048:0, OBJ_YAW_RATE_048:448, OBJ_YAW_RATE_ERR_048:0]}, provided-interface=Pi_SG_TrackerObject048
      Pp_SG_Detections_365_368_AL: nonqueued-sender-com-spec{data-element=Vdp_SG_Detections_365_368_AL, init-value=fields=[DET_AZIMUTH_365:0, DET_AZIMUTH_366:0, DET_AZIMUTH_367:0, DET_AZIMUTH_368:0, DET_AZIMUTH_ERR_365:0, DET_AZIMUTH_ERR_366:0, DET_AZIMUTH_ERR_367:0, DET_AZIMUTH_ERR_368:0, DET_BELOW_RAIN_THOLD_365:0, DET_BELOW_RAIN_THOLD_366:0, DET_BELOW_RAIN_THOLD_367:0, DET_BELOW_RAIN_THOLD_368:0, DET_BI_STATIC_FLAG_365:0, DET_BI_STATIC_FLAG_366:0, DET_BI_STATIC_FLAG_367:0, DET_BI_STATIC_FLAG_368:0, DET_CONFD_AZIMUTH_365:0, DET_CONFD_AZIMUTH_366:0, DET_CONFD_AZIMUTH_367:0, DET_CONFD_AZIMUTH_368:0, DET_CONFD_ELEVATION_365:0, DET_CONFD_ELEVATION_366:0, DET_CONFD_ELEVATION_367:0, DET_CONFD_ELEVATION_368:0, DET_ELEVATION_365:0, DET_ELEVATION_366:0, DET_ELEVATION_367:0, DET_ELEVATION_368:0, DET_ELEVATION_ERR_365:0, DET_ELEVATION_ERR_366:0, DET_ELEVATION_ERR_367:0, DET_ELEVATION_ERR_368:0, DET_EXISTENCE_PROB_365:0, DET_EXISTENCE_PROB_366:0, DET_EXISTENCE_PROB_367:0, DET_EXISTENCE_PROB_368:0, DET_HVC_FLAG_365:0, DET_HVC_FLAG_366:0, DET_HVC_FLAG_367:0, DET_HVC_FLAG_368:0, DET_IDM_365:0, DET_IDM_366:0, DET_IDM_367:0, DET_IDM_368:0, DET_MH_CRC16_365_368:0, DET_MH_CYCLE_COUNTER_365_368:0, DET_MH_SCAN_INDEX_4LSB_365_368:0, DET_MTD_365:0, DET_MTD_366:0, DET_MTD_367:0, DET_MTD_368:0, DET_PROB_1STAZHYPO_365:0, DET_PROB_1STAZHYPO_366:0, DET_PROB_1STAZHYPO_367:0, DET_PROB_1STAZHYPO_368:0, DET_RANGE_365:0, DET_RANGE_366:0, DET_RANGE_367:0, DET_RANGE_368:0, DET_RANGE_ERR_365:0, DET_RANGE_ERR_366:0, DET_RANGE_ERR_367:0, DET_RANGE_ERR_368:0, DET_RANGE_VELOCITY_365:16384, DET_RANGE_VELOCITY_366:16384, DET_RANGE_VELOCITY_367:16384, DET_RANGE_VELOCITY_368:16384, DET_RANGE_VELOCITY_ERR_365:0, DET_RANGE_VELOCITY_ERR_366:0, DET_RANGE_VELOCITY_ERR_367:0, DET_RANGE_VELOCITY_ERR_368:0, DET_RCS_365:128, DET_RCS_366:128, DET_RCS_367:128, DET_RCS_368:128, DET_SNR_365:0, DET_SNR_366:0, DET_SNR_367:0, DET_SNR_368:0, DET_SUPER_RES_TARGET_365:0, DET_SUPER_RES_TARGET_366:0, DET_SUPER_RES_TARGET_367:0, DET_SUPER_RES_TARGET_368:0]}, provided-interface=Pi_SG_Detections_365_368_AL
      Pp_SG_Detections_285_288_AL: nonqueued-sender-com-spec{data-element=Vdp_SG_Detections_285_288_AL, init-value=fields=[DET_AZIMUTH_285:0, DET_AZIMUTH_286:0, DET_AZIMUTH_287:0, DET_AZIMUTH_288:0, DET_AZIMUTH_ERR_285:0, DET_AZIMUTH_ERR_286:0, DET_AZIMUTH_ERR_287:0, DET_AZIMUTH_ERR_288:0, DET_BELOW_RAIN_THOLD_285:0, DET_BELOW_RAIN_THOLD_286:0, DET_BELOW_RAIN_THOLD_287:0, DET_BELOW_RAIN_THOLD_288:0, DET_BI_STATIC_FLAG_285:0, DET_BI_STATIC_FLAG_286:0, DET_BI_STATIC_FLAG_287:0, DET_BI_STATIC_FLAG_288:0, DET_CONFD_AZIMUTH_285:0, DET_CONFD_AZIMUTH_286:0, DET_CONFD_AZIMUTH_287:0, DET_CONFD_AZIMUTH_288:0, DET_CONFD_ELEVATION_285:0, DET_CONFD_ELEVATION_286:0, DET_CONFD_ELEVATION_287:0, DET_CONFD_ELEVATION_288:0, DET_ELEVATION_285:0, DET_ELEVATION_286:0, DET_ELEVATION_287:0, DET_ELEVATION_288:0, DET_ELEVATION_ERR_285:0, DET_ELEVATION_ERR_286:0, DET_ELEVATION_ERR_287:0, DET_ELEVATION_ERR_288:0, DET_EXISTENCE_PROB_285:0, DET_EXISTENCE_PROB_286:0, DET_EXISTENCE_PROB_287:0, DET_EXISTENCE_PROB_288:0, DET_HVC_FLAG_285:0, DET_HVC_FLAG_286:0, DET_HVC_FLAG_287:0, DET_HVC_FLAG_288:0, DET_IDM_285:0, DET_IDM_286:0, DET_IDM_287:0, DET_IDM_288:0, DET_MH_CRC16_285_288:0, DET_MH_CYCLE_COUNTER_285_288:0, DET_MH_SCAN_INDEX_4LSB_285_288:0, DET_MTD_285:0, DET_MTD_286:0, DET_MTD_287:0, DET_MTD_288:0, DET_PROB_1STAZHYPO_285:0, DET_PROB_1STAZHYPO_286:0, DET_PROB_1STAZHYPO_287:0, DET_PROB_1STAZHYPO_288:0, DET_RANGE_285:0, DET_RANGE_286:0, DET_RANGE_287:0, DET_RANGE_288:0, DET_RANGE_ERR_285:0, DET_RANGE_ERR_286:0, DET_RANGE_ERR_287:0, DET_RANGE_ERR_288:0, DET_RANGE_VELOCITY_285:16384, DET_RANGE_VELOCITY_286:16384, DET_RANGE_VELOCITY_287:16384, DET_RANGE_VELOCITY_288:16384, DET_RANGE_VELOCITY_ERR_285:0, DET_RANGE_VELOCITY_ERR_286:0, DET_RANGE_VELOCITY_ERR_287:0, DET_RANGE_VELOCITY_ERR_288:0, DET_RCS_285:128, DET_RCS_286:128, DET_RCS_287:128, DET_RCS_288:128, DET_SNR_285:0, DET_SNR_286:0, DET_SNR_287:0, DET_SNR_288:0, DET_SUPER_RES_TARGET_285:0, DET_SUPER_RES_TARGET_286:0, DET_SUPER_RES_TARGET_287:0, DET_SUPER_RES_TARGET_288:0]}, provided-interface=Pi_SG_Detections_285_288_AL
      Pp_SG_Detections_341_344_AL: nonqueued-sender-com-spec{data-element=Vdp_SG_Detections_341_344_AL, init-value=fields=[DET_AZIMUTH_341:0, DET_AZIMUTH_342:0, DET_AZIMUTH_343:0, DET_AZIMUTH_344:0, DET_AZIMUTH_ERR_341:0, DET_AZIMUTH_ERR_342:0, DET_AZIMUTH_ERR_343:0, DET_AZIMUTH_ERR_344:0, DET_BELOW_RAIN_THOLD_341:0, DET_BELOW_RAIN_THOLD_342:0, DET_BELOW_RAIN_THOLD_343:0, DET_BELOW_RAIN_THOLD_344:0, DET_BI_STATIC_FLAG_341:0, DET_BI_STATIC_FLAG_342:0, DET_BI_STATIC_FLAG_343:0, DET_BI_STATIC_FLAG_344:0, DET_CONFD_AZIMUTH_341:0, DET_CONFD_AZIMUTH_342:0, DET_CONFD_AZIMUTH_343:0, DET_CONFD_AZIMUTH_344:0, DET_CONFD_ELEVATION_341:0, DET_CONFD_ELEVATION_342:0, DET_CONFD_ELEVATION_343:0, DET_CONFD_ELEVATION_344:0, DET_ELEVATION_341:0, DET_ELEVATION_342:0, DET_ELEVATION_343:0, DET_ELEVATION_344:0, DET_ELEVATION_ERR_341:0, DET_ELEVATION_ERR_342:0, DET_ELEVATION_ERR_343:0, DET_ELEVATION_ERR_344:0, DET_EXISTENCE_PROB_341:0, DET_EXISTENCE_PROB_342:0, DET_EXISTENCE_PROB_343:0, DET_EXISTENCE_PROB_344:0, DET_HVC_FLAG_341:0, DET_HVC_FLAG_342:0, DET_HVC_FLAG_343:0, DET_HVC_FLAG_344:0, DET_IDM_341:0, DET_IDM_342:0, DET_IDM_343:0, DET_IDM_344:0, DET_MH_CRC16_341_344:0, DET_MH_CYCLE_COUNTER_341_344:0, DET_MH_SCAN_INDEX_4LSB_341_344:0, DET_MTD_341:0, DET_MTD_342:0, DET_MTD_343:0, DET_MTD_344:0, DET_PROB_1STAZHYPO_341:0, DET_PROB_1STAZHYPO_342:0, DET_PROB_1STAZHYPO_343:0, DET_PROB_1STAZHYPO_344:0, DET_RANGE_341:0, DET_RANGE_342:0, DET_RANGE_343:0, DET_RANGE_344:0, DET_RANGE_ERR_341:0, DET_RANGE_ERR_342:0, DET_RANGE_ERR_343:0, DET_RANGE_ERR_344:0, DET_RANGE_VELOCITY_341:16384, DET_RANGE_VELOCITY_342:16384, DET_RANGE_VELOCITY_343:16384, DET_RANGE_VELOCITY_344:16384, DET_RANGE_VELOCITY_ERR_341:0, DET_RANGE_VELOCITY_ERR_342:0, DET_RANGE_VELOCITY_ERR_343:0, DET_RANGE_VELOCITY_ERR_344:0, DET_RCS_341:128, DET_RCS_342:128, DET_RCS_343:128, DET_RCS_344:128, DET_SNR_341:0, DET_SNR_342:0, DET_SNR_343:0, DET_SNR_344:0, DET_SUPER_RES_TARGET_341:0, DET_SUPER_RES_TARGET_342:0, DET_SUPER_RES_TARGET_343:0, DET_SUPER_RES_TARGET_344:0]}, provided-interface=Pi_SG_Detections_341_344_AL
      Pp_SG_Detections_277_280_AL: nonqueued-sender-com-spec{data-element=Vdp_SG_Detections_277_280_AL, init-value=fields=[DET_AZIMUTH_277:0, DET_AZIMUTH_278:0, DET_AZIMUTH_279:0, DET_AZIMUTH_280:0, DET_AZIMUTH_ERR_277:0, DET_AZIMUTH_ERR_278:0, DET_AZIMUTH_ERR_279:0, DET_AZIMUTH_ERR_280:0, DET_BELOW_RAIN_THOLD_277:0, DET_BELOW_RAIN_THOLD_278:0, DET_BELOW_RAIN_THOLD_279:0, DET_BELOW_RAIN_THOLD_280:0, DET_BI_STATIC_FLAG_277:0, DET_BI_STATIC_FLAG_278:0, DET_BI_STATIC_FLAG_279:0, DET_BI_STATIC_FLAG_280:0, DET_CONFD_AZIMUTH_277:0, DET_CONFD_AZIMUTH_278:0, DET_CONFD_AZIMUTH_279:0, DET_CONFD_AZIMUTH_280:0, DET_CONFD_ELEVATION_277:0, DET_CONFD_ELEVATION_278:0, DET_CONFD_ELEVATION_279:0, DET_CONFD_ELEVATION_280:0, DET_ELEVATION_277:0, DET_ELEVATION_278:0, DET_ELEVATION_279:0, DET_ELEVATION_280:0, DET_ELEVATION_ERR_277:0, DET_ELEVATION_ERR_278:0, DET_ELEVATION_ERR_279:0, DET_ELEVATION_ERR_280:0, DET_EXISTENCE_PROB_277:0, DET_EXISTENCE_PROB_278:0, DET_EXISTENCE_PROB_279:0, DET_EXISTENCE_PROB_280:0, DET_HVC_FLAG_277:0, DET_HVC_FLAG_278:0, DET_HVC_FLAG_279:0, DET_HVC_FLAG_280:0, DET_IDM_277:0, DET_IDM_278:0, DET_IDM_279:0, DET_IDM_280:0, DET_MH_CRC16_277_280:0, DET_MH_CYCLE_COUNTER_277_280:0, DET_MH_SCAN_INDEX_4LSB_277_280:0, DET_MTD_277:0, DET_MTD_278:0, DET_MTD_279:0, DET_MTD_280:0, DET_PROB_1STAZHYPO_277:0, DET_PROB_1STAZHYPO_278:0, DET_PROB_1STAZHYPO_279:0, DET_PROB_1STAZHYPO_280:0, DET_RANGE_277:0, DET_RANGE_278:0, DET_RANGE_279:0, DET_RANGE_280:0, DET_RANGE_ERR_277:0, DET_RANGE_ERR_278:0, DET_RANGE_ERR_279:0, DET_RANGE_ERR_280:0, DET_RANGE_VELOCITY_277:16384, DET_RANGE_VELOCITY_278:16384, DET_RANGE_VELOCITY_279:16384, DET_RANGE_VELOCITY_280:16384, DET_RANGE_VELOCITY_ERR_277:0, DET_RANGE_VELOCITY_ERR_278:0, DET_RANGE_VELOCITY_ERR_279:0, DET_RANGE_VELOCITY_ERR_280:0, DET_RCS_277:128, DET_RCS_278:128, DET_RCS_279:128, DET_RCS_280:128, DET_SNR_277:0, DET_SNR_278:0, DET_SNR_279:0, DET_SNR_280:0, DET_SUPER_RES_TARGET_277:0, DET_SUPER_RES_TARGET_278:0, DET_SUPER_RES_TARGET_279:0, DET_SUPER_RES_TARGET_280:0]}, provided-interface=Pi_SG_Detections_277_280_AL
      Pp_SG_Detections_273_276_AL: nonqueued-sender-com-spec{data-element=Vdp_SG_Detections_273_276_AL, init-value=fields=[DET_AZIMUTH_273:0, DET_AZIMUTH_274:0, DET_AZIMUTH_275:0, DET_AZIMUTH_276:0, DET_AZIMUTH_ERR_273:0, DET_AZIMUTH_ERR_274:0, DET_AZIMUTH_ERR_275:0, DET_AZIMUTH_ERR_276:0, DET_BELOW_RAIN_THOLD_273:0, DET_BELOW_RAIN_THOLD_274:0, DET_BELOW_RAIN_THOLD_275:0, DET_BELOW_RAIN_THOLD_276:0, DET_BI_STATIC_FLAG_273:0, DET_BI_STATIC_FLAG_274:0, DET_BI_STATIC_FLAG_275:0, DET_BI_STATIC_FLAG_276:0, DET_CONFD_AZIMUTH_273:0, DET_CONFD_AZIMUTH_274:0, DET_CONFD_AZIMUTH_275:0, DET_CONFD_AZIMUTH_276:0, DET_CONFD_ELEVATION_273:0, DET_CONFD_ELEVATION_274:0, DET_CONFD_ELEVATION_275:0, DET_CONFD_ELEVATION_276:0, DET_ELEVATION_273:0, DET_ELEVATION_274:0, DET_ELEVATION_275:0, DET_ELEVATION_276:0, DET_ELEVATION_ERR_273:0, DET_ELEVATION_ERR_274:0, DET_ELEVATION_ERR_275:0, DET_ELEVATION_ERR_276:0, DET_EXISTENCE_PROB_273:0, DET_EXISTENCE_PROB_274:0, DET_EXISTENCE_PROB_275:0, DET_EXISTENCE_PROB_276:0, DET_HVC_FLAG_273:0, DET_HVC_FLAG_274:0, DET_HVC_FLAG_275:0, DET_HVC_FLAG_276:0, DET_IDM_273:0, DET_IDM_274:0, DET_IDM_275:0, DET_IDM_276:0, DET_MH_CRC16_273_276:0, DET_MH_CYCLE_COUNTER_273_276:0, DET_MH_SCAN_INDEX_4LSB_273_276:0, DET_MTD_273:0, DET_MTD_274:0, DET_MTD_275:0, DET_MTD_276:0, DET_PROB_1STAZHYPO_273:0, DET_PROB_1STAZHYPO_274:0, DET_PROB_1STAZHYPO_275:0, DET_PROB_1STAZHYPO_276:0, DET_RANGE_273:0, DET_RANGE_274:0, DET_RANGE_275:0, DET_RANGE_276:0, DET_RANGE_ERR_273:0, DET_RANGE_ERR_274:0, DET_RANGE_ERR_275:0, DET_RANGE_ERR_276:0, DET_RANGE_VELOCITY_273:16384, DET_RANGE_VELOCITY_274:16384, DET_RANGE_VELOCITY_275:16384, DET_RANGE_VELOCITY_276:16384, DET_RANGE_VELOCITY_ERR_273:0, DET_RANGE_VELOCITY_ERR_274:0, DET_RANGE_VELOCITY_ERR_275:0, DET_RANGE_VELOCITY_ERR_276:0, DET_RCS_273:128, DET_RCS_274:128, DET_RCS_275:128, DET_RCS_276:128, DET_SNR_273:0, DET_SNR_274:0, DET_SNR_275:0, DET_SNR_276:0, DET_SUPER_RES_TARGET_273:0, DET_SUPER_RES_TARGET_274:0, DET_SUPER_RES_TARGET_275:0, DET_SUPER_RES_TARGET_276:0]}, provided-interface=Pi_SG_Detections_273_276_AL
      Pp_SG_Detections_249_252_AL: nonqueued-sender-com-spec{data-element=Vdp_SG_Detections_249_252_AL, init-value=fields=[DET_AZIMUTH_249:0, DET_AZIMUTH_250:0, DET_AZIMUTH_251:0, DET_AZIMUTH_252:0, DET_AZIMUTH_ERR_249:0, DET_AZIMUTH_ERR_250:0, DET_AZIMUTH_ERR_251:0, DET_AZIMUTH_ERR_252:0, DET_BELOW_RAIN_THOLD_249:0, DET_BELOW_RAIN_THOLD_250:0, DET_BELOW_RAIN_THOLD_251:0, DET_BELOW_RAIN_THOLD_252:0, DET_BI_STATIC_FLAG_249:0, DET_BI_STATIC_FLAG_250:0, DET_BI_STATIC_FLAG_251:0, DET_BI_STATIC_FLAG_252:0, DET_CONFD_AZIMUTH_249:0, DET_CONFD_AZIMUTH_250:0, DET_CONFD_AZIMUTH_251:0, DET_CONFD_AZIMUTH_252:0, DET_CONFD_ELEVATION_249:0, DET_CONFD_ELEVATION_250:0, DET_CONFD_ELEVATION_251:0, DET_CONFD_ELEVATION_252:0, DET_ELEVATION_249:0, DET_ELEVATION_250:0, DET_ELEVATION_251:0, DET_ELEVATION_252:0, DET_ELEVATION_ERR_249:0, DET_ELEVATION_ERR_250:0, DET_ELEVATION_ERR_251:0, DET_ELEVATION_ERR_252:0, DET_EXISTENCE_PROB_249:0, DET_EXISTENCE_PROB_250:0, DET_EXISTENCE_PROB_251:0, DET_EXISTENCE_PROB_252:0, DET_HVC_FLAG_249:0, DET_HVC_FLAG_250:0, DET_HVC_FLAG_251:0, DET_HVC_FLAG_252:0, DET_IDM_249:0, DET_IDM_250:0, DET_IDM_251:0, DET_IDM_252:0, DET_MH_CRC16_249_252:0, DET_MH_CYCLE_COUNTER_249_252:0, DET_MH_SCAN_INDEX_4LSB_249_252:0, DET_MTD_249:0, DET_MTD_250:0, DET_MTD_251:0, DET_MTD_252:0, DET_PROB_1STAZHYPO_249:0, DET_PROB_1STAZHYPO_250:0, DET_PROB_1STAZHYPO_251:0, DET_PROB_1STAZHYPO_252:0, DET_RANGE_249:0, DET_RANGE_250:0, DET_RANGE_251:0, DET_RANGE_252:0, DET_RANGE_ERR_249:0, DET_RANGE_ERR_250:0, DET_RANGE_ERR_251:0, DET_RANGE_ERR_252:0, DET_RANGE_VELOCITY_249:16384, DET_RANGE_VELOCITY_250:16384, DET_RANGE_VELOCITY_251:16384, DET_RANGE_VELOCITY_252:16384, DET_RANGE_VELOCITY_ERR_249:0, DET_RANGE_VELOCITY_ERR_250:0, DET_RANGE_VELOCITY_ERR_251:0, DET_RANGE_VELOCITY_ERR_252:0, DET_RCS_249:128, DET_RCS_250:128, DET_RCS_251:128, DET_RCS_252:128, DET_SNR_249:0, DET_SNR_250:0, DET_SNR_251:0, DET_SNR_252:0, DET_SUPER_RES_TARGET_249:0, DET_SUPER_RES_TARGET_250:0, DET_SUPER_RES_TARGET_251:0, DET_SUPER_RES_TARGET_252:0]}, provided-interface=Pi_SG_Detections_249_252_AL
      Pp_SG_Detections_389_392_AL: nonqueued-sender-com-spec{data-element=Vdp_SG_Detections_389_392_AL, init-value=fields=[DET_AZIMUTH_389:0, DET_AZIMUTH_390:0, DET_AZIMUTH_391:0, DET_AZIMUTH_392:0, DET_AZIMUTH_ERR_389:0, DET_AZIMUTH_ERR_390:0, DET_AZIMUTH_ERR_391:0, DET_AZIMUTH_ERR_392:0, DET_BELOW_RAIN_THOLD_389:0, DET_BELOW_RAIN_THOLD_390:0, DET_BELOW_RAIN_THOLD_391:0, DET_BELOW_RAIN_THOLD_392:0, DET_BI_STATIC_FLAG_389:0, DET_BI_STATIC_FLAG_390:0, DET_BI_STATIC_FLAG_391:0, DET_BI_STATIC_FLAG_392:0, DET_CONFD_AZIMUTH_389:0, DET_CONFD_AZIMUTH_390:0, DET_CONFD_AZIMUTH_391:0, DET_CONFD_AZIMUTH_392:0, DET_CONFD_ELEVATION_389:0, DET_CONFD_ELEVATION_390:0, DET_CONFD_ELEVATION_391:0, DET_CONFD_ELEVATION_392:0, DET_ELEVATION_389:0, DET_ELEVATION_390:0, DET_ELEVATION_391:0, DET_ELEVATION_392:0, DET_ELEVATION_ERR_389:0, DET_ELEVATION_ERR_390:0, DET_ELEVATION_ERR_391:0, DET_ELEVATION_ERR_392:0, DET_EXISTENCE_PROB_389:0, DET_EXISTENCE_PROB_390:0, DET_EXISTENCE_PROB_391:0, DET_EXISTENCE_PROB_392:0, DET_HVC_FLAG_389:0, DET_HVC_FLAG_390:0, DET_HVC_FLAG_391:0, DET_HVC_FLAG_392:0, DET_IDM_389:0, DET_IDM_390:0, DET_IDM_391:0, DET_IDM_392:0, DET_MH_CRC16_389_392:0, DET_MH_CYCLE_COUNTER_389_392:0, DET_MH_SCAN_INDEX_4LSB_389_392:0, DET_MTD_389:0, DET_MTD_390:0, DET_MTD_391:0, DET_MTD_392:0, DET_PROB_1STAZHYPO_389:0, DET_PROB_1STAZHYPO_390:0, DET_PROB_1STAZHYPO_391:0, DET_PROB_1STAZHYPO_392:0, DET_RANGE_389:0, DET_RANGE_390:0, DET_RANGE_391:0, DET_RANGE_392:0, DET_RANGE_ERR_389:0, DET_RANGE_ERR_390:0, DET_RANGE_ERR_391:0, DET_RANGE_ERR_392:0, DET_RANGE_VELOCITY_389:16384, DET_RANGE_VELOCITY_390:16384, DET_RANGE_VELOCITY_391:16384, DET_RANGE_VELOCITY_392:16384, DET_RANGE_VELOCITY_ERR_389:0, DET_RANGE_VELOCITY_ERR_390:0, DET_RANGE_VELOCITY_ERR_391:0, DET_RANGE_VELOCITY_ERR_392:0, DET_RCS_389:128, DET_RCS_390:128, DET_RCS_391:128, DET_RCS_392:128, DET_SNR_389:0, DET_SNR_390:0, DET_SNR_391:0, DET_SNR_392:0, DET_SUPER_RES_TARGET_389:0, DET_SUPER_RES_TARGET_390:0, DET_SUPER_RES_TARGET_391:0, DET_SUPER_RES_TARGET_392:0]}, provided-interface=Pi_SG_Detections_389_392_AL
      Pp_SG_Detections_349_352_AL: nonqueued-sender-com-spec{data-element=Vdp_SG_Detections_349_352_AL, init-value=fields=[DET_AZIMUTH_349:0, DET_AZIMUTH_350:0, DET_AZIMUTH_351:0, DET_AZIMUTH_352:0, DET_AZIMUTH_ERR_349:0, DET_AZIMUTH_ERR_350:0, DET_AZIMUTH_ERR_351:0, DET_AZIMUTH_ERR_352:0, DET_BELOW_RAIN_THOLD_349:0, DET_BELOW_RAIN_THOLD_350:0, DET_BELOW_RAIN_THOLD_351:0, DET_BELOW_RAIN_THOLD_352:0, DET_BI_STATIC_FLAG_349:0, DET_BI_STATIC_FLAG_350:0, DET_BI_STATIC_FLAG_351:0, DET_BI_STATIC_FLAG_352:0, DET_CONFD_AZIMUTH_349:0, DET_CONFD_AZIMUTH_350:0, DET_CONFD_AZIMUTH_351:0, DET_CONFD_AZIMUTH_352:0, DET_CONFD_ELEVATION_349:0, DET_CONFD_ELEVATION_350:0, DET_CONFD_ELEVATION_351:0, DET_CONFD_ELEVATION_352:0, DET_ELEVATION_349:0, DET_ELEVATION_350:0, DET_ELEVATION_351:0, DET_ELEVATION_352:0, DET_ELEVATION_ERR_349:0, DET_ELEVATION_ERR_350:0, DET_ELEVATION_ERR_351:0, DET_ELEVATION_ERR_352:0, DET_EXISTENCE_PROB_349:0, DET_EXISTENCE_PROB_350:0, DET_EXISTENCE_PROB_351:0, DET_EXISTENCE_PROB_352:0, DET_HVC_FLAG_349:0, DET_HVC_FLAG_350:0, DET_HVC_FLAG_351:0, DET_HVC_FLAG_352:0, DET_IDM_349:0, DET_IDM_350:0, DET_IDM_351:0, DET_IDM_352:0, DET_MH_CRC16_349_352:0, DET_MH_CYCLE_COUNTER_349_352:0, DET_MH_SCAN_INDEX_4LSB_349_352:0, DET_MTD_349:0, DET_MTD_350:0, DET_MTD_351:0, DET_MTD_352:0, DET_PROB_1STAZHYPO_349:0, DET_PROB_1STAZHYPO_350:0, DET_PROB_1STAZHYPO_351:0, DET_PROB_1STAZHYPO_352:0, DET_RANGE_349:0, DET_RANGE_350:0, DET_RANGE_351:0, DET_RANGE_352:0, DET_RANGE_ERR_349:0, DET_RANGE_ERR_350:0, DET_RANGE_ERR_351:0, DET_RANGE_ERR_352:0, DET_RANGE_VELOCITY_349:16384, DET_RANGE_VELOCITY_350:16384, DET_RANGE_VELOCITY_351:16384, DET_RANGE_VELOCITY_352:16384, DET_RANGE_VELOCITY_ERR_349:0, DET_RANGE_VELOCITY_ERR_350:0, DET_RANGE_VELOCITY_ERR_351:0, DET_RANGE_VELOCITY_ERR_352:0, DET_RCS_349:128, DET_RCS_350:128, DET_RCS_351:128, DET_RCS_352:128, DET_SNR_349:0, DET_SNR_350:0, DET_SNR_351:0, DET_SNR_352:0, DET_SUPER_RES_TARGET_349:0, DET_SUPER_RES_TARGET_350:0, DET_SUPER_RES_TARGET_351:0, DET_SUPER_RES_TARGET_352:0]}, provided-interface=Pi_SG_Detections_349_352_AL
      Pp_SG_Detections_245_248_AL: nonqueued-sender-com-spec{data-element=Vdp_SG_Detections_245_248_AL, init-value=fields=[DET_AZIMUTH_245:0, DET_AZIMUTH_246:0, DET_AZIMUTH_247:0, DET_AZIMUTH_248:0, DET_AZIMUTH_ERR_245:0, DET_AZIMUTH_ERR_246:0, DET_AZIMUTH_ERR_247:0, DET_AZIMUTH_ERR_248:0, DET_BELOW_RAIN_THOLD_245:0, DET_BELOW_RAIN_THOLD_246:0, DET_BELOW_RAIN_THOLD_247:0, DET_BELOW_RAIN_THOLD_248:0, DET_BI_STATIC_FLAG_245:0, DET_BI_STATIC_FLAG_246:0, DET_BI_STATIC_FLAG_247:0, DET_BI_STATIC_FLAG_248:0, DET_CONFD_AZIMUTH_245:0, DET_CONFD_AZIMUTH_246:0, DET_CONFD_AZIMUTH_247:0, DET_CONFD_AZIMUTH_248:0, DET_CONFD_ELEVATION_245:0, DET_CONFD_ELEVATION_246:0, DET_CONFD_ELEVATION_247:0, DET_CONFD_ELEVATION_248:0, DET_ELEVATION_245:0, DET_ELEVATION_246:0, DET_ELEVATION_247:0, DET_ELEVATION_248:0, DET_ELEVATION_ERR_245:0, DET_ELEVATION_ERR_246:0, DET_ELEVATION_ERR_247:0, DET_ELEVATION_ERR_248:0, DET_EXISTENCE_PROB_245:0, DET_EXISTENCE_PROB_246:0, DET_EXISTENCE_PROB_247:0, DET_EXISTENCE_PROB_248:0, DET_HVC_FLAG_245:0, DET_HVC_FLAG_246:0, DET_HVC_FLAG_247:0, DET_HVC_FLAG_248:0, DET_IDM_245:0, DET_IDM_246:0, DET_IDM_247:0, DET_IDM_248:0, DET_MH_CRC16_245_248:0, DET_MH_CYCLE_COUNTER_245_248:0, DET_MH_SCAN_INDEX_4LSB_245_248:0, DET_MTD_245:0, DET_MTD_246:0, DET_MTD_247:0, DET_MTD_248:0, DET_PROB_1STAZHYPO_245:0, DET_PROB_1STAZHYPO_246:0, DET_PROB_1STAZHYPO_247:0, DET_PROB_1STAZHYPO_248:0, DET_RANGE_245:0, DET_RANGE_246:0, DET_RANGE_247:0, DET_RANGE_248:0, DET_RANGE_ERR_245:0, DET_RANGE_ERR_246:0, DET_RANGE_ERR_247:0, DET_RANGE_ERR_248:0, DET_RANGE_VELOCITY_245:16384, DET_RANGE_VELOCITY_246:16384, DET_RANGE_VELOCITY_247:16384, DET_RANGE_VELOCITY_248:16384, DET_RANGE_VELOCITY_ERR_245:0, DET_RANGE_VELOCITY_ERR_246:0, DET_RANGE_VELOCITY_ERR_247:0, DET_RANGE_VELOCITY_ERR_248:0, DET_RCS_245:128, DET_RCS_246:128, DET_RCS_247:128, DET_RCS_248:128, DET_SNR_245:0, DET_SNR_246:0, DET_SNR_247:0, DET_SNR_248:0, DET_SUPER_RES_TARGET_245:0, DET_SUPER_RES_TARGET_246:0, DET_SUPER_RES_TARGET_247:0, DET_SUPER_RES_TARGET_248:0]}, provided-interface=Pi_SG_Detections_245_248_AL
      Pp_SG_Detections_361_364_AL: nonqueued-sender-com-spec{data-element=Vdp_SG_Detections_361_364_AL, init-value=fields=[DET_AZIMUTH_361:0, DET_AZIMUTH_362:0, DET_AZIMUTH_363:0, DET_AZIMUTH_364:0, DET_AZIMUTH_ERR_361:0, DET_AZIMUTH_ERR_362:0, DET_AZIMUTH_ERR_363:0, DET_AZIMUTH_ERR_364:0, DET_BELOW_RAIN_THOLD_361:0, DET_BELOW_RAIN_THOLD_362:0, DET_BELOW_RAIN_THOLD_363:0, DET_BELOW_RAIN_THOLD_364:0, DET_BI_STATIC_FLAG_361:0, DET_BI_STATIC_FLAG_362:0, DET_BI_STATIC_FLAG_363:0, DET_BI_STATIC_FLAG_364:0, DET_CONFD_AZIMUTH_361:0, DET_CONFD_AZIMUTH_362:0, DET_CONFD_AZIMUTH_363:0, DET_CONFD_AZIMUTH_364:0, DET_CONFD_ELEVATION_361:0, DET_CONFD_ELEVATION_362:0, DET_CONFD_ELEVATION_363:0, DET_CONFD_ELEVATION_364:0, DET_ELEVATION_361:0, DET_ELEVATION_362:0, DET_ELEVATION_363:0, DET_ELEVATION_364:0, DET_ELEVATION_ERR_361:0, DET_ELEVATION_ERR_362:0, DET_ELEVATION_ERR_363:0, DET_ELEVATION_ERR_364:0, DET_EXISTENCE_PROB_361:0, DET_EXISTENCE_PROB_362:0, DET_EXISTENCE_PROB_363:0, DET_EXISTENCE_PROB_364:0, DET_HVC_FLAG_361:0, DET_HVC_FLAG_362:0, DET_HVC_FLAG_363:0, DET_HVC_FLAG_364:0, DET_IDM_361:0, DET_IDM_362:0, DET_IDM_363:0, DET_IDM_364:0, DET_MH_CRC16_361_364:0, DET_MH_CYCLE_COUNTER_361_364:0, DET_MH_SCAN_INDEX_4LSB_361_364:0, DET_MTD_361:0, DET_MTD_362:0, DET_MTD_363:0, DET_MTD_364:0, DET_PROB_1STAZHYPO_361:0, DET_PROB_1STAZHYPO_362:0, DET_PROB_1STAZHYPO_363:0, DET_PROB_1STAZHYPO_364:0, DET_RANGE_361:0, DET_RANGE_362:0, DET_RANGE_363:0, DET_RANGE_364:0, DET_RANGE_ERR_361:0, DET_RANGE_ERR_362:0, DET_RANGE_ERR_363:0, DET_RANGE_ERR_364:0, DET_RANGE_VELOCITY_361:16384, DET_RANGE_VELOCITY_362:16384, DET_RANGE_VELOCITY_363:16384, DET_RANGE_VELOCITY_364:16384, DET_RANGE_VELOCITY_ERR_361:0, DET_RANGE_VELOCITY_ERR_362:0, DET_RANGE_VELOCITY_ERR_363:0, DET_RANGE_VELOCITY_ERR_364:0, DET_RCS_361:128, DET_RCS_362:128, DET_RCS_363:128, DET_RCS_364:128, DET_SNR_361:0, DET_SNR_362:0, DET_SNR_363:0, DET_SNR_364:0, DET_SUPER_RES_TARGET_361:0, DET_SUPER_RES_TARGET_362:0, DET_SUPER_RES_TARGET_363:0, DET_SUPER_RES_TARGET_364:0]}, provided-interface=Pi_SG_Detections_361_364_AL
      Pp_SG_Detections_353_356_AL: nonqueued-sender-com-spec{data-element=Vdp_SG_Detections_353_356_AL, init-value=fields=[DET_AZIMUTH_353:0, DET_AZIMUTH_354:0, DET_AZIMUTH_355:0, DET_AZIMUTH_356:0, DET_AZIMUTH_ERR_353:0, DET_AZIMUTH_ERR_354:0, DET_AZIMUTH_ERR_355:0, DET_AZIMUTH_ERR_356:0, DET_BELOW_RAIN_THOLD_353:0, DET_BELOW_RAIN_THOLD_354:0, DET_BELOW_RAIN_THOLD_355:0, DET_BELOW_RAIN_THOLD_356:0, DET_BI_STATIC_FLAG_353:0, DET_BI_STATIC_FLAG_354:0, DET_BI_STATIC_FLAG_355:0, DET_BI_STATIC_FLAG_356:0, DET_CONFD_AZIMUTH_353:0, DET_CONFD_AZIMUTH_354:0, DET_CONFD_AZIMUTH_355:0, DET_CONFD_AZIMUTH_356:0, DET_CONFD_ELEVATION_353:0, DET_CONFD_ELEVATION_354:0, DET_CONFD_ELEVATION_355:0, DET_CONFD_ELEVATION_356:0, DET_ELEVATION_353:0, DET_ELEVATION_354:0, DET_ELEVATION_355:0, DET_ELEVATION_356:0, DET_ELEVATION_ERR_353:0, DET_ELEVATION_ERR_354:0, DET_ELEVATION_ERR_355:0, DET_ELEVATION_ERR_356:0, DET_EXISTENCE_PROB_353:0, DET_EXISTENCE_PROB_354:0, DET_EXISTENCE_PROB_355:0, DET_EXISTENCE_PROB_356:0, DET_HVC_FLAG_353:0, DET_HVC_FLAG_354:0, DET_HVC_FLAG_355:0, DET_HVC_FLAG_356:0, DET_IDM_353:0, DET_IDM_354:0, DET_IDM_355:0, DET_IDM_356:0, DET_MH_CRC16_353_356:0, DET_MH_CYCLE_COUNTER_353_356:0, DET_MH_SCAN_INDEX_4LSB_353_356:0, DET_MTD_353:0, DET_MTD_354:0, DET_MTD_355:0, DET_MTD_356:0, DET_PROB_1STAZHYPO_353:0, DET_PROB_1STAZHYPO_354:0, DET_PROB_1STAZHYPO_355:0, DET_PROB_1STAZHYPO_356:0, DET_RANGE_353:0, DET_RANGE_354:0, DET_RANGE_355:0, DET_RANGE_356:0, DET_RANGE_ERR_353:0, DET_RANGE_ERR_354:0, DET_RANGE_ERR_355:0, DET_RANGE_ERR_356:0, DET_RANGE_VELOCITY_353:16384, DET_RANGE_VELOCITY_354:16384, DET_RANGE_VELOCITY_355:16384, DET_RANGE_VELOCITY_356:16384, DET_RANGE_VELOCITY_ERR_353:0, DET_RANGE_VELOCITY_ERR_354:0, DET_RANGE_VELOCITY_ERR_355:0, DET_RANGE_VELOCITY_ERR_356:0, DET_RCS_353:128, DET_RCS_354:128, DET_RCS_355:128, DET_RCS_356:128, DET_SNR_353:0, DET_SNR_354:0, DET_SNR_355:0, DET_SNR_356:0, DET_SUPER_RES_TARGET_353:0, DET_SUPER_RES_TARGET_354:0, DET_SUPER_RES_TARGET_355:0, DET_SUPER_RES_TARGET_356:0]}, provided-interface=Pi_SG_Detections_353_356_AL
      Pp_SG_Detections_253_256_AL: nonqueued-sender-com-spec{data-element=Vdp_SG_Detections_253_256_AL, init-value=fields=[DET_AZIMUTH_253:0, DET_AZIMUTH_254:0, DET_AZIMUTH_255:0, DET_AZIMUTH_256:0, DET_AZIMUTH_ERR_253:0, DET_AZIMUTH_ERR_254:0, DET_AZIMUTH_ERR_255:0, DET_AZIMUTH_ERR_256:0, DET_BELOW_RAIN_THOLD_253:0, DET_BELOW_RAIN_THOLD_254:0, DET_BELOW_RAIN_THOLD_255:0, DET_BELOW_RAIN_THOLD_256:0, DET_BI_STATIC_FLAG_253:0, DET_BI_STATIC_FLAG_254:0, DET_BI_STATIC_FLAG_255:0, DET_BI_STATIC_FLAG_256:0, DET_CONFD_AZIMUTH_253:0, DET_CONFD_AZIMUTH_254:0, DET_CONFD_AZIMUTH_255:0, DET_CONFD_AZIMUTH_256:0, DET_CONFD_ELEVATION_253:0, DET_CONFD_ELEVATION_254:0, DET_CONFD_ELEVATION_255:0, DET_CONFD_ELEVATION_256:0, DET_ELEVATION_253:0, DET_ELEVATION_254:0, DET_ELEVATION_255:0, DET_ELEVATION_256:0, DET_ELEVATION_ERR_253:0, DET_ELEVATION_ERR_254:0, DET_ELEVATION_ERR_255:0, DET_ELEVATION_ERR_256:0, DET_EXISTENCE_PROB_253:0, DET_EXISTENCE_PROB_254:0, DET_EXISTENCE_PROB_255:0, DET_EXISTENCE_PROB_256:0, DET_HVC_FLAG_253:0, DET_HVC_FLAG_254:0, DET_HVC_FLAG_255:0, DET_HVC_FLAG_256:0, DET_IDM_253:0, DET_IDM_254:0, DET_IDM_255:0, DET_IDM_256:0, DET_MH_CRC16_253_256:0, DET_MH_CYCLE_COUNTER_253_256:0, DET_MH_SCAN_INDEX_4LSB_253_256:0, DET_MTD_253:0, DET_MTD_254:0, DET_MTD_255:0, DET_MTD_256:0, DET_PROB_1STAZHYPO_253:0, DET_PROB_1STAZHYPO_254:0, DET_PROB_1STAZHYPO_255:0, DET_PROB_1STAZHYPO_256:0, DET_RANGE_253:0, DET_RANGE_254:0, DET_RANGE_255:0, DET_RANGE_256:0, DET_RANGE_ERR_253:0, DET_RANGE_ERR_254:0, DET_RANGE_ERR_255:0, DET_RANGE_ERR_256:0, DET_RANGE_VELOCITY_253:16384, DET_RANGE_VELOCITY_254:16384, DET_RANGE_VELOCITY_255:16384, DET_RANGE_VELOCITY_256:16384, DET_RANGE_VELOCITY_ERR_253:0, DET_RANGE_VELOCITY_ERR_254:0, DET_RANGE_VELOCITY_ERR_255:0, DET_RANGE_VELOCITY_ERR_256:0, DET_RCS_253:128, DET_RCS_254:128, DET_RCS_255:128, DET_RCS_256:128, DET_SNR_253:0, DET_SNR_254:0, DET_SNR_255:0, DET_SNR_256:0, DET_SUPER_RES_TARGET_253:0, DET_SUPER_RES_TARGET_254:0, DET_SUPER_RES_TARGET_255:0, DET_SUPER_RES_TARGET_256:0]}, provided-interface=Pi_SG_Detections_253_256_AL
      Pp_SG_Detections_257_260_AL: nonqueued-sender-com-spec{data-element=Vdp_SG_Detections_257_260_AL, init-value=fields=[DET_AZIMUTH_257:0, DET_AZIMUTH_258:0, DET_AZIMUTH_259:0, DET_AZIMUTH_260:0, DET_AZIMUTH_ERR_257:0, DET_AZIMUTH_ERR_258:0, DET_AZIMUTH_ERR_259:0, DET_AZIMUTH_ERR_260:0, DET_BELOW_RAIN_THOLD_257:0, DET_BELOW_RAIN_THOLD_258:0, DET_BELOW_RAIN_THOLD_259:0, DET_BELOW_RAIN_THOLD_260:0, DET_BI_STATIC_FLAG_257:0, DET_BI_STATIC_FLAG_258:0, DET_BI_STATIC_FLAG_259:0, DET_BI_STATIC_FLAG_260:0, DET_CONFD_AZIMUTH_257:0, DET_CONFD_AZIMUTH_258:0, DET_CONFD_AZIMUTH_259:0, DET_CONFD_AZIMUTH_260:0, DET_CONFD_ELEVATION_257:0, DET_CONFD_ELEVATION_258:0, DET_CONFD_ELEVATION_259:0, DET_CONFD_ELEVATION_260:0, DET_ELEVATION_257:0, DET_ELEVATION_258:0, DET_ELEVATION_259:0, DET_ELEVATION_260:0, DET_ELEVATION_ERR_257:0, DET_ELEVATION_ERR_258:0, DET_ELEVATION_ERR_259:0, DET_ELEVATION_ERR_260:0, DET_EXISTENCE_PROB_257:0, DET_EXISTENCE_PROB_258:0, DET_EXISTENCE_PROB_259:0, DET_EXISTENCE_PROB_260:0, DET_HVC_FLAG_257:0, DET_HVC_FLAG_258:0, DET_HVC_FLAG_259:0, DET_HVC_FLAG_260:0, DET_IDM_257:0, DET_IDM_258:0, DET_IDM_259:0, DET_IDM_260:0, DET_MH_CRC16_257_260:0, DET_MH_CYCLE_COUNTER_257_260:0, DET_MH_SCAN_INDEX_4LSB_257_260:0, DET_MTD_257:0, DET_MTD_258:0, DET_MTD_259:0, DET_MTD_260:0, DET_PROB_1STAZHYPO_257:0, DET_PROB_1STAZHYPO_258:0, DET_PROB_1STAZHYPO_259:0, DET_PROB_1STAZHYPO_260:0, DET_RANGE_257:0, DET_RANGE_258:0, DET_RANGE_259:0, DET_RANGE_260:0, DET_RANGE_ERR_257:0, DET_RANGE_ERR_258:0, DET_RANGE_ERR_259:0, DET_RANGE_ERR_260:0, DET_RANGE_VELOCITY_257:16384, DET_RANGE_VELOCITY_258:16384, DET_RANGE_VELOCITY_259:16384, DET_RANGE_VELOCITY_260:16384, DET_RANGE_VELOCITY_ERR_257:0, DET_RANGE_VELOCITY_ERR_258:0, DET_RANGE_VELOCITY_ERR_259:0, DET_RANGE_VELOCITY_ERR_260:0, DET_RCS_257:128, DET_RCS_258:128, DET_RCS_259:128, DET_RCS_260:128, DET_SNR_257:0, DET_SNR_258:0, DET_SNR_259:0, DET_SNR_260:0, DET_SUPER_RES_TARGET_257:0, DET_SUPER_RES_TARGET_258:0, DET_SUPER_RES_TARGET_259:0, DET_SUPER_RES_TARGET_260:0]}, provided-interface=Pi_SG_Detections_257_260_AL
      Pp_SG_Detections_373_376_AL: nonqueued-sender-com-spec{data-element=Vdp_SG_Detections_373_376_AL, init-value=fields=[DET_AZIMUTH_373:0, DET_AZIMUTH_374:0, DET_AZIMUTH_375:0, DET_AZIMUTH_376:0, DET_AZIMUTH_ERR_373:0, DET_AZIMUTH_ERR_374:0, DET_AZIMUTH_ERR_375:0, DET_AZIMUTH_ERR_376:0, DET_BELOW_RAIN_THOLD_373:0, DET_BELOW_RAIN_THOLD_374:0, DET_BELOW_RAIN_THOLD_375:0, DET_BELOW_RAIN_THOLD_376:0, DET_BI_STATIC_FLAG_373:0, DET_BI_STATIC_FLAG_374:0, DET_BI_STATIC_FLAG_375:0, DET_BI_STATIC_FLAG_376:0, DET_CONFD_AZIMUTH_373:0, DET_CONFD_AZIMUTH_374:0, DET_CONFD_AZIMUTH_375:0, DET_CONFD_AZIMUTH_376:0, DET_CONFD_ELEVATION_373:0, DET_CONFD_ELEVATION_374:0, DET_CONFD_ELEVATION_375:0, DET_CONFD_ELEVATION_376:0, DET_ELEVATION_373:0, DET_ELEVATION_374:0, DET_ELEVATION_375:0, DET_ELEVATION_376:0, DET_ELEVATION_ERR_373:0, DET_ELEVATION_ERR_374:0, DET_ELEVATION_ERR_375:0, DET_ELEVATION_ERR_376:0, DET_EXISTENCE_PROB_373:0, DET_EXISTENCE_PROB_374:0, DET_EXISTENCE_PROB_375:0, DET_EXISTENCE_PROB_376:0, DET_HVC_FLAG_373:0, DET_HVC_FLAG_374:0, DET_HVC_FLAG_375:0, DET_HVC_FLAG_376:0, DET_IDM_373:0, DET_IDM_374:0, DET_IDM_375:0, DET_IDM_376:0, DET_MH_CRC16_373_376:0, DET_MH_CYCLE_COUNTER_373_376:0, DET_MH_SCAN_INDEX_4LSB_373_376:0, DET_MTD_373:0, DET_MTD_374:0, DET_MTD_375:0, DET_MTD_376:0, DET_PROB_1STAZHYPO_373:0, DET_PROB_1STAZHYPO_374:0, DET_PROB_1STAZHYPO_375:0, DET_PROB_1STAZHYPO_376:0, DET_RANGE_373:0, DET_RANGE_374:0, DET_RANGE_375:0, DET_RANGE_376:0, DET_RANGE_ERR_373:0, DET_RANGE_ERR_374:0, DET_RANGE_ERR_375:0, DET_RANGE_ERR_376:0, DET_RANGE_VELOCITY_373:16384, DET_RANGE_VELOCITY_374:16384, DET_RANGE_VELOCITY_375:16384, DET_RANGE_VELOCITY_376:16384, DET_RANGE_VELOCITY_ERR_373:0, DET_RANGE_VELOCITY_ERR_374:0, DET_RANGE_VELOCITY_ERR_375:0, DET_RANGE_VELOCITY_ERR_376:0, DET_RCS_373:128, DET_RCS_374:128, DET_RCS_375:128, DET_RCS_376:128, DET_SNR_373:0, DET_SNR_374:0, DET_SNR_375:0, DET_SNR_376:0, DET_SUPER_RES_TARGET_373:0, DET_SUPER_RES_TARGET_374:0, DET_SUPER_RES_TARGET_375:0, DET_SUPER_RES_TARGET_376:0]}, provided-interface=Pi_SG_Detections_373_376_AL
      Pp_SG_Detections_305_308_AL: nonqueued-sender-com-spec{data-element=Vdp_SG_Detections_305_308_AL, init-value=fields=[DET_AZIMUTH_305:0, DET_AZIMUTH_306:0, DET_AZIMUTH_307:0, DET_AZIMUTH_308:0, DET_AZIMUTH_ERR_305:0, DET_AZIMUTH_ERR_306:0, DET_AZIMUTH_ERR_307:0, DET_AZIMUTH_ERR_308:0, DET_BELOW_RAIN_THOLD_305:0, DET_BELOW_RAIN_THOLD_306:0, DET_BELOW_RAIN_THOLD_307:0, DET_BELOW_RAIN_THOLD_308:0, DET_BI_STATIC_FLAG_305:0, DET_BI_STATIC_FLAG_306:0, DET_BI_STATIC_FLAG_307:0, DET_BI_STATIC_FLAG_308:0, DET_CONFD_AZIMUTH_305:0, DET_CONFD_AZIMUTH_306:0, DET_CONFD_AZIMUTH_307:0, DET_CONFD_AZIMUTH_308:0, DET_CONFD_ELEVATION_305:0, DET_CONFD_ELEVATION_306:0, DET_CONFD_ELEVATION_307:0, DET_CONFD_ELEVATION_308:0, DET_ELEVATION_305:0, DET_ELEVATION_306:0, DET_ELEVATION_307:0, DET_ELEVATION_308:0, DET_ELEVATION_ERR_305:0, DET_ELEVATION_ERR_306:0, DET_ELEVATION_ERR_307:0, DET_ELEVATION_ERR_308:0, DET_EXISTENCE_PROB_305:0, DET_EXISTENCE_PROB_306:0, DET_EXISTENCE_PROB_307:0, DET_EXISTENCE_PROB_308:0, DET_HVC_FLAG_305:0, DET_HVC_FLAG_306:0, DET_HVC_FLAG_307:0, DET_HVC_FLAG_308:0, DET_IDM_305:0, DET_IDM_306:0, DET_IDM_307:0, DET_IDM_308:0, DET_MH_CRC16_305_308:0, DET_MH_CYCLE_COUNTER_305_308:0, DET_MH_SCAN_INDEX_4LSB_305_308:0, DET_MTD_305:0, DET_MTD_306:0, DET_MTD_307:0, DET_MTD_308:0, DET_PROB_1STAZHYPO_305:0, DET_PROB_1STAZHYPO_306:0, DET_PROB_1STAZHYPO_307:0, DET_PROB_1STAZHYPO_308:0, DET_RANGE_305:0, DET_RANGE_306:0, DET_RANGE_307:0, DET_RANGE_308:0, DET_RANGE_ERR_305:0, DET_RANGE_ERR_306:0, DET_RANGE_ERR_307:0, DET_RANGE_ERR_308:0, DET_RANGE_VELOCITY_305:16384, DET_RANGE_VELOCITY_306:16384, DET_RANGE_VELOCITY_307:16384, DET_RANGE_VELOCITY_308:16384, DET_RANGE_VELOCITY_ERR_305:0, DET_RANGE_VELOCITY_ERR_306:0, DET_RANGE_VELOCITY_ERR_307:0, DET_RANGE_VELOCITY_ERR_308:0, DET_RCS_305:128, DET_RCS_306:128, DET_RCS_307:128, DET_RCS_308:128, DET_SNR_305:0, DET_SNR_306:0, DET_SNR_307:0, DET_SNR_308:0, DET_SUPER_RES_TARGET_305:0, DET_SUPER_RES_TARGET_306:0, DET_SUPER_RES_TARGET_307:0, DET_SUPER_RES_TARGET_308:0]}, provided-interface=Pi_SG_Detections_305_308_AL
      Pp_SG_Detections_393_396_AL: nonqueued-sender-com-spec{data-element=Vdp_SG_Detections_393_396_AL, init-value=fields=[DET_AZIMUTH_393:0, DET_AZIMUTH_394:0, DET_AZIMUTH_395:0, DET_AZIMUTH_396:0, DET_AZIMUTH_ERR_393:0, DET_AZIMUTH_ERR_394:0, DET_AZIMUTH_ERR_395:0, DET_AZIMUTH_ERR_396:0, DET_BELOW_RAIN_THOLD_393:0, DET_BELOW_RAIN_THOLD_394:0, DET_BELOW_RAIN_THOLD_395:0, DET_BELOW_RAIN_THOLD_396:0, DET_BI_STATIC_FLAG_393:0, DET_BI_STATIC_FLAG_394:0, DET_BI_STATIC_FLAG_395:0, DET_BI_STATIC_FLAG_396:0, DET_CONFD_AZIMUTH_393:0, DET_CONFD_AZIMUTH_394:0, DET_CONFD_AZIMUTH_395:0, DET_CONFD_AZIMUTH_396:0, DET_CONFD_ELEVATION_393:0, DET_CONFD_ELEVATION_394:0, DET_CONFD_ELEVATION_395:0, DET_CONFD_ELEVATION_396:0, DET_ELEVATION_393:0, DET_ELEVATION_394:0, DET_ELEVATION_395:0, DET_ELEVATION_396:0, DET_ELEVATION_ERR_393:0, DET_ELEVATION_ERR_394:0, DET_ELEVATION_ERR_395:0, DET_ELEVATION_ERR_396:0, DET_EXISTENCE_PROB_393:0, DET_EXISTENCE_PROB_394:0, DET_EXISTENCE_PROB_395:0, DET_EXISTENCE_PROB_396:0, DET_HVC_FLAG_393:0, DET_HVC_FLAG_394:0, DET_HVC_FLAG_395:0, DET_HVC_FLAG_396:0, DET_IDM_393:0, DET_IDM_394:0, DET_IDM_395:0, DET_IDM_396:0, DET_MH_CRC16_393_396:0, DET_MH_CYCLE_COUNTER_393_396:0, DET_MH_SCAN_INDEX_4LSB_393_396:0, DET_MTD_393:0, DET_MTD_394:0, DET_MTD_395:0, DET_MTD_396:0, DET_PROB_1STAZHYPO_393:0, DET_PROB_1STAZHYPO_394:0, DET_PROB_1STAZHYPO_395:0, DET_PROB_1STAZHYPO_396:0, DET_RANGE_393:0, DET_RANGE_394:0, DET_RANGE_395:0, DET_RANGE_396:0, DET_RANGE_ERR_393:0, DET_RANGE_ERR_394:0, DET_RANGE_ERR_395:0, DET_RANGE_ERR_396:0, DET_RANGE_VELOCITY_393:16384, DET_RANGE_VELOCITY_394:16384, DET_RANGE_VELOCITY_395:16384, DET_RANGE_VELOCITY_396:16384, DET_RANGE_VELOCITY_ERR_393:0, DET_RANGE_VELOCITY_ERR_394:0, DET_RANGE_VELOCITY_ERR_395:0, DET_RANGE_VELOCITY_ERR_396:0, DET_RCS_393:128, DET_RCS_394:128, DET_RCS_395:128, DET_RCS_396:128, DET_SNR_393:0, DET_SNR_394:0, DET_SNR_395:0, DET_SNR_396:0, DET_SUPER_RES_TARGET_393:0, DET_SUPER_RES_TARGET_394:0, DET_SUPER_RES_TARGET_395:0, DET_SUPER_RES_TARGET_396:0]}, provided-interface=Pi_SG_Detections_393_396_AL
      Pp_SG_Detections_325_328_AL: nonqueued-sender-com-spec{data-element=Vdp_SG_Detections_325_328_AL, init-value=fields=[DET_AZIMUTH_325:0, DET_AZIMUTH_326:0, DET_AZIMUTH_327:0, DET_AZIMUTH_328:0, DET_AZIMUTH_ERR_325:0, DET_AZIMUTH_ERR_326:0, DET_AZIMUTH_ERR_327:0, DET_AZIMUTH_ERR_328:0, DET_BELOW_RAIN_THOLD_325:0, DET_BELOW_RAIN_THOLD_326:0, DET_BELOW_RAIN_THOLD_327:0, DET_BELOW_RAIN_THOLD_328:0, DET_BI_STATIC_FLAG_325:0, DET_BI_STATIC_FLAG_326:0, DET_BI_STATIC_FLAG_327:0, DET_BI_STATIC_FLAG_328:0, DET_CONFD_AZIMUTH_325:0, DET_CONFD_AZIMUTH_326:0, DET_CONFD_AZIMUTH_327:0, DET_CONFD_AZIMUTH_328:0, DET_CONFD_ELEVATION_325:0, DET_CONFD_ELEVATION_326:0, DET_CONFD_ELEVATION_327:0, DET_CONFD_ELEVATION_328:0, DET_ELEVATION_325:0, DET_ELEVATION_326:0, DET_ELEVATION_327:0, DET_ELEVATION_328:0, DET_ELEVATION_ERR_325:0, DET_ELEVATION_ERR_326:0, DET_ELEVATION_ERR_327:0, DET_ELEVATION_ERR_328:0, DET_EXISTENCE_PROB_325:0, DET_EXISTENCE_PROB_326:0, DET_EXISTENCE_PROB_327:0, DET_EXISTENCE_PROB_328:0, DET_HVC_FLAG_325:0, DET_HVC_FLAG_326:0, DET_HVC_FLAG_327:0, DET_HVC_FLAG_328:0, DET_IDM_325:0, DET_IDM_326:0, DET_IDM_327:0, DET_IDM_328:0, DET_MH_CRC16_325_328:0, DET_MH_CYCLE_COUNTER_325_328:0, DET_MH_SCAN_INDEX_4LSB_325_328:0, DET_MTD_325:0, DET_MTD_326:0, DET_MTD_327:0, DET_MTD_328:0, DET_PROB_1STAZHYPO_325:0, DET_PROB_1STAZHYPO_326:0, DET_PROB_1STAZHYPO_327:0, DET_PROB_1STAZHYPO_328:0, DET_RANGE_325:0, DET_RANGE_326:0, DET_RANGE_327:0, DET_RANGE_328:0, DET_RANGE_ERR_325:0, DET_RANGE_ERR_326:0, DET_RANGE_ERR_327:0, DET_RANGE_ERR_328:0, DET_RANGE_VELOCITY_325:16384, DET_RANGE_VELOCITY_326:16384, DET_RANGE_VELOCITY_327:16384, DET_RANGE_VELOCITY_328:16384, DET_RANGE_VELOCITY_ERR_325:0, DET_RANGE_VELOCITY_ERR_326:0, DET_RANGE_VELOCITY_ERR_327:0, DET_RANGE_VELOCITY_ERR_328:0, DET_RCS_325:128, DET_RCS_326:128, DET_RCS_327:128, DET_RCS_328:128, DET_SNR_325:0, DET_SNR_326:0, DET_SNR_327:0, DET_SNR_328:0, DET_SUPER_RES_TARGET_325:0, DET_SUPER_RES_TARGET_326:0, DET_SUPER_RES_TARGET_327:0, DET_SUPER_RES_TARGET_328:0]}, provided-interface=Pi_SG_Detections_325_328_AL
      Pp_SG_Detections_377_380_AL: nonqueued-sender-com-spec{data-element=Vdp_SG_Detections_377_380_AL, init-value=fields=[DET_AZIMUTH_377:0, DET_AZIMUTH_378:0, DET_AZIMUTH_379:0, DET_AZIMUTH_380:0, DET_AZIMUTH_ERR_377:0, DET_AZIMUTH_ERR_378:0, DET_AZIMUTH_ERR_379:0, DET_AZIMUTH_ERR_380:0, DET_BELOW_RAIN_THOLD_377:0, DET_BELOW_RAIN_THOLD_378:0, DET_BELOW_RAIN_THOLD_379:0, DET_BELOW_RAIN_THOLD_380:0, DET_BI_STATIC_FLAG_377:0, DET_BI_STATIC_FLAG_378:0, DET_BI_STATIC_FLAG_379:0, DET_BI_STATIC_FLAG_380:0, DET_CONFD_AZIMUTH_377:0, DET_CONFD_AZIMUTH_378:0, DET_CONFD_AZIMUTH_379:0, DET_CONFD_AZIMUTH_380:0, DET_CONFD_ELEVATION_377:0, DET_CONFD_ELEVATION_378:0, DET_CONFD_ELEVATION_379:0, DET_CONFD_ELEVATION_380:0, DET_ELEVATION_377:0, DET_ELEVATION_378:0, DET_ELEVATION_379:0, DET_ELEVATION_380:0, DET_ELEVATION_ERR_377:0, DET_ELEVATION_ERR_378:0, DET_ELEVATION_ERR_379:0, DET_ELEVATION_ERR_380:0, DET_EXISTENCE_PROB_377:0, DET_EXISTENCE_PROB_378:0, DET_EXISTENCE_PROB_379:0, DET_EXISTENCE_PROB_380:0, DET_HVC_FLAG_377:0, DET_HVC_FLAG_378:0, DET_HVC_FLAG_379:0, DET_HVC_FLAG_380:0, DET_IDM_377:0, DET_IDM_378:0, DET_IDM_379:0, DET_IDM_380:0, DET_MH_CRC16_377_380:0, DET_MH_CYCLE_COUNTER_377_380:0, DET_MH_SCAN_INDEX_4LSB_377_380:0, DET_MTD_377:0, DET_MTD_378:0, DET_MTD_379:0, DET_MTD_380:0, DET_PROB_1STAZHYPO_377:0, DET_PROB_1STAZHYPO_378:0, DET_PROB_1STAZHYPO_379:0, DET_PROB_1STAZHYPO_380:0, DET_RANGE_377:0, DET_RANGE_378:0, DET_RANGE_379:0, DET_RANGE_380:0, DET_RANGE_ERR_377:0, DET_RANGE_ERR_378:0, DET_RANGE_ERR_379:0, DET_RANGE_ERR_380:0, DET_RANGE_VELOCITY_377:16384, DET_RANGE_VELOCITY_378:16384, DET_RANGE_VELOCITY_379:16384, DET_RANGE_VELOCITY_380:16384, DET_RANGE_VELOCITY_ERR_377:0, DET_RANGE_VELOCITY_ERR_378:0, DET_RANGE_VELOCITY_ERR_379:0, DET_RANGE_VELOCITY_ERR_380:0, DET_RCS_377:128, DET_RCS_378:128, DET_RCS_379:128, DET_RCS_380:128, DET_SNR_377:0, DET_SNR_378:0, DET_SNR_379:0, DET_SNR_380:0, DET_SUPER_RES_TARGET_377:0, DET_SUPER_RES_TARGET_378:0, DET_SUPER_RES_TARGET_379:0, DET_SUPER_RES_TARGET_380:0]}, provided-interface=Pi_SG_Detections_377_380_AL
      Pp_SG_Detections_345_348_AL: nonqueued-sender-com-spec{data-element=Vdp_SG_Detections_345_348_AL, init-value=fields=[DET_AZIMUTH_345:0, DET_AZIMUTH_346:0, DET_AZIMUTH_347:0, DET_AZIMUTH_348:0, DET_AZIMUTH_ERR_345:0, DET_AZIMUTH_ERR_346:0, DET_AZIMUTH_ERR_347:0, DET_AZIMUTH_ERR_348:0, DET_BELOW_RAIN_THOLD_345:0, DET_BELOW_RAIN_THOLD_346:0, DET_BELOW_RAIN_THOLD_347:0, DET_BELOW_RAIN_THOLD_348:0, DET_BI_STATIC_FLAG_345:0, DET_BI_STATIC_FLAG_346:0, DET_BI_STATIC_FLAG_347:0, DET_BI_STATIC_FLAG_348:0, DET_CONFD_AZIMUTH_345:0, DET_CONFD_AZIMUTH_346:0, DET_CONFD_AZIMUTH_347:0, DET_CONFD_AZIMUTH_348:0, DET_CONFD_ELEVATION_345:0, DET_CONFD_ELEVATION_346:0, DET_CONFD_ELEVATION_347:0, DET_CONFD_ELEVATION_348:0, DET_ELEVATION_345:0, DET_ELEVATION_346:0, DET_ELEVATION_347:0, DET_ELEVATION_348:0, DET_ELEVATION_ERR_345:0, DET_ELEVATION_ERR_346:0, DET_ELEVATION_ERR_347:0, DET_ELEVATION_ERR_348:0, DET_EXISTENCE_PROB_345:0, DET_EXISTENCE_PROB_346:0, DET_EXISTENCE_PROB_347:0, DET_EXISTENCE_PROB_348:0, DET_HVC_FLAG_345:0, DET_HVC_FLAG_346:0, DET_HVC_FLAG_347:0, DET_HVC_FLAG_348:0, DET_IDM_345:0, DET_IDM_346:0, DET_IDM_347:0, DET_IDM_348:0, DET_MH_CRC16_345_348:0, DET_MH_CYCLE_COUNTER_345_348:0, DET_MH_SCAN_INDEX_4LSB_345_348:0, DET_MTD_345:0, DET_MTD_346:0, DET_MTD_347:0, DET_MTD_348:0, DET_PROB_1STAZHYPO_345:0, DET_PROB_1STAZHYPO_346:0, DET_PROB_1STAZHYPO_347:0, DET_PROB_1STAZHYPO_348:0, DET_RANGE_345:0, DET_RANGE_346:0, DET_RANGE_347:0, DET_RANGE_348:0, DET_RANGE_ERR_345:0, DET_RANGE_ERR_346:0, DET_RANGE_ERR_347:0, DET_RANGE_ERR_348:0, DET_RANGE_VELOCITY_345:16384, DET_RANGE_VELOCITY_346:16384, DET_RANGE_VELOCITY_347:16384, DET_RANGE_VELOCITY_348:16384, DET_RANGE_VELOCITY_ERR_345:0, DET_RANGE_VELOCITY_ERR_346:0, DET_RANGE_VELOCITY_ERR_347:0, DET_RANGE_VELOCITY_ERR_348:0, DET_RCS_345:128, DET_RCS_346:128, DET_RCS_347:128, DET_RCS_348:128, DET_SNR_345:0, DET_SNR_346:0, DET_SNR_347:0, DET_SNR_348:0, DET_SUPER_RES_TARGET_345:0, DET_SUPER_RES_TARGET_346:0, DET_SUPER_RES_TARGET_347:0, DET_SUPER_RES_TARGET_348:0]}, provided-interface=Pi_SG_Detections_345_348_AL
      Pp_SG_Detections_261_264_AL: nonqueued-sender-com-spec{data-element=Vdp_SG_Detections_261_264_AL, init-value=fields=[DET_AZIMUTH_261:0, DET_AZIMUTH_262:0, DET_AZIMUTH_263:0, DET_AZIMUTH_264:0, DET_AZIMUTH_ERR_261:0, DET_AZIMUTH_ERR_262:0, DET_AZIMUTH_ERR_263:0, DET_AZIMUTH_ERR_264:0, DET_BELOW_RAIN_THOLD_261:0, DET_BELOW_RAIN_THOLD_262:0, DET_BELOW_RAIN_THOLD_263:0, DET_BELOW_RAIN_THOLD_264:0, DET_BI_STATIC_FLAG_261:0, DET_BI_STATIC_FLAG_262:0, DET_BI_STATIC_FLAG_263:0, DET_BI_STATIC_FLAG_264:0, DET_CONFD_AZIMUTH_261:0, DET_CONFD_AZIMUTH_262:0, DET_CONFD_AZIMUTH_263:0, DET_CONFD_AZIMUTH_264:0, DET_CONFD_ELEVATION_261:0, DET_CONFD_ELEVATION_262:0, DET_CONFD_ELEVATION_263:0, DET_CONFD_ELEVATION_264:0, DET_ELEVATION_261:0, DET_ELEVATION_262:0, DET_ELEVATION_263:0, DET_ELEVATION_264:0, DET_ELEVATION_ERR_261:0, DET_ELEVATION_ERR_262:0, DET_ELEVATION_ERR_263:0, DET_ELEVATION_ERR_264:0, DET_EXISTENCE_PROB_261:0, DET_EXISTENCE_PROB_262:0, DET_EXISTENCE_PROB_263:0, DET_EXISTENCE_PROB_264:0, DET_HVC_FLAG_261:0, DET_HVC_FLAG_262:0, DET_HVC_FLAG_263:0, DET_HVC_FLAG_264:0, DET_IDM_261:0, DET_IDM_262:0, DET_IDM_263:0, DET_IDM_264:0, DET_MH_CRC16_261_264:0, DET_MH_CYCLE_COUNTER_261_264:0, DET_MH_SCAN_INDEX_4LSB_261_264:0, DET_MTD_261:0, DET_MTD_262:0, DET_MTD_263:0, DET_MTD_264:0, DET_PROB_1STAZHYPO_261:0, DET_PROB_1STAZHYPO_262:0, DET_PROB_1STAZHYPO_263:0, DET_PROB_1STAZHYPO_264:0, DET_RANGE_261:0, DET_RANGE_262:0, DET_RANGE_263:0, DET_RANGE_264:0, DET_RANGE_ERR_261:0, DET_RANGE_ERR_262:0, DET_RANGE_ERR_263:0, DET_RANGE_ERR_264:0, DET_RANGE_VELOCITY_261:16384, DET_RANGE_VELOCITY_262:16384, DET_RANGE_VELOCITY_263:16384, DET_RANGE_VELOCITY_264:16384, DET_RANGE_VELOCITY_ERR_261:0, DET_RANGE_VELOCITY_ERR_262:0, DET_RANGE_VELOCITY_ERR_263:0, DET_RANGE_VELOCITY_ERR_264:0, DET_RCS_261:128, DET_RCS_262:128, DET_RCS_263:128, DET_RCS_264:128, DET_SNR_261:0, DET_SNR_262:0, DET_SNR_263:0, DET_SNR_264:0, DET_SUPER_RES_TARGET_261:0, DET_SUPER_RES_TARGET_262:0, DET_SUPER_RES_TARGET_263:0, DET_SUPER_RES_TARGET_264:0]}, provided-interface=Pi_SG_Detections_261_264_AL
      Pp_SG_Detections_357_360_AL: nonqueued-sender-com-spec{data-element=Vdp_SG_Detections_357_360_AL, init-value=fields=[DET_AZIMUTH_357:0, DET_AZIMUTH_358:0, DET_AZIMUTH_359:0, DET_AZIMUTH_360:0, DET_AZIMUTH_ERR_357:0, DET_AZIMUTH_ERR_358:0, DET_AZIMUTH_ERR_359:0, DET_AZIMUTH_ERR_360:0, DET_BELOW_RAIN_THOLD_357:0, DET_BELOW_RAIN_THOLD_358:0, DET_BELOW_RAIN_THOLD_359:0, DET_BELOW_RAIN_THOLD_360:0, DET_BI_STATIC_FLAG_357:0, DET_BI_STATIC_FLAG_358:0, DET_BI_STATIC_FLAG_359:0, DET_BI_STATIC_FLAG_360:0, DET_CONFD_AZIMUTH_357:0, DET_CONFD_AZIMUTH_358:0, DET_CONFD_AZIMUTH_359:0, DET_CONFD_AZIMUTH_360:0, DET_CONFD_ELEVATION_357:0, DET_CONFD_ELEVATION_358:0, DET_CONFD_ELEVATION_359:0, DET_CONFD_ELEVATION_360:0, DET_ELEVATION_357:0, DET_ELEVATION_358:0, DET_ELEVATION_359:0, DET_ELEVATION_360:0, DET_ELEVATION_ERR_357:0, DET_ELEVATION_ERR_358:0, DET_ELEVATION_ERR_359:0, DET_ELEVATION_ERR_360:0, DET_EXISTENCE_PROB_357:0, DET_EXISTENCE_PROB_358:0, DET_EXISTENCE_PROB_359:0, DET_EXISTENCE_PROB_360:0, DET_HVC_FLAG_357:0, DET_HVC_FLAG_358:0, DET_HVC_FLAG_359:0, DET_HVC_FLAG_360:0, DET_IDM_357:0, DET_IDM_358:0, DET_IDM_359:0, DET_IDM_360:0, DET_MH_CRC16_357_360:0, DET_MH_CYCLE_COUNTER_357_360:0, DET_MH_SCAN_INDEX_4LSB_357_360:0, DET_MTD_357:0, DET_MTD_358:0, DET_MTD_359:0, DET_MTD_360:0, DET_PROB_1STAZHYPO_357:0, DET_PROB_1STAZHYPO_358:0, DET_PROB_1STAZHYPO_359:0, DET_PROB_1STAZHYPO_360:0, DET_RANGE_357:0, DET_RANGE_358:0, DET_RANGE_359:0, DET_RANGE_360:0, DET_RANGE_ERR_357:0, DET_RANGE_ERR_358:0, DET_RANGE_ERR_359:0, DET_RANGE_ERR_360:0, DET_RANGE_VELOCITY_357:16384, DET_RANGE_VELOCITY_358:16384, DET_RANGE_VELOCITY_359:16384, DET_RANGE_VELOCITY_360:16384, DET_RANGE_VELOCITY_ERR_357:0, DET_RANGE_VELOCITY_ERR_358:0, DET_RANGE_VELOCITY_ERR_359:0, DET_RANGE_VELOCITY_ERR_360:0, DET_RCS_357:128, DET_RCS_358:128, DET_RCS_359:128, DET_RCS_360:128, DET_SNR_357:0, DET_SNR_358:0, DET_SNR_359:0, DET_SNR_360:0, DET_SUPER_RES_TARGET_357:0, DET_SUPER_RES_TARGET_358:0, DET_SUPER_RES_TARGET_359:0, DET_SUPER_RES_TARGET_360:0]}, provided-interface=Pi_SG_Detections_357_360_AL
      Pp_SG_Detections_241_244_AL: nonqueued-sender-com-spec{data-element=Vdp_SG_Detections_241_244_AL, init-value=fields=[DET_AZIMUTH_241:0, DET_AZIMUTH_242:0, DET_AZIMUTH_243:0, DET_AZIMUTH_244:0, DET_AZIMUTH_ERR_241:0, DET_AZIMUTH_ERR_242:0, DET_AZIMUTH_ERR_243:0, DET_AZIMUTH_ERR_244:0, DET_BELOW_RAIN_THOLD_241:0, DET_BELOW_RAIN_THOLD_242:0, DET_BELOW_RAIN_THOLD_243:0, DET_BELOW_RAIN_THOLD_244:0, DET_BI_STATIC_FLAG_241:0, DET_BI_STATIC_FLAG_242:0, DET_BI_STATIC_FLAG_243:0, DET_BI_STATIC_FLAG_244:0, DET_CONFD_AZIMUTH_241:0, DET_CONFD_AZIMUTH_242:0, DET_CONFD_AZIMUTH_243:0, DET_CONFD_AZIMUTH_244:0, DET_CONFD_ELEVATION_241:0, DET_CONFD_ELEVATION_242:0, DET_CONFD_ELEVATION_243:0, DET_CONFD_ELEVATION_244:0, DET_ELEVATION_241:0, DET_ELEVATION_242:0, DET_ELEVATION_243:0, DET_ELEVATION_244:0, DET_ELEVATION_ERR_241:0, DET_ELEVATION_ERR_242:0, DET_ELEVATION_ERR_243:0, DET_ELEVATION_ERR_244:0, DET_EXISTENCE_PROB_241:0, DET_EXISTENCE_PROB_242:0, DET_EXISTENCE_PROB_243:0, DET_EXISTENCE_PROB_244:0, DET_HVC_FLAG_241:0, DET_HVC_FLAG_242:0, DET_HVC_FLAG_243:0, DET_HVC_FLAG_244:0, DET_IDM_241:0, DET_IDM_242:0, DET_IDM_243:0, DET_IDM_244:0, DET_MH_CRC16_241_244:0, DET_MH_CYCLE_COUNTER_241_244:0, DET_MH_SCAN_INDEX_4LSB_241_244:0, DET_MTD_241:0, DET_MTD_242:0, DET_MTD_243:0, DET_MTD_244:0, DET_PROB_1STAZHYPO_241:0, DET_PROB_1STAZHYPO_242:0, DET_PROB_1STAZHYPO_243:0, DET_PROB_1STAZHYPO_244:0, DET_RANGE_241:0, DET_RANGE_242:0, DET_RANGE_243:0, DET_RANGE_244:0, DET_RANGE_ERR_241:0, DET_RANGE_ERR_242:0, DET_RANGE_ERR_243:0, DET_RANGE_ERR_244:0, DET_RANGE_VELOCITY_241:16384, DET_RANGE_VELOCITY_242:16384, DET_RANGE_VELOCITY_243:16384, DET_RANGE_VELOCITY_244:16384, DET_RANGE_VELOCITY_ERR_241:0, DET_RANGE_VELOCITY_ERR_242:0, DET_RANGE_VELOCITY_ERR_243:0, DET_RANGE_VELOCITY_ERR_244:0, DET_RCS_241:128, DET_RCS_242:128, DET_RCS_243:128, DET_RCS_244:128, DET_SNR_241:0, DET_SNR_242:0, DET_SNR_243:0, DET_SNR_244:0, DET_SUPER_RES_TARGET_241:0, DET_SUPER_RES_TARGET_242:0, DET_SUPER_RES_TARGET_243:0, DET_SUPER_RES_TARGET_244:0]}, provided-interface=Pi_SG_Detections_241_244_AL
      Pp_SG_Detections_297_300_AL: nonqueued-sender-com-spec{data-element=Vdp_SG_Detections_297_300_AL, init-value=fields=[DET_AZIMUTH_297:0, DET_AZIMUTH_298:0, DET_AZIMUTH_299:0, DET_AZIMUTH_300:0, DET_AZIMUTH_ERR_297:0, DET_AZIMUTH_ERR_298:0, DET_AZIMUTH_ERR_299:0, DET_AZIMUTH_ERR_300:0, DET_BELOW_RAIN_THOLD_297:0, DET_BELOW_RAIN_THOLD_298:0, DET_BELOW_RAIN_THOLD_299:0, DET_BELOW_RAIN_THOLD_300:0, DET_BI_STATIC_FLAG_297:0, DET_BI_STATIC_FLAG_298:0, DET_BI_STATIC_FLAG_299:0, DET_BI_STATIC_FLAG_300:0, DET_CONFD_AZIMUTH_297:0, DET_CONFD_AZIMUTH_298:0, DET_CONFD_AZIMUTH_299:0, DET_CONFD_AZIMUTH_300:0, DET_CONFD_ELEVATION_297:0, DET_CONFD_ELEVATION_298:0, DET_CONFD_ELEVATION_299:0, DET_CONFD_ELEVATION_300:0, DET_ELEVATION_297:0, DET_ELEVATION_298:0, DET_ELEVATION_299:0, DET_ELEVATION_300:0, DET_ELEVATION_ERR_297:0, DET_ELEVATION_ERR_298:0, DET_ELEVATION_ERR_299:0, DET_ELEVATION_ERR_300:0, DET_EXISTENCE_PROB_297:0, DET_EXISTENCE_PROB_298:0, DET_EXISTENCE_PROB_299:0, DET_EXISTENCE_PROB_300:0, DET_HVC_FLAG_297:0, DET_HVC_FLAG_298:0, DET_HVC_FLAG_299:0, DET_HVC_FLAG_300:0, DET_IDM_297:0, DET_IDM_298:0, DET_IDM_299:0, DET_IDM_300:0, DET_MH_CRC16_297_300:0, DET_MH_CYCLE_COUNTER_297_300:0, DET_MH_SCAN_INDEX_4LSB_297_300:0, DET_MTD_297:0, DET_MTD_298:0, DET_MTD_299:0, DET_MTD_300:0, DET_PROB_1STAZHYPO_297:0, DET_PROB_1STAZHYPO_298:0, DET_PROB_1STAZHYPO_299:0, DET_PROB_1STAZHYPO_300:0, DET_RANGE_297:0, DET_RANGE_298:0, DET_RANGE_299:0, DET_RANGE_300:0, DET_RANGE_ERR_297:0, DET_RANGE_ERR_298:0, DET_RANGE_ERR_299:0, DET_RANGE_ERR_300:0, DET_RANGE_VELOCITY_297:16384, DET_RANGE_VELOCITY_298:16384, DET_RANGE_VELOCITY_299:16384, DET_RANGE_VELOCITY_300:16384, DET_RANGE_VELOCITY_ERR_297:0, DET_RANGE_VELOCITY_ERR_298:0, DET_RANGE_VELOCITY_ERR_299:0, DET_RANGE_VELOCITY_ERR_300:0, DET_RCS_297:128, DET_RCS_298:128, DET_RCS_299:128, DET_RCS_300:128, DET_SNR_297:0, DET_SNR_298:0, DET_SNR_299:0, DET_SNR_300:0, DET_SUPER_RES_TARGET_297:0, DET_SUPER_RES_TARGET_298:0, DET_SUPER_RES_TARGET_299:0, DET_SUPER_RES_TARGET_300:0]}, provided-interface=Pi_SG_Detections_297_300_AL
      Pp_SG_Detections_233_236_AL: nonqueued-sender-com-spec{data-element=Vdp_SG_Detections_233_236_AL, init-value=fields=[DET_AZIMUTH_233:0, DET_AZIMUTH_234:0, DET_AZIMUTH_235:0, DET_AZIMUTH_236:0, DET_AZIMUTH_ERR_233:0, DET_AZIMUTH_ERR_234:0, DET_AZIMUTH_ERR_235:0, DET_AZIMUTH_ERR_236:0, DET_BELOW_RAIN_THOLD_233:0, DET_BELOW_RAIN_THOLD_234:0, DET_BELOW_RAIN_THOLD_235:0, DET_BELOW_RAIN_THOLD_236:0, DET_BI_STATIC_FLAG_233:0, DET_BI_STATIC_FLAG_234:0, DET_BI_STATIC_FLAG_235:0, DET_BI_STATIC_FLAG_236:0, DET_CONFD_AZIMUTH_233:0, DET_CONFD_AZIMUTH_234:0, DET_CONFD_AZIMUTH_235:0, DET_CONFD_AZIMUTH_236:0, DET_CONFD_ELEVATION_233:0, DET_CONFD_ELEVATION_234:0, DET_CONFD_ELEVATION_235:0, DET_CONFD_ELEVATION_236:0, DET_ELEVATION_233:0, DET_ELEVATION_234:0, DET_ELEVATION_235:0, DET_ELEVATION_236:0, DET_ELEVATION_ERR_233:0, DET_ELEVATION_ERR_234:0, DET_ELEVATION_ERR_235:0, DET_ELEVATION_ERR_236:0, DET_EXISTENCE_PROB_233:0, DET_EXISTENCE_PROB_234:0, DET_EXISTENCE_PROB_235:0, DET_EXISTENCE_PROB_236:0, DET_HVC_FLAG_233:0, DET_HVC_FLAG_234:0, DET_HVC_FLAG_235:0, DET_HVC_FLAG_236:0, DET_IDM_233:0, DET_IDM_234:0, DET_IDM_235:0, DET_IDM_236:0, DET_MH_CRC16_233_236:0, DET_MH_CYCLE_COUNTER_233_236:0, DET_MH_SCAN_INDEX_4LSB_233_236:0, DET_MTD_233:0, DET_MTD_234:0, DET_MTD_235:0, DET_MTD_236:0, DET_PROB_1STAZHYPO_233:0, DET_PROB_1STAZHYPO_234:0, DET_PROB_1STAZHYPO_235:0, DET_PROB_1STAZHYPO_236:0, DET_RANGE_233:0, DET_RANGE_234:0, DET_RANGE_235:0, DET_RANGE_236:0, DET_RANGE_ERR_233:0, DET_RANGE_ERR_234:0, DET_RANGE_ERR_235:0, DET_RANGE_ERR_236:0, DET_RANGE_VELOCITY_233:16384, DET_RANGE_VELOCITY_234:16384, DET_RANGE_VELOCITY_235:16384, DET_RANGE_VELOCITY_236:16384, DET_RANGE_VELOCITY_ERR_233:0, DET_RANGE_VELOCITY_ERR_234:0, DET_RANGE_VELOCITY_ERR_235:0, DET_RANGE_VELOCITY_ERR_236:0, DET_RCS_233:128, DET_RCS_234:128, DET_RCS_235:128, DET_RCS_236:128, DET_SNR_233:0, DET_SNR_234:0, DET_SNR_235:0, DET_SNR_236:0, DET_SUPER_RES_TARGET_233:0, DET_SUPER_RES_TARGET_234:0, DET_SUPER_RES_TARGET_235:0, DET_SUPER_RES_TARGET_236:0]}, provided-interface=Pi_SG_Detections_233_236_AL
